VERSION ""

NS_ :

BS_:

BU_: VCM TCM OBDScanT2 ECM

BO_ 531 VCM_HorizonData_C02: 8 VCM
 SG_ HorizonData : 7|64@0+ (1,0) [0|0] ""  TCM

BO_ 1414 VCM_GPSData_C02: 24 VCM
 SG_ GPSData_sg_UB : 163|1@1+ (1,0) [0|1] ""  ECM,TCM
 SG_ GPSData_Altitude : 144|16@1+ (0.125,-2500) [-2500|5691.875] "m"  ECM,TCM
 SG_ GPSData_Time : 64|32@1+ (1,0) [0|4294967295] "s"  TCM,ECM
 SG_ GPSData_AntennaStat : 160|3@1+ (1,0) [0|0] ""  TCM,ECM
 SG_ GPSData_HDOP : 112|16@1+ (0.01,0) [0|655.35] ""  ECM,TCM
 SG_ GPSData_Longitude : 0|32@1+ (1E-007,-210) [-210|219.4967295] "deg"  ECM,TCM
 SG_ GPSData_Latitude : 32|32@1+ (1E-007,-210) [-210|219.4967295] "deg"  ECM,TCM
 SG_ GPSData_Direction : 96|16@1+ (0.0078125,0) [0|511.9921875] "deg"  TCM,ECM
 SG_ GPSData_VehSpeed : 128|16@1+ (0.00390625,0) [0|255.99609375] "Km_per_h"  TCM,ECM

BO_ 940 VCM_EnginestartAuth_C02: 16 VCM
 SG_ EngineStartAuth_stat : 0|128@1+ (1,0) [0|0] ""  ECM

BO_ 935 VCM_EncryptedGBunlock_C02: 16 VCM
 SG_ EncryptedGBUnlockAuth_stat : 0|128@1+ (1,0) [0|0] ""  TCM

BO_ 518 VCM_AdasisMapdata_C02: 8 VCM
 SG_ AdasisMapData : 7|64@0+ (1,0) [0|0] ""  TCM

BO_ 2671902706 TesterFuncDiagMsg_C02: 8 VCM
 SG_ FuncDiagDataTester_ISig_2 : 0|64@1+ (1,0) [0|0] ""  TCM,ECM

BO_ 2671902708 TesterFuncDiagMsgF4_C02: 8 VCM
 SG_ FuncDiagDataIntTesterF4_ISig_2 : 0|64@1+ (1,0) [0|0] ""  ECM,TCM

BO_ 1252 TECU_BB2_11P_FCM: 8 VCM
 SG_ TECU_BB2_11P_FCS : 0|64@1+ (1,0) [0|0] ""  TCM

BO_ 1251 TECU_BB2_11P: 284 TCM
 SG_ HillDataPkgTECU : 0|2272@1+ (1,0) [0|0] ""  VCM

BO_ 1463 TECU_BB2_07P: 8 TCM
 SG_ TECU_Available_Log : 0|8@1+ (1,0) [0|0] ""  VCM

BO_ 1445 TECU_BB2_06S: 12 TCM
 SG_ ECU5VIN_stat : 0|88@1+ (1,0) [0|0] ""  VCM

BO_ 938 TECU_BB2_05S: 16 TCM
 SG_ KeyID_EncryptedGBUnlockAuth : 0|128@1+ (1,0) [0|0] ""  VCM

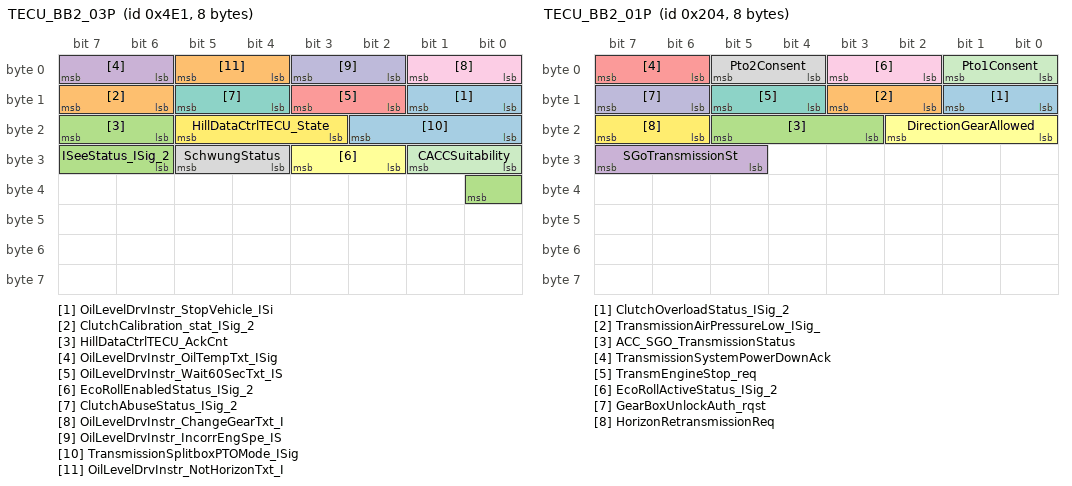
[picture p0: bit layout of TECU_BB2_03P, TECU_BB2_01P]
BO_ 1249 TECU_BB2_03P: 8 TCM
 SG_ OilLevelDrvInstr_StopVehicle_ISi : 8|2@1+ (1,0) [0|0] ""  VCM
 SG_ ClutchCalibration_stat_ISig_2 : 14|2@1+ (1,0) [0|0] ""  VCM
 SG_ HillDataCtrlTECU_AckCnt : 22|2@1+ (1,0) [0|3] ""  VCM
 SG_ OilLevelDrvInstr_OilTempTxt_ISig : 6|2@1+ (1,0) [0|0] ""  VCM
 SG_ OilLevelDrvInstr_Wait60SecTxt_IS : 10|2@1+ (1,0) [0|0] ""  VCM
 SG_ EcoRollEnabledStatus_ISig_2 : 26|2@1+ (1,0) [0|0] ""  VCM
 SG_ ClutchAbuseStatus_ISig_2 : 12|2@1+ (1,0) [0|0] ""  VCM
 SG_ SchwungStatus : 28|2@1+ (1,0) [0|0] ""  VCM
 SG_ OilLevelDrvInstr_ChangeGearTxt_I : 0|2@1+ (1,0) [0|0] ""  VCM
 SG_ OilLevelDrvInstr_IncorrEngSpe_IS : 2|2@1+ (1,0) [0|0] ""  VCM
 SG_ CACCSuitability : 24|2@1+ (1,0) [0|0] ""  VCM
 SG_ HillDataCtrlTECU_State : 19|3@1+ (1,0) [0|0] ""  VCM
 SG_ TransmissionSplitboxPTOMode_ISig : 16|3@1+ (1,0) [0|0] ""  VCM
 SG_ OilLevelDrvInstr_NotHorizonTxt_I : 4|2@1+ (1,0) [0|0] ""  VCM
 SG_ ISeeStatus_ISig_2 : 30|3@1+ (1,0) [0|0] ""  VCM

BO_ 1041 TECU_BB2_02P: 24 TCM
 SG_ BrakeInterlockStatus_ISig_2 : 42|2@1+ (1,0) [0|0] ""  VCM
 SG_ AutGearSplitPosition_ISig_2 : 46|3@1+ (1,0) [0|0] ""  VCM
 SG_ AutoWheelBrakesDownshiftSugges_I : 55|2@1+ (1,0) [0|0] ""  VCM
 SG_ GearShiftingRec_Direction_ISig_2 : 49|3@1+ (1,0) [0|0] ""  VCM
 SG_ DriveModeSwitchUserOverride_ISig : 80|3@1+ (1,0) [0|0] ""  VCM
 SG_ TransmissionBrakeMode_ISig_2 : 60|2@1+ (1,0) [0|0] ""  VCM
 SG_ WheelSpdReverseCapMin : 72|8@1+ (0.1,-25) [-25|0.5] "Km_per_h"  VCM
 SG_ DrivingMode : 0|16@1+ (1,0) [0|0] ""  VCM
 SG_ KickDownModeActive : 44|2@1+ (1,0) [0|0] ""  VCM
 SG_ ClutchWearStatus : 16|8@1+ (0.4,0) [0|102] "Percent"  VCM
 SG_ AutoWheelBrakeInhibited : 38|2@1+ (1,0) [0|0] ""  VCM,ECM
 SG_ TransmissionDrivingMode_ISig_2 : 57|3@1+ (1,0) [0|0] ""  VCM
 SG_ TrafficSitPathExecSta_Distance : 101|14@1+ (1,0) [0|16383] "m"  VCM
 SG_ FuelEcoDrvStatus : 40|2@1+ (1,0) [0|0] ""  VCM
 SG_ TransmissionOilTempHigh_ISig_2 : 35|3@1+ (1,0) [0|0] ""  VCM
 SG_ AvailableGearsWithLowerRatio_ISi : 24|4@1+ (1,0) [0|15] "Count"  VCM
 SG_ TrafficSitPathExecSta_Type : 83|8@1+ (1,0) [0|0] ""  VCM
 SG_ EcoCruiseStatus : 32|3@1+ (1,0) [0|0] ""  ECM,VCM
 SG_ AvailableGearsWithHigherRatio_IS : 28|4@1+ (1,0) [0|15] "Count"  VCM
 SG_ WheelSpdForwardCapMin : 64|8@1+ (0.1,0) [0|25.5] "Km_per_h"  VCM
 SG_ TrafficSitPathExecSta_Speed : 91|10@1+ (0.25,0) [0|255.75] "Km_per_h"  VCM
 SG_ GearShiftingRec_Steps_ISig_2 : 52|3@1+ (1,0) [0|0] ""  VCM

BO_ 516 TECU_BB2_01P: 8 TCM
 SG_ ClutchOverloadStatus_ISig_2 : 8|2@1+ (1,0) [0|0] ""  VCM
 SG_ TransmissionAirPressureLow_ISig_ : 10|2@1+ (1,0) [0|0] ""  VCM
 SG_ ACC_SGO_TransmissionStatus : 19|3@1+ (1,0) [0|0] ""  VCM,ECM
 SG_ SGoTransmissionSt : 29|3@1+ (1,0) [0|0] ""  ECM,VCM
 SG_ TransmissionSystemPowerDownAck : 6|2@1+ (1,0) [0|0] ""  VCM
 SG_ DirectionGearAllowed : 16|3@1+ (1,0) [0|0] ""  VCM
 SG_ TransmEngineStop_req : 12|2@1+ (1,0) [0|0] ""  VCM,ECM
 SG_ Pto2Consent : 4|2@1+ (1,0) [0|0] ""  VCM
 SG_ EcoRollActiveStatus_ISig_2 : 2|2@1+ (1,0) [0|0] ""  VCM
 SG_ GearBoxUnlockAuth_rqst : 14|2@1+ (1,0) [0|0] ""  VCM
 SG_ Pto1Consent : 0|2@1+ (1,0) [0|0] ""  VCM
 SG_ HorizonRetransmissionReq : 22|2@1+ (1,0) [0|0] ""  VCM

BO_ 522 TCM_P02_C02: 8 TCM
 SG_ TransmEstimatedTimeToShift : 0|16@1+ (0.00390625,0) [0|255.99609375] "s"  VCM

BO_ 2671833624 PhysDiagRespMsg_F2_18_C02: 8 TCM
 SG_ PhysDiagRespSig_F2_18_ISig_2 : 0|64@1+ (1,0) [0|0] ""  VCM

BO_ 2671833616 PhysDiagRespMsg_F2_10_C02: 8 ECM
 SG_ PhysDiagRespSig_F2_10_ISig_2 : 0|64@1+ (1,0) [0|0] ""  VCM

BO_ 2564485392 PhysDiagRespMsg_F1_10_extra_C02: 8 ECM
 SG_ PhysDiagRespSig_F1_10_extra : 0|64@1+ (1,0) [0|0] ""  OBDScanT2

BO_ 2671833360 PhysDiagRespMsg_F1_10_C02: 8 ECM
 SG_ PhysDiagRespSig_F1_10_ISig_2 : 0|64@1+ (1,0) [0|0] ""  VCM

BO_ 2671778034 PhysDiagReqMsg_18_F2_C02: 8 VCM
 SG_ PhysDiagReqSig_18_F2_ISig_2 : 0|64@1+ (1,0) [0|0] ""  TCM

BO_ 2671775986 PhysDiagReqMsg_10_F2_C02: 8 VCM
 SG_ PhysDiagReqSig_10_F2_ISig_2 : 0|64@1+ (1,0) [0|0] ""  ECM

BO_ 2564428017 PhysDiagReqMsg_10_F1_extra_C02: 8 OBDScanT2
 SG_ PhysDiagReqSig_10_F1_extra : 0|64@1+ (1,0) [0|0] ""  ECM

BO_ 2671775985 PhysDiagReqMsg_10_F1_C02: 8 VCM
 SG_ PhysDiagReqSig_10_F1_ISig_2 : 0|64@1+ (1,0) [0|0] ""  ECM

BO_ 2564502513 OBDFuncDiagMsg_extra_C02: 8 OBDScanT2
 SG_ FuncDiagDataOBD_extra : 0|64@1+ (1,0) [0|0] ""  ECM

BO_ 2671850481 OBDFuncDiagMsg_C02: 8 VCM
 SG_ FuncDiagDataOBD_ISig_2 : 0|64@1+ (1,0) [0|0] ""  ECM

BO_ 2633990180 NmAsr_VCM_C02: 1 VCM

BO_ 2633990168 NmAsr_TCM_C02: 1 TCM

BO_ 2633990160 NmAsr_ECM_C02: 1 ECM

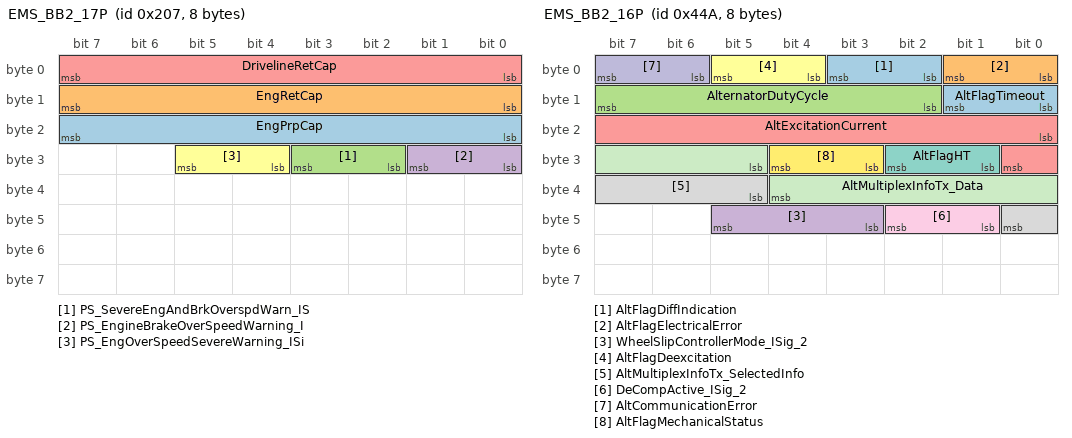
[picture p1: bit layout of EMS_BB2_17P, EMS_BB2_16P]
BO_ 519 EMS_BB2_17P: 8 ECM
 SG_ EngPrpCap : 16|8@1+ (1,-125) [-125|130] "Percent"  VCM
 SG_ EngRetCap : 8|8@1+ (1,-125) [-125|130] "Percent"  VCM
 SG_ PS_SevereEngAndBrkOverspdWarn_IS : 26|2@1+ (1,0) [0|0] ""  VCM
 SG_ PS_EngineBrakeOverSpeedWarning_I : 24|2@1+ (1,0) [0|0] ""  VCM
 SG_ DrivelineRetCap : 0|8@1+ (1,-125) [-125|130] "Percent"  VCM
 SG_ PS_EngOverSpeedSevereWarning_ISi : 28|2@1+ (1,0) [0|0] ""  VCM

BO_ 1098 EMS_BB2_16P: 8 ECM
 SG_ AltFlagDiffIndication : 2|2@1+ (1,0) [0|0] ""  VCM
 SG_ AltFlagElectricalError : 0|2@1+ (1,0) [0|0] ""  VCM
 SG_ AlternatorDutyCycle : 10|6@1+ (3.2258,0) [0|203.2254] "Percent"  VCM
 SG_ WheelSlipControllerMode_ISig_2 : 43|3@1+ (1,0) [0|0] ""  VCM
 SG_ AltExcitationCurrent : 16|9@1+ (0.05,0) [0|25.55] "A"  VCM
 SG_ AltFlagDeexcitation : 4|2@1+ (1,0) [0|0] ""  VCM
 SG_ AltFlagHT : 25|2@1+ (1,0) [0|0] ""  VCM
 SG_ AltMultiplexInfoTx_SelectedInfo : 37|4@1+ (1,0) [0|0] ""  VCM
 SG_ DeCompActive_ISig_2 : 41|2@1+ (1,0) [0|0] ""  VCM
 SG_ AltCommunicationError : 6|2@1+ (1,0) [0|0] ""  VCM
 SG_ AltMultiplexInfoTx_Data : 29|8@1+ (1,0) [0|0] ""  VCM
 SG_ AltFlagMechanicalStatus : 27|2@1+ (1,0) [0|0] ""  VCM
 SG_ AltFlagTimeout : 8|2@1+ (1,0) [0|0] ""  VCM

BO_ 1288 EMS_BB2_15P: 48 ECM
 SG_ EcoCruisePwtMaxOvSpeedLev2_ISig_ : 5|5@1+ (1,0) [0|31] "Km_per_h"  VCM
 SG_ EcoCruisePwtMaxOvSpeedLev0_ISig_ : 0|5@1+ (1,0) [0|31] "Km_per_h"  VCM
 SG_ AdblueTotalConsumed : 232|32@1+ (0.01,0) [0|42949672.95] "l"  VCM
 SG_ TotPTOLNGHighAccuracy : 64|32@1+ (0.01,0) [0|42949672.95] "kg"  VCM
 SG_ EcoCruisePwtMaxUnSpeedLev2_ISig_ : 43|5@1+ (1,0) [0|31] "Km_per_h"  VCM
 SG_ TimeLeftToVehSpdReductionFuel_IS : 137|9@1+ (15,0) [0|7665] "min"  VCM
 SG_ MIDistinctWarningExtEMS_ISig_2 : 169|4@1+ (1,0) [0|0] ""  VCM
 SG_ EcoCruisePwtMaxOvSpeedLev1_ISig_ : 11|5@1+ (1,0) [0|31] "Km_per_h"  VCM
 SG_ EcoCruisePwtMaxUnSpeedLev0_ISig_ : 32|5@1+ (1,0) [0|31] "Km_per_h"  VCM
 SG_ TopGearUseDistance_ISig_2 : 200|32@1+ (0.01,0) [0|42949672.95] "km"  VCM
 SG_ TorqueReductionStatus_OBD_ISig_2 : 164|3@1+ (1,0) [0|0] ""  VCM
 SG_ TimeLeftToTorqueReductionFuel_IS : 128|9@1+ (12,0) [0|6132] "min"  VCM
 SG_ OBDDrivingCycle : 48|16@1+ (1,0) [0|0] ""  VCM
 SG_ TimetoCompleteParkRegen_ISig_2 : 146|9@1+ (15,0) [0|7665] "min"  VCM
 SG_ MIStatus : 173|2@1+ (1,0) [0|0] ""  VCM
 SG_ SCROperatorInducementSeverity_IS : 180|3@1+ (1,0) [0|0] ""  VCM
 SG_ TimeLeftToTorqueReduction_OBD_IS : 155|9@1+ (12,0) [0|6132] "min"  VCM
 SG_ EMS_Available_Log : 192|8@1+ (1,0) [0|0] ""  VCM
 SG_ FuelOperatorDeratingSeverity_ISi : 40|3@1+ (1,0) [0|0] ""  VCM
 SG_ MIDistinctWarning_ISig_2 : 167|2@1+ (1,0) [0|0] ""  VCM
 SG_ SCROperatorInducementReason_ISig : 177|3@1+ (1,0) [0|0] ""  VCM
 SG_ StarterMotorActivations : 96|32@1+ (1,0) [0|4294967295] "Count"  VCM
 SG_ EcoCruisePwtMaxUnSpeedLev1_ISig_ : 21|5@1+ (1,0) [0|31] "Km_per_h"  VCM
 SG_ MIStatusExtEMS_ISig_2 : 175|2@1+ (1,0) [0|0] ""  VCM
 SG_ EcoCruisePwtMaxUnSpeedLev3_ISig_ : 27|5@1+ (1,0) [0|31] "Km_per_h"  VCM
 SG_ EcoCruisePwtMaxOvSpeedLev3_ISig_ : 16|5@1+ (1,0) [0|31] "Km_per_h"  VCM
 SG_ DistLeftToSevereInducement_OBD_I : 184|8@1+ (5,0) [0|1275] "km"  VCM
 SG_ FuelOperatorDeratingReason_ISig_ : 38|2@1+ (1,0) [0|0] ""  VCM

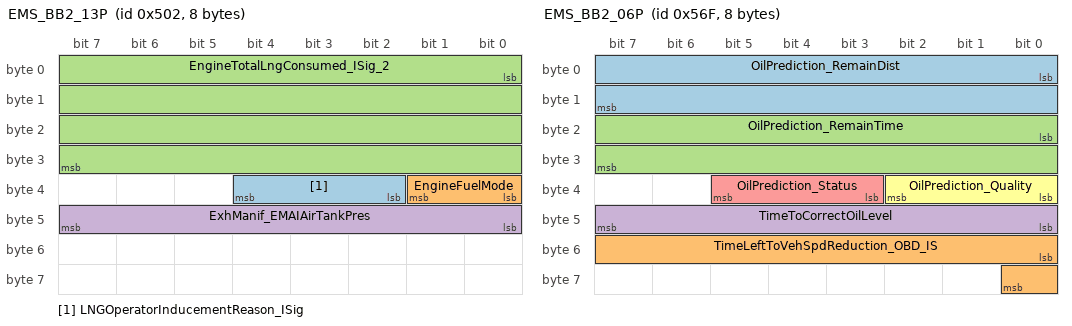
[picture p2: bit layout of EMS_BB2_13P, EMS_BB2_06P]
BO_ 1282 EMS_BB2_13P: 8 ECM
 SG_ LNGOperatorInducementReason_ISig : 34|3@1+ (1,0) [0|0] ""  VCM
 SG_ EngineFuelMode : 32|2@1+ (1,0) [0|0] ""  VCM
 SG_ EngineTotalLngConsumed_ISig_2 : 0|32@1+ (0.01,0) [0|42949672.95] "kg"  VCM
 SG_ ExhManif_EMAIAirTankPres : 40|8@1+ (8,0) [0|2040] "kPa"  VCM

BO_ 958 EMS_BB2_11S: 16 ECM
 SG_ KeyID_EngineStartAuth : 0|128@1+ (1,0) [0|0] ""  VCM

BO_ 1341 EMS_BB2_09S: 12 ECM
 SG_ ECU4VIN_stat : 0|88@1+ (1,0) [0|0] ""  VCM

BO_ 1392 EMS_BB2_08P: 8 ECM
 SG_ EngineRunningTime_ISig_2 : 0|32@1+ (1,0) [0|4294967295] "s"  VCM
 SG_ TotPTOFuelHighAccuracy : 32|32@1+ (0.01,0) [0|42949672.95] "l"  VCM

BO_ 1391 EMS_BB2_06P: 8 ECM
 SG_ OilPrediction_RemainDist : 0|16@1+ (10,0) [0|655350] "km"  VCM
 SG_ TimeLeftToVehSpdReduction_OBD_IS : 48|9@1+ (15,0) [0|7665] "min"  VCM
 SG_ OilPrediction_RemainTime : 16|16@1+ (1,0) [0|65535] "h"  VCM
 SG_ TimeToCorrectOilLevel : 40|8@1+ (1,0) [0|255] "min"  VCM
 SG_ OilPrediction_Status : 35|3@1+ (1,0) [0|0] ""  VCM
 SG_ OilPrediction_Quality : 32|3@1+ (1,0) [0|0] ""  VCM

BO_ 1279 EMS_BB2_03P: 24 ECM
 SG_ AirFilterPressureDrop : 3|3@1+ (1,0) [0|0] ""  VCM
 SG_ EngineTotalFuelConsumed_ISig_2 : 96|32@1+ (0.01,0) [0|42949672.95] "l"  VCM,TCM
 SG_ FuelFilterClogged_ISig_2 : 0|3@1+ (1,0) [0|0] ""  VCM
 SG_ CoolantPumpEngagementStatus_ISig : 184|8@1+ (0.4,0) [0|102] "Percent"  VCM
 SG_ BarometricPressure_ISig_2 : 80|8@1+ (0.5,0) [0|127.5] "kPa"  TCM,VCM
 SG_ StarterMotorRecoveryTime_ISig_2 : 16|16@1+ (1,0) [0|65535] "s"  VCM
 SG_ CoolantTempGaugeAdjustment_ISig_ : 56|8@1+ (0.4,0) [0|102] "Percent"  VCM
 SG_ DrainPrimingStatus_ISig_2 : 72|3@1+ (1,0) [0|0] ""  VCM
 SG_ CoolantLevelLow : 64|3@1+ (1,0) [0|0] ""  VCM
 SG_ AverageFuelEconomy_ISig_2 : 128|16@1+ (0.00390625,0) [0|255.99609375] "miles_per_gallon"  VCM
 SG_ EngineProtDerateStat : 6|2@1+ (1,0) [0|0] ""  VCM
 SG_ EngineAirInletTemperature : 8|8@1+ (1,-40) [-40|215] "DegreeC"  VCM
 SG_ FuelEcoEngStatus : 176|2@1+ (1,0) [0|0] ""  VCM
 SG_ OilLevelLow_ISig_2 : 88|3@1+ (1,0) [0|0] ""  VCM
 SG_ AutoWheelBrakesStatus_ISig_2 : 91|3@1+ (1,0) [0|0] ""  VCM,TCM
 SG_ EngineFanOverspeed_ISig_2 : 48|2@1+ (1,0) [0|0] ""  VCM
 SG_ InletAirHeaterStatus1_ISig_2 : 70|2@1+ (1,0) [0|0] ""  VCM
 SG_ TopGearMode : 78|2@1+ (1,0) [0|0] ""  VCM
 SG_ CoolantTempHigh_ISig_2 : 67|3@1+ (1,0) [0|0] ""  VCM
 SG_ AppliedVehicleSpeedLimit : 32|16@1+ (0.00390625,0) [0|255.99609375] "Km_per_h"  TCM,VCM
 SG_ EnergyForNextCrank_ISig_2 : 52|4@1+ (1,0) [0|15] "Wh"  VCM
 SG_ OilPressureLow_ISig_2 : 75|3@1+ (1,0) [0|0] ""  VCM
 SG_ DPF_ParkedRegenStatus_ISig_2 : 178|3@1+ (1,0) [0|0] ""  VCM
 SG_ StarterMotorReset_ack : 50|2@1+ (1,0) [0|0] ""  VCM
 SG_ EngineCoolingFanSpeed_ISig_2 : 144|16@1+ (1,0) [0|65535] "rpm"  VCM
 SG_ EngineGasRate : 160|16@1+ (0.05,0) [0|3276.75] "Kg_per_h"  VCM
 SG_ DMSDriverFollow : 182|2@1+ (1,0) [0|0] ""  VCM

BO_ 719 EMS_BB2_01P: 16 ECM
 SG_ XARActiveControlMode : 58|3@1+ (1,0) [0|0] ""  VCM
 SG_ WarmUpCycle : 21|2@1+ (1,0) [0|0] ""  VCM
 SG_ DeterminedGear : 48|8@1+ (1,-125) [-125|130] "GearValue"  VCM
 SG_ DPF_LimitedSpeedDuetoInhibit_ISi : 77|3@1+ (1,0) [0|0] ""  VCM
 SG_ AirFilter_Pressure : 80|11@1+ (0.01,-10) [-10|10.47] "kPa"  VCM
 SG_ CCControllerMode : 0|3@1+ (1,0) [0|0] ""  VCM
 SG_ ExhManif_AirInjActive : 56|2@1+ (1,0) [0|0] ""  VCM
 SG_ AirFilter_AirMassFlowValidated : 91|8@1+ (0.01,0) [0|2.55] "Kg_Per_s"  VCM
 SG_ CCBControllerMode : 11|3@1+ (1,0) [0|0] ""  VCM
 SG_ CCSetSpeedApplied : 40|8@1+ (1,0) [0|255] "Km_per_h"  VCM
 SG_ EngineSystemPowerDownAck : 28|2@1+ (1,0) [0|0] ""  VCM
 SG_ RegenInhibDueHeight_ISig_2 : 62|2@1+ (1,0) [0|0] ""  VCM
 SG_ XARSystemState : 23|2@1+ (1,0) [0|0] ""  VCM
 SG_ EngineStartAuth_rqst : 3|3@1+ (1,0) [0|0] ""  VCM
 SG_ EngCompartmentStopSwitchStat : 6|2@1+ (1,0) [0|0] ""  VCM
 SG_ PwtEngineTmpryStopAllowed : 25|2@1+ (1,0) [0|0] ""  VCM
 SG_ IntakeAirTemperatureAlert : 14|2@1+ (1,0) [0|0] ""  VCM
 SG_ EngineOilTempHigh_ISig_2 : 16|3@1+ (1,0) [0|0] ""  VCM
 SG_ XRSLControllerMode_ISig_2 : 19|2@1+ (1,0) [0|0] ""  VCM
 SG_ InhibitIdleShutdownStatus : 8|3@1+ (1,0) [0|0] ""  VCM
 SG_ CrankcasePressureHigh : 30|2@1+ (1,0) [0|0] ""  VCM
 SG_ CCBSetSpeedApplied : 64|8@1+ (1,0) [0|255] "Km_per_h"  VCM
 SG_ EngineAirInletPressure : 32|8@1+ (2,0) [0|510] "kPa"  VCM

BO_ 2671964696 DiagUUDTRespMsg1_F2_18_C02: 8 TCM
 SG_ DiagUUDTRespSig_F2_18_ISig_2 : 0|64@1+ (1,0) [0|0] ""  VCM

BO_ 2671964688 DiagUUDTRespMsg1_F2_10_C02: 8 ECM
 SG_ DiagUUDTRespSig_F2_10_ISig_2 : 0|64@1+ (1,0) [0|0] ""  VCM

BO_ 2671834136 DiagRespMsgForIntTest_F4_18_C02: 8 TCM
 SG_ InternalTesterDiagSig_F4_18 : 0|64@1+ (1,0) [0|0] ""  VCM

BO_ 2671834128 DiagRespMsgForIntTest_F4_10_C02: 8 ECM
 SG_ InternalTesterDiagSig_F4_10 : 0|64@1+ (1,0) [0|0] ""  VCM

BO_ 2671778036 DiagReqMsgOfIntTest_18_F4_C02: 8 VCM
 SG_ InternalTesterDiagSig_18_F4 : 0|64@1+ (1,0) [0|0] ""  TCM

BO_ 2671775988 DiagReqMsgOfIntTest_10_F4_C02: 8 VCM
 SG_ InternalTesterDiagSig_10_F4 : 0|64@1+ (1,0) [0|0] ""  ECM

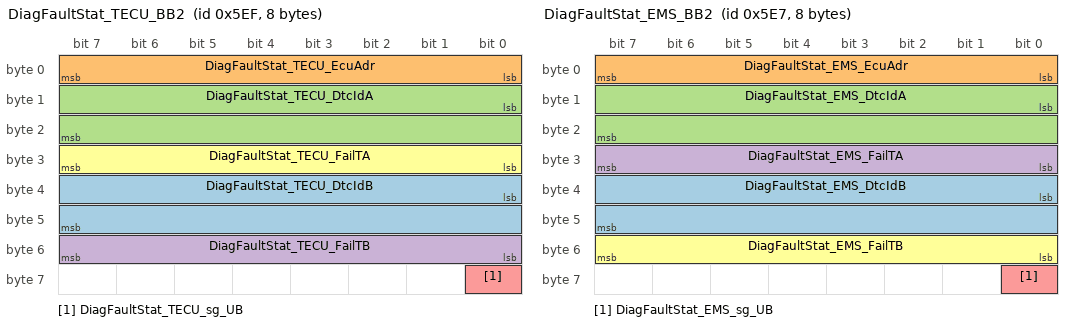
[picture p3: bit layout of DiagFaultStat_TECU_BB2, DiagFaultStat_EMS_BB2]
BO_ 1519 DiagFaultStat_TECU_BB2: 8 TCM
 SG_ DiagFaultStat_TECU_DtcIdB : 32|16@1+ (1,0) [0|65535] ""  VCM
 SG_ DiagFaultStat_TECU_EcuAdr : 0|8@1+ (1,0) [0|255] ""  VCM
 SG_ DiagFaultStat_TECU_DtcIdA : 8|16@1+ (1,0) [0|65535] ""  VCM
 SG_ DiagFaultStat_TECU_FailTB : 48|8@1+ (1,0) [0|255] ""  VCM
 SG_ DiagFaultStat_TECU_sg_UB : 56|1@1+ (1,0) [0|0] ""  VCM
 SG_ DiagFaultStat_TECU_FailTA : 24|8@1+ (1,0) [0|255] ""  VCM

BO_ 1511 DiagFaultStat_EMS_BB2: 8 ECM
 SG_ DiagFaultStat_EMS_DtcIdB : 32|16@1+ (1,0) [0|65535] ""  VCM
 SG_ DiagFaultStat_EMS_EcuAdr : 0|8@1+ (1,0) [0|255] ""  VCM
 SG_ DiagFaultStat_EMS_DtcIdA : 8|16@1+ (1,0) [0|65535] ""  VCM
 SG_ DiagFaultStat_EMS_FailTA : 24|8@1+ (1,0) [0|255] ""  VCM
 SG_ DiagFaultStat_EMS_sg_UB : 56|1@1+ (1,0) [0|0] ""  VCM
 SG_ DiagFaultStat_EMS_FailTB : 48|8@1+ (1,0) [0|255] ""  VCM

BO_ 1698 AnmMsg_VCM_C02: 8 VCM
 SG_ AnmSig_VCM_CAN02 : 0|32@1+ (1,0) [0|0] ""  TCM,ECM

BO_ 1696 AnmMsg_TCM_C02: 8 TCM
 SG_ AnmSig_TCM_CAN02 : 0|32@1+ (1,0) [0|0] ""  ECM,VCM

BO_ 1697 AnmMsg_ECM_C02: 8 ECM
 SG_ AnmSig_ECM_CAN02 : 0|32@1+ (1,0) [0|0] ""  VCM,TCM

CM_ SG_ 1414 GPSData_Time "4261412864 - 4278190079 Error ; 4278190080 - 4294967295 Not available";
CM_ SG_ 1414 GPSData_Longitude "4261412864-4278190079 Error ; 4278190080-4294967295 Not available";
CM_ SG_ 1414 GPSData_Latitude "4261412864-4278190079 Error ; 4278190080-4294967295 Not available";
CM_ SG_ 1414 GPSData_VehSpeed "65024 - 65279 Error ; 65280 - 65535 Not available";
CM_ SG_ 1391 OilPrediction_RemainDist "65024 - 65279 Error ; 65280 - 65535 Not available";
CM_ SG_ 1391 OilPrediction_RemainTime "65024 - 65279 Error ; 65280 - 65535 Not available";
BA_DEF_ BO_  "GenMsgStartDelayTime" INT 0 0;
BA_DEF_ BO_  "GenMsgDelayTime" INT 0 0;
BA_DEF_ BO_  "GenMsgCycleTime" INT 0 0;
BA_DEF_ BO_  "GenMsgSendType" ENUM  "Cyclic","NotUsed","NotUsed","NotUsed","NotUsed","NotUsed","NotUsed","IfActive","NoMsgSendType","NotUsed";
BA_DEF_ SG_  "GenSigStartValue" INT 0 0;
BA_DEF_ SG_  "GenSigCycleTimeActive" INT 0 0;
BA_DEF_ SG_  "GenSigCycleTime" INT 0 0;
BA_DEF_ SG_  "GenSigSendType" ENUM  "Cyclic","OnWrite","OnWriteWithRepetition","OnChange","OnChangeWithRepetition","IfActive","IfActiveWithRepetition","NoSigSendType","NotUsed","NotUsed","NotUsed","NotUsed","NotUsed";
BA_DEF_ BO_  "VFrameFormat" ENUM  "StandardCAN","ExtendedCAN","reserved","J1939PG","reserved","reserved","reserved","reserved","reserved","reserved","reserved","reserved","reserved","reserved","StandardCAN_FD","ExtendedCAN_FD";
BA_DEF_ SG_  "SigType" ENUM  "Default","Range","RangeSigned","ASCII","Discrete","Control","ReferencePGN","DTC","StringDelimiter","StringLength","StringLengthControl";
BA_DEF_ SG_  "SeToolVersion_SIGNAL" STRING ;
BA_DEF_ SG_  "SeToolUniqueID_SIGNAL" STRING ;
BA_DEF_ SG_  "SeToolOwnerSigGroup_SIGNAL" STRING ;
BA_DEF_ SG_  "SeToolOwnerSigGroupID_SIGNAL" STRING ;
BA_DEF_ SG_  "SeToolName_SIGNAL" STRING ;
BA_DEF_ SG_  "SeToolItemID_SIGNAL" STRING ;
BA_DEF_ SG_  "SeToolAncestorID_SIGNAL" STRING ;
BA_DEF_ SG_  "Platform_VMCU1_Sig" ENUM  "No","Yes";
BA_DEF_ BO_  "NmAsrMessage" ENUM  "No","Yes";
BA_DEF_ SG_  "MmAnSignal" ENUM  "No","Yes";
BA_DEF_ SG_  "GenSigMaxLatency" INT 0 65535;
BA_DEF_ SG_  "GenSigILSupport" ENUM  "Yes","No";
BA_DEF_ BO_  "GenMsgILSupport" ENUM  "No","Yes";
BA_DEF_ SG_  "E2EProfile" STRING ;
BA_DEF_ SG_  "E2EDataLength" INT 0 65535;
BA_DEF_ SG_  "E2EDataId" INT 0 65535;
BA_DEF_ BO_  "DiagUUDTResponse" ENUM  "No","Yes";
BA_DEF_ BO_  "DiagState" ENUM  "No","Yes";
BA_DEF_ BO_  "DiagResponse" ENUM  "No","Yes";
BA_DEF_ BO_  "DiagRequest" ENUM  "No","Yes";
BA_DEF_ BO_  "DiagConnection" HEX 0 65535;
BA_DEF_ BO_  "CanTpFcFrameId" HEX 0 2147483647;
BA_DEF_ BO_  "CanTpBs" INT 0 255;
BA_DEF_ BO_  "CANFD_BRS" ENUM  "0","1";
BA_DEF_ SG_  "SystemSignalLongSymbol" STRING ;
BA_DEF_REL_ BU_SG_REL_  "GenSigTimeoutTime" INT 0 65535;
BA_DEF_REL_ BU_SG_REL_  "GenSigFirstTimeoutTime" INT 0 65535;
BA_DEF_DEF_  "GenMsgStartDelayTime" 0;
BA_DEF_DEF_  "GenMsgDelayTime" 0;
BA_DEF_DEF_  "GenMsgCycleTime" 0;
BA_DEF_DEF_  "GenMsgSendType" "Cyclic";
BA_DEF_DEF_  "GenSigStartValue" 0;
BA_DEF_DEF_  "GenSigCycleTimeActive" 0;
BA_DEF_DEF_  "GenSigCycleTime" 0;
BA_DEF_DEF_  "GenSigSendType" "Cyclic";
BA_DEF_DEF_  "VFrameFormat" "ExtendedCAN";
BA_DEF_DEF_  "SigType" "Default";
BA_DEF_DEF_  "SeToolVersion_SIGNAL" "";
BA_DEF_DEF_  "SeToolUniqueID_SIGNAL" "";
BA_DEF_DEF_  "SeToolOwnerSigGroup_SIGNAL" "";
BA_DEF_DEF_  "SeToolOwnerSigGroupID_SIGNAL" "";
BA_DEF_DEF_  "SeToolName_SIGNAL" "";
BA_DEF_DEF_  "SeToolItemID_SIGNAL" "";
BA_DEF_DEF_  "SeToolAncestorID_SIGNAL" "";
BA_DEF_DEF_  "Platform_VMCU1_Sig" "No";
BA_DEF_DEF_  "NmAsrMessage" "No";
BA_DEF_DEF_  "MmAnSignal" "No";
BA_DEF_DEF_  "GenSigMaxLatency" 0;
BA_DEF_DEF_  "GenSigILSupport" "Yes";
BA_DEF_DEF_  "GenMsgILSupport" "Yes";
BA_DEF_DEF_  "E2EProfile" "none";
BA_DEF_DEF_  "E2EDataLength" 0;
BA_DEF_DEF_  "E2EDataId" 0;
BA_DEF_DEF_  "DiagUUDTResponse" "No";
BA_DEF_DEF_  "DiagState" "No";
BA_DEF_DEF_  "DiagResponse" "No";
BA_DEF_DEF_  "DiagRequest" "No";
BA_DEF_DEF_  "DiagConnection" 0;
BA_DEF_DEF_  "CanTpFcFrameId" 2147483647;
BA_DEF_DEF_  "CanTpBs" 255;
BA_DEF_DEF_  "CANFD_BRS" "0";
BA_DEF_DEF_REL_ "GenSigTimeoutTime" 0;
BA_DEF_DEF_REL_ "GenSigFirstTimeoutTime" 0;
BA_DEF_DEF_  "SystemSignalLongSymbol" "";
BA_ "CANFD_BRS" BO_ 531 1;
BA_ "GenMsgSendType" BO_ 531 8;
BA_ "GenMsgDelayTime" BO_ 531 10;
BA_ "VFrameFormat" BO_ 531 14;
BA_ "CANFD_BRS" BO_ 1414 1;
BA_ "GenMsgCycleTime" BO_ 1414 500;
BA_ "GenMsgStartDelayTime" BO_ 1414 80;
BA_ "VFrameFormat" BO_ 1414 14;
BA_ "CANFD_BRS" BO_ 940 1;
BA_ "GenMsgSendType" BO_ 940 8;
BA_ "GenMsgDelayTime" BO_ 940 20;
BA_ "VFrameFormat" BO_ 940 14;
BA_ "CANFD_BRS" BO_ 935 1;
BA_ "GenMsgSendType" BO_ 935 8;
BA_ "GenMsgDelayTime" BO_ 935 20;
BA_ "VFrameFormat" BO_ 935 14;
BA_ "CANFD_BRS" BO_ 518 1;
BA_ "GenMsgSendType" BO_ 518 8;
BA_ "GenMsgDelayTime" BO_ 518 20;
BA_ "VFrameFormat" BO_ 518 14;
BA_ "DiagConnection" BO_ 2671902706 61976;
BA_ "DiagState" BO_ 2671902706 1;
BA_ "GenMsgILSupport" BO_ 2671902706 0;
BA_ "GenMsgSendType" BO_ 2671902706 8;
BA_ "DiagConnection" BO_ 2671902708 62719;
BA_ "DiagState" BO_ 2671902708 1;
BA_ "GenMsgILSupport" BO_ 2671902708 0;
BA_ "GenMsgSendType" BO_ 2671902708 8;
BA_ "CANFD_BRS" BO_ 1252 1;
BA_ "GenMsgILSupport" BO_ 1252 0;
BA_ "GenMsgSendType" BO_ 1252 8;
BA_ "VFrameFormat" BO_ 1252 14;
BA_ "CANFD_BRS" BO_ 1251 1;
BA_ "CanTpFcFrameId" BO_ 1251 1252;
BA_ "GenMsgSendType" BO_ 1251 8;
BA_ "GenMsgDelayTime" BO_ 1251 500;
BA_ "GenMsgStartDelayTime" BO_ 1251 50;
BA_ "VFrameFormat" BO_ 1251 14;
BA_ "CANFD_BRS" BO_ 1463 1;
BA_ "GenMsgCycleTime" BO_ 1463 5000;
BA_ "GenMsgStartDelayTime" BO_ 1463 235;
BA_ "VFrameFormat" BO_ 1463 14;
BA_ "CANFD_BRS" BO_ 1445 1;
BA_ "GenMsgSendType" BO_ 1445 8;
BA_ "GenMsgDelayTime" BO_ 1445 110;
BA_ "VFrameFormat" BO_ 1445 14;
BA_ "CANFD_BRS" BO_ 938 1;
BA_ "GenMsgSendType" BO_ 938 8;
BA_ "GenMsgDelayTime" BO_ 938 20;
BA_ "VFrameFormat" BO_ 938 14;
BA_ "CANFD_BRS" BO_ 1249 1;
BA_ "GenMsgCycleTime" BO_ 1249 500;
BA_ "GenMsgStartDelayTime" BO_ 1249 120;
BA_ "VFrameFormat" BO_ 1249 14;
BA_ "CANFD_BRS" BO_ 1041 1;
BA_ "GenMsgCycleTime" BO_ 1041 100;
BA_ "GenMsgStartDelayTime" BO_ 1041 10;
BA_ "VFrameFormat" BO_ 1041 14;
BA_ "CANFD_BRS" BO_ 516 1;
BA_ "GenMsgCycleTime" BO_ 516 25;
BA_ "GenMsgStartDelayTime" BO_ 516 5;
BA_ "VFrameFormat" BO_ 516 14;
BA_ "CANFD_BRS" BO_ 522 1;
BA_ "GenMsgCycleTime" BO_ 522 20;
BA_ "VFrameFormat" BO_ 522 14;
BA_ "DiagConnection" BO_ 2671833624 61976;
BA_ "DiagResponse" BO_ 2671833624 1;
BA_ "GenMsgILSupport" BO_ 2671833624 0;
BA_ "GenMsgSendType" BO_ 2671833624 8;
BA_ "DiagConnection" BO_ 2671833616 61968;
BA_ "DiagResponse" BO_ 2671833616 1;
BA_ "GenMsgILSupport" BO_ 2671833616 0;
BA_ "GenMsgSendType" BO_ 2671833616 8;
BA_ "DiagConnection" BO_ 2564485392 63504;
BA_ "DiagResponse" BO_ 2564485392 1;
BA_ "GenMsgILSupport" BO_ 2564485392 0;
BA_ "GenMsgSendType" BO_ 2564485392 8;
BA_ "DiagConnection" BO_ 2671833360 61712;
BA_ "DiagResponse" BO_ 2671833360 1;
BA_ "GenMsgILSupport" BO_ 2671833360 0;
BA_ "GenMsgSendType" BO_ 2671833360 8;
BA_ "DiagConnection" BO_ 2671778034 61976;
BA_ "DiagRequest" BO_ 2671778034 1;
BA_ "GenMsgILSupport" BO_ 2671778034 0;
BA_ "GenMsgSendType" BO_ 2671778034 8;
BA_ "DiagConnection" BO_ 2671775986 61968;
BA_ "DiagRequest" BO_ 2671775986 1;
BA_ "GenMsgILSupport" BO_ 2671775986 0;
BA_ "GenMsgSendType" BO_ 2671775986 8;
BA_ "DiagConnection" BO_ 2564428017 63504;
BA_ "DiagRequest" BO_ 2564428017 1;
BA_ "GenMsgILSupport" BO_ 2564428017 0;
BA_ "GenMsgSendType" BO_ 2564428017 8;
BA_ "DiagConnection" BO_ 2671775985 61712;
BA_ "DiagRequest" BO_ 2671775985 1;
BA_ "GenMsgILSupport" BO_ 2671775985 0;
BA_ "GenMsgSendType" BO_ 2671775985 8;
BA_ "DiagConnection" BO_ 2564502513 63504;
BA_ "DiagState" BO_ 2564502513 1;
BA_ "GenMsgILSupport" BO_ 2564502513 0;
BA_ "GenMsgSendType" BO_ 2564502513 8;
BA_ "DiagConnection" BO_ 2671850481 61712;
BA_ "DiagState" BO_ 2671850481 1;
BA_ "GenMsgILSupport" BO_ 2671850481 0;
BA_ "GenMsgSendType" BO_ 2671850481 8;
BA_ "CANFD_BRS" BO_ 2633990180 1;
BA_ "GenMsgILSupport" BO_ 2633990180 0;
BA_ "NmAsrMessage" BO_ 2633990180 1;
BA_ "GenMsgSendType" BO_ 2633990180 8;
BA_ "VFrameFormat" BO_ 2633990180 15;
BA_ "CANFD_BRS" BO_ 2633990168 1;
BA_ "GenMsgILSupport" BO_ 2633990168 0;
BA_ "NmAsrMessage" BO_ 2633990168 1;
BA_ "GenMsgSendType" BO_ 2633990168 8;
BA_ "VFrameFormat" BO_ 2633990168 15;
BA_ "CANFD_BRS" BO_ 2633990160 1;
BA_ "GenMsgILSupport" BO_ 2633990160 0;
BA_ "NmAsrMessage" BO_ 2633990160 1;
BA_ "GenMsgSendType" BO_ 2633990160 8;
BA_ "VFrameFormat" BO_ 2633990160 15;
BA_ "CANFD_BRS" BO_ 519 1;
BA_ "GenMsgCycleTime" BO_ 519 20;
BA_ "GenMsgStartDelayTime" BO_ 519 5;
BA_ "VFrameFormat" BO_ 519 14;
BA_ "CANFD_BRS" BO_ 1098 1;
BA_ "GenMsgCycleTime" BO_ 1098 100;
BA_ "GenMsgStartDelayTime" BO_ 1098 10;
BA_ "VFrameFormat" BO_ 1098 14;
BA_ "CANFD_BRS" BO_ 1288 1;
BA_ "GenMsgCycleTime" BO_ 1288 1000;
BA_ "GenMsgStartDelayTime" BO_ 1288 150;
BA_ "VFrameFormat" BO_ 1288 14;
BA_ "CANFD_BRS" BO_ 1282 1;
BA_ "GenMsgCycleTime" BO_ 1282 500;
BA_ "GenMsgStartDelayTime" BO_ 1282 100;
BA_ "VFrameFormat" BO_ 1282 14;
BA_ "CANFD_BRS" BO_ 958 1;
BA_ "GenMsgSendType" BO_ 958 8;
BA_ "GenMsgDelayTime" BO_ 958 85;
BA_ "VFrameFormat" BO_ 958 14;
BA_ "CANFD_BRS" BO_ 1341 1;
BA_ "GenMsgSendType" BO_ 1341 8;
BA_ "GenMsgDelayTime" BO_ 1341 110;
BA_ "VFrameFormat" BO_ 1341 14;
BA_ "CANFD_BRS" BO_ 1392 1;
BA_ "GenMsgCycleTime" BO_ 1392 1000;
BA_ "GenMsgStartDelayTime" BO_ 1392 60;
BA_ "VFrameFormat" BO_ 1392 14;
BA_ "CANFD_BRS" BO_ 1391 1;
BA_ "GenMsgCycleTime" BO_ 1391 1500;
BA_ "GenMsgStartDelayTime" BO_ 1391 250;
BA_ "VFrameFormat" BO_ 1391 14;
BA_ "CANFD_BRS" BO_ 1279 1;
BA_ "GenMsgCycleTime" BO_ 1279 250;
BA_ "GenMsgStartDelayTime" BO_ 1279 5;
BA_ "VFrameFormat" BO_ 1279 14;
BA_ "CANFD_BRS" BO_ 719 1;
BA_ "GenMsgCycleTime" BO_ 719 50;
BA_ "GenMsgStartDelayTime" BO_ 719 20;
BA_ "VFrameFormat" BO_ 719 14;
BA_ "DiagConnection" BO_ 2671964696 61976;
BA_ "DiagUUDTResponse" BO_ 2671964696 1;
BA_ "GenMsgILSupport" BO_ 2671964696 0;
BA_ "GenMsgSendType" BO_ 2671964696 8;
BA_ "DiagConnection" BO_ 2671964688 61968;
BA_ "DiagUUDTResponse" BO_ 2671964688 1;
BA_ "GenMsgILSupport" BO_ 2671964688 0;
BA_ "GenMsgSendType" BO_ 2671964688 8;
BA_ "DiagConnection" BO_ 2671834136 62488;
BA_ "DiagResponse" BO_ 2671834136 1;
BA_ "GenMsgILSupport" BO_ 2671834136 0;
BA_ "GenMsgSendType" BO_ 2671834136 8;
BA_ "DiagConnection" BO_ 2671834128 62480;
BA_ "DiagResponse" BO_ 2671834128 1;
BA_ "GenMsgILSupport" BO_ 2671834128 0;
BA_ "GenMsgSendType" BO_ 2671834128 8;
BA_ "DiagConnection" BO_ 2671778036 62488;
BA_ "DiagRequest" BO_ 2671778036 1;
BA_ "GenMsgILSupport" BO_ 2671778036 0;
BA_ "GenMsgSendType" BO_ 2671778036 8;
BA_ "DiagConnection" BO_ 2671775988 62480;
BA_ "DiagRequest" BO_ 2671775988 1;
BA_ "GenMsgILSupport" BO_ 2671775988 0;
BA_ "GenMsgSendType" BO_ 2671775988 8;
BA_ "CANFD_BRS" BO_ 1519 1;
BA_ "GenMsgCycleTime" BO_ 1519 1000;
BA_ "GenMsgDelayTime" BO_ 1519 85;
BA_ "GenMsgStartDelayTime" BO_ 1519 25;
BA_ "VFrameFormat" BO_ 1519 14;
BA_ "CANFD_BRS" BO_ 1511 1;
BA_ "GenMsgCycleTime" BO_ 1511 1000;
BA_ "GenMsgDelayTime" BO_ 1511 85;
BA_ "GenMsgStartDelayTime" BO_ 1511 25;
BA_ "VFrameFormat" BO_ 1511 14;
BA_ "CANFD_BRS" BO_ 1698 1;
BA_ "GenMsgCycleTime" BO_ 1698 100;
BA_ "VFrameFormat" BO_ 1698 14;
BA_ "CANFD_BRS" BO_ 1696 1;
BA_ "GenMsgCycleTime" BO_ 1696 100;
BA_ "VFrameFormat" BO_ 1696 14;
BA_ "CANFD_BRS" BO_ 1697 1;
BA_ "GenMsgCycleTime" BO_ 1697 100;
BA_ "VFrameFormat" BO_ 1697 14;
BA_ "GenSigSendType" SG_ 531 HorizonData 1;
BA_ "GenSigCycleTime" SG_ 531 HorizonData 100;
BA_ "GenSigCycleTimeActive" SG_ 531 HorizonData 100;
BA_ "GenSigSendType" SG_ 1414 GPSData_sg_UB 7;
BA_ "Platform_VMCU1_Sig" SG_ 1414 GPSData_sg_UB 1;
BA_ "GenSigCycleTime" SG_ 1414 GPSData_Altitude 100;
BA_ "GenSigCycleTimeActive" SG_ 1414 GPSData_Altitude 100;
BA_ "GenSigStartValue" SG_ 1414 GPSData_Altitude 65535;
BA_ "GenSigCycleTime" SG_ 1414 GPSData_Time 100;
BA_ "GenSigCycleTimeActive" SG_ 1414 GPSData_Time 100;
BA_ "GenSigStartValue" SG_ 1414 GPSData_Time 4294967295;
BA_ "GenSigCycleTime" SG_ 1414 GPSData_AntennaStat 100;
BA_ "GenSigCycleTimeActive" SG_ 1414 GPSData_AntennaStat 100;
BA_ "GenSigStartValue" SG_ 1414 GPSData_AntennaStat 7;
BA_ "GenSigCycleTime" SG_ 1414 GPSData_HDOP 100;
BA_ "GenSigCycleTimeActive" SG_ 1414 GPSData_HDOP 100;
BA_ "GenSigCycleTime" SG_ 1414 GPSData_Longitude 100;
BA_ "GenSigCycleTimeActive" SG_ 1414 GPSData_Longitude 100;
BA_ "GenSigStartValue" SG_ 1414 GPSData_Longitude 4294967295;
BA_ "GenSigCycleTime" SG_ 1414 GPSData_Latitude 100;
BA_ "GenSigCycleTimeActive" SG_ 1414 GPSData_Latitude 100;
BA_ "GenSigStartValue" SG_ 1414 GPSData_Latitude 4294967295;
BA_ "GenSigCycleTime" SG_ 1414 GPSData_Direction 100;
BA_ "GenSigCycleTimeActive" SG_ 1414 GPSData_Direction 100;
BA_ "GenSigCycleTime" SG_ 1414 GPSData_VehSpeed 100;
BA_ "GenSigCycleTimeActive" SG_ 1414 GPSData_VehSpeed 100;
BA_ "GenSigStartValue" SG_ 1414 GPSData_VehSpeed 65535;
BA_ "GenSigSendType" SG_ 940 EngineStartAuth_stat 1;
BA_ "GenSigCycleTime" SG_ 940 EngineStartAuth_stat 100;
BA_ "GenSigCycleTimeActive" SG_ 940 EngineStartAuth_stat 100;
BA_ "GenSigSendType" SG_ 935 EncryptedGBUnlockAuth_stat 1;
BA_ "GenSigCycleTime" SG_ 935 EncryptedGBUnlockAuth_stat 100;
BA_ "GenSigCycleTimeActive" SG_ 935 EncryptedGBUnlockAuth_stat 100;
BA_ "GenSigSendType" SG_ 518 AdasisMapData 1;
BA_ "GenSigCycleTime" SG_ 518 AdasisMapData 100;
BA_ "GenSigCycleTimeActive" SG_ 518 AdasisMapData 100;
BA_ "GenSigSendType" SG_ 2671902706 FuncDiagDataTester_ISig_2 7;
BA_ "GenSigSendType" SG_ 2671902708 FuncDiagDataIntTesterF4_ISig_2 7;
BA_ "GenSigSendType" SG_ 1252 TECU_BB2_11P_FCS 7;
BA_ "GenSigSendType" SG_ 1251 HillDataPkgTECU 1;
BA_ "GenSigMaxLatency" SG_ 1251 HillDataPkgTECU 500;
BA_ "GenSigCycleTime" SG_ 1463 TECU_Available_Log 100;
BA_ "GenSigCycleTimeActive" SG_ 1463 TECU_Available_Log 100;
BA_ "GenSigStartValue" SG_ 1463 TECU_Available_Log 255;
BA_ "GenSigSendType" SG_ 1445 ECU5VIN_stat 1;
BA_ "GenSigCycleTime" SG_ 1445 ECU5VIN_stat 100;
BA_ "GenSigCycleTimeActive" SG_ 1445 ECU5VIN_stat 100;
BA_ "GenSigSendType" SG_ 938 KeyID_EncryptedGBUnlockAuth 1;
BA_ "GenSigCycleTime" SG_ 938 KeyID_EncryptedGBUnlockAuth 100;
BA_ "GenSigCycleTimeActive" SG_ 938 KeyID_EncryptedGBUnlockAuth 100;
BA_ "GenSigCycleTime" SG_ 1249 OilLevelDrvInstr_StopVehicle_ISi 100;
BA_ "GenSigCycleTimeActive" SG_ 1249 OilLevelDrvInstr_StopVehicle_ISi 100;
BA_ "GenSigStartValue" SG_ 1249 OilLevelDrvInstr_StopVehicle_ISi 3;
BA_ "SystemSignalLongSymbol" SG_ 1249 OilLevelDrvInstr_StopVehicle_ISi "OilLevelDrvInstr_StopVehicle_ISig_2";
BA_ "GenSigCycleTime" SG_ 1249 ClutchCalibration_stat_ISig_2 100;
BA_ "GenSigCycleTimeActive" SG_ 1249 ClutchCalibration_stat_ISig_2 100;
BA_ "GenSigStartValue" SG_ 1249 ClutchCalibration_stat_ISig_2 3;
BA_ "GenSigCycleTime" SG_ 1249 HillDataCtrlTECU_AckCnt 100;
BA_ "GenSigCycleTimeActive" SG_ 1249 HillDataCtrlTECU_AckCnt 100;
BA_ "GenSigStartValue" SG_ 1249 HillDataCtrlTECU_AckCnt 3;
BA_ "GenSigMaxLatency" SG_ 1249 HillDataCtrlTECU_AckCnt 500;
BA_ "GenSigCycleTime" SG_ 1249 OilLevelDrvInstr_OilTempTxt_ISig 100;
BA_ "GenSigCycleTimeActive" SG_ 1249 OilLevelDrvInstr_OilTempTxt_ISig 100;
BA_ "GenSigStartValue" SG_ 1249 OilLevelDrvInstr_OilTempTxt_ISig 3;
BA_ "SystemSignalLongSymbol" SG_ 1249 OilLevelDrvInstr_OilTempTxt_ISig "OilLevelDrvInstr_OilTempTxt_ISig_2";
BA_ "GenSigCycleTime" SG_ 1249 OilLevelDrvInstr_Wait60SecTxt_IS 100;
BA_ "GenSigCycleTimeActive" SG_ 1249 OilLevelDrvInstr_Wait60SecTxt_IS 100;
BA_ "GenSigStartValue" SG_ 1249 OilLevelDrvInstr_Wait60SecTxt_IS 3;
BA_ "SystemSignalLongSymbol" SG_ 1249 OilLevelDrvInstr_Wait60SecTxt_IS "OilLevelDrvInstr_Wait60SecTxt_ISig_2";
BA_ "GenSigCycleTime" SG_ 1249 EcoRollEnabledStatus_ISig_2 100;
BA_ "GenSigCycleTimeActive" SG_ 1249 EcoRollEnabledStatus_ISig_2 100;
BA_ "GenSigStartValue" SG_ 1249 EcoRollEnabledStatus_ISig_2 3;
BA_ "GenSigCycleTime" SG_ 1249 ClutchAbuseStatus_ISig_2 100;
BA_ "GenSigCycleTimeActive" SG_ 1249 ClutchAbuseStatus_ISig_2 100;
BA_ "GenSigStartValue" SG_ 1249 ClutchAbuseStatus_ISig_2 3;
BA_ "GenSigCycleTime" SG_ 1249 SchwungStatus 100;
BA_ "GenSigCycleTimeActive" SG_ 1249 SchwungStatus 100;
BA_ "GenSigStartValue" SG_ 1249 SchwungStatus 3;
BA_ "GenSigCycleTime" SG_ 1249 OilLevelDrvInstr_ChangeGearTxt_I 100;
BA_ "GenSigCycleTimeActive" SG_ 1249 OilLevelDrvInstr_ChangeGearTxt_I 100;
BA_ "GenSigStartValue" SG_ 1249 OilLevelDrvInstr_ChangeGearTxt_I 3;
BA_ "SystemSignalLongSymbol" SG_ 1249 OilLevelDrvInstr_ChangeGearTxt_I "OilLevelDrvInstr_ChangeGearTxt_ISig_2";
BA_ "GenSigCycleTime" SG_ 1249 OilLevelDrvInstr_IncorrEngSpe_IS 100;
BA_ "GenSigCycleTimeActive" SG_ 1249 OilLevelDrvInstr_IncorrEngSpe_IS 100;
BA_ "GenSigStartValue" SG_ 1249 OilLevelDrvInstr_IncorrEngSpe_IS 3;
BA_ "SystemSignalLongSymbol" SG_ 1249 OilLevelDrvInstr_IncorrEngSpe_IS "OilLevelDrvInstr_IncorrEngSpe_ISig_2";
BA_ "GenSigCycleTime" SG_ 1249 CACCSuitability 100;
BA_ "GenSigCycleTimeActive" SG_ 1249 CACCSuitability 100;
BA_ "GenSigStartValue" SG_ 1249 CACCSuitability 3;
BA_ "GenSigCycleTime" SG_ 1249 HillDataCtrlTECU_State 100;
BA_ "GenSigCycleTimeActive" SG_ 1249 HillDataCtrlTECU_State 100;
BA_ "GenSigStartValue" SG_ 1249 HillDataCtrlTECU_State 7;
BA_ "GenSigMaxLatency" SG_ 1249 HillDataCtrlTECU_State 500;
BA_ "GenSigCycleTime" SG_ 1249 TransmissionSplitboxPTOMode_ISig 100;
BA_ "GenSigCycleTimeActive" SG_ 1249 TransmissionSplitboxPTOMode_ISig 100;
BA_ "GenSigStartValue" SG_ 1249 TransmissionSplitboxPTOMode_ISig 7;
BA_ "SystemSignalLongSymbol" SG_ 1249 TransmissionSplitboxPTOMode_ISig "TransmissionSplitboxPTOMode_ISig_2";
BA_ "GenSigCycleTime" SG_ 1249 OilLevelDrvInstr_NotHorizonTxt_I 100;
BA_ "GenSigCycleTimeActive" SG_ 1249 OilLevelDrvInstr_NotHorizonTxt_I 100;
BA_ "GenSigStartValue" SG_ 1249 OilLevelDrvInstr_NotHorizonTxt_I 3;
BA_ "SystemSignalLongSymbol" SG_ 1249 OilLevelDrvInstr_NotHorizonTxt_I "OilLevelDrvInstr_NotHorizonTxt_ISig_2";
BA_ "GenSigCycleTime" SG_ 1249 ISeeStatus_ISig_2 100;
BA_ "GenSigCycleTimeActive" SG_ 1249 ISeeStatus_ISig_2 100;
BA_ "GenSigStartValue" SG_ 1249 ISeeStatus_ISig_2 7;
BA_ "GenSigCycleTime" SG_ 1041 BrakeInterlockStatus_ISig_2 100;
BA_ "GenSigCycleTimeActive" SG_ 1041 BrakeInterlockStatus_ISig_2 100;
BA_ "GenSigStartValue" SG_ 1041 BrakeInterlockStatus_ISig_2 3;
BA_ "GenSigCycleTime" SG_ 1041 AutGearSplitPosition_ISig_2 100;
BA_ "GenSigCycleTimeActive" SG_ 1041 AutGearSplitPosition_ISig_2 100;
BA_ "GenSigStartValue" SG_ 1041 AutGearSplitPosition_ISig_2 7;
BA_ "GenSigCycleTime" SG_ 1041 AutoWheelBrakesDownshiftSugges_I 100;
BA_ "GenSigCycleTimeActive" SG_ 1041 AutoWheelBrakesDownshiftSugges_I 100;
BA_ "GenSigStartValue" SG_ 1041 AutoWheelBrakesDownshiftSugges_I 3;
BA_ "SystemSignalLongSymbol" SG_ 1041 AutoWheelBrakesDownshiftSugges_I "AutoWheelBrakesDownshiftSugges_ISig_2";
BA_ "GenSigCycleTime" SG_ 1041 GearShiftingRec_Direction_ISig_2 100;
BA_ "GenSigCycleTimeActive" SG_ 1041 GearShiftingRec_Direction_ISig_2 100;
BA_ "GenSigStartValue" SG_ 1041 GearShiftingRec_Direction_ISig_2 7;
BA_ "GenSigCycleTime" SG_ 1041 DriveModeSwitchUserOverride_ISig 100;
BA_ "GenSigCycleTimeActive" SG_ 1041 DriveModeSwitchUserOverride_ISig 100;
BA_ "GenSigStartValue" SG_ 1041 DriveModeSwitchUserOverride_ISig 7;
BA_ "GenSigMaxLatency" SG_ 1041 DriveModeSwitchUserOverride_ISig 101;
BA_ "SystemSignalLongSymbol" SG_ 1041 DriveModeSwitchUserOverride_ISig "DriveModeSwitchUserOverride_ISig_2";
BA_ "GenSigCycleTime" SG_ 1041 TransmissionBrakeMode_ISig_2 100;
BA_ "GenSigCycleTimeActive" SG_ 1041 TransmissionBrakeMode_ISig_2 100;
BA_ "GenSigStartValue" SG_ 1041 TransmissionBrakeMode_ISig_2 3;
BA_ "GenSigCycleTime" SG_ 1041 WheelSpdReverseCapMin 100;
BA_ "GenSigCycleTimeActive" SG_ 1041 WheelSpdReverseCapMin 100;
BA_ "GenSigStartValue" SG_ 1041 WheelSpdReverseCapMin 255;
BA_ "GenSigCycleTime" SG_ 1041 DrivingMode 100;
BA_ "GenSigCycleTimeActive" SG_ 1041 DrivingMode 100;
BA_ "GenSigCycleTime" SG_ 1041 KickDownModeActive 100;
BA_ "GenSigCycleTimeActive" SG_ 1041 KickDownModeActive 100;
BA_ "GenSigStartValue" SG_ 1041 KickDownModeActive 3;
BA_ "GenSigCycleTime" SG_ 1041 ClutchWearStatus 100;
BA_ "GenSigCycleTimeActive" SG_ 1041 ClutchWearStatus 100;
BA_ "GenSigStartValue" SG_ 1041 ClutchWearStatus 255;
BA_ "GenSigCycleTime" SG_ 1041 AutoWheelBrakeInhibited 100;
BA_ "GenSigCycleTimeActive" SG_ 1041 AutoWheelBrakeInhibited 100;
BA_ "GenSigStartValue" SG_ 1041 AutoWheelBrakeInhibited 3;
BA_ "GenSigCycleTime" SG_ 1041 TransmissionDrivingMode_ISig_2 100;
BA_ "GenSigCycleTimeActive" SG_ 1041 TransmissionDrivingMode_ISig_2 100;
BA_ "GenSigStartValue" SG_ 1041 TransmissionDrivingMode_ISig_2 7;
BA_ "GenSigCycleTime" SG_ 1041 TrafficSitPathExecSta_Distance 100;
BA_ "GenSigCycleTimeActive" SG_ 1041 TrafficSitPathExecSta_Distance 100;
BA_ "GenSigStartValue" SG_ 1041 TrafficSitPathExecSta_Distance 16383;
BA_ "GenSigCycleTime" SG_ 1041 FuelEcoDrvStatus 100;
BA_ "GenSigCycleTimeActive" SG_ 1041 FuelEcoDrvStatus 100;
BA_ "GenSigStartValue" SG_ 1041 FuelEcoDrvStatus 3;
BA_ "GenSigCycleTime" SG_ 1041 TransmissionOilTempHigh_ISig_2 100;
BA_ "GenSigCycleTimeActive" SG_ 1041 TransmissionOilTempHigh_ISig_2 100;
BA_ "GenSigStartValue" SG_ 1041 TransmissionOilTempHigh_ISig_2 7;
BA_ "GenSigCycleTime" SG_ 1041 AvailableGearsWithLowerRatio_ISi 100;
BA_ "GenSigCycleTimeActive" SG_ 1041 AvailableGearsWithLowerRatio_ISi 100;
BA_ "GenSigStartValue" SG_ 1041 AvailableGearsWithLowerRatio_ISi 15;
BA_ "SystemSignalLongSymbol" SG_ 1041 AvailableGearsWithLowerRatio_ISi "AvailableGearsWithLowerRatio_ISig_2";
BA_ "GenSigCycleTime" SG_ 1041 TrafficSitPathExecSta_Type 100;
BA_ "GenSigCycleTimeActive" SG_ 1041 TrafficSitPathExecSta_Type 100;
BA_ "GenSigStartValue" SG_ 1041 TrafficSitPathExecSta_Type 255;
BA_ "GenSigCycleTime" SG_ 1041 EcoCruiseStatus 100;
BA_ "GenSigCycleTimeActive" SG_ 1041 EcoCruiseStatus 100;
BA_ "GenSigStartValue" SG_ 1041 EcoCruiseStatus 7;
BA_ "GenSigCycleTime" SG_ 1041 AvailableGearsWithHigherRatio_IS 100;
BA_ "GenSigCycleTimeActive" SG_ 1041 AvailableGearsWithHigherRatio_IS 100;
BA_ "GenSigStartValue" SG_ 1041 AvailableGearsWithHigherRatio_IS 15;
BA_ "SystemSignalLongSymbol" SG_ 1041 AvailableGearsWithHigherRatio_IS "AvailableGearsWithHigherRatio_ISig_2";
BA_ "GenSigCycleTime" SG_ 1041 WheelSpdForwardCapMin 100;
BA_ "GenSigCycleTimeActive" SG_ 1041 WheelSpdForwardCapMin 100;
BA_ "GenSigStartValue" SG_ 1041 WheelSpdForwardCapMin 255;
BA_ "GenSigCycleTime" SG_ 1041 TrafficSitPathExecSta_Speed 100;
BA_ "GenSigCycleTimeActive" SG_ 1041 TrafficSitPathExecSta_Speed 100;
BA_ "GenSigStartValue" SG_ 1041 TrafficSitPathExecSta_Speed 1023;
BA_ "GenSigCycleTime" SG_ 1041 GearShiftingRec_Steps_ISig_2 100;
BA_ "GenSigCycleTimeActive" SG_ 1041 GearShiftingRec_Steps_ISig_2 100;
BA_ "GenSigStartValue" SG_ 1041 GearShiftingRec_Steps_ISig_2 7;
BA_ "GenSigCycleTime" SG_ 516 ClutchOverloadStatus_ISig_2 100;
BA_ "GenSigCycleTimeActive" SG_ 516 ClutchOverloadStatus_ISig_2 100;
BA_ "GenSigStartValue" SG_ 516 ClutchOverloadStatus_ISig_2 3;
BA_ "GenSigCycleTime" SG_ 516 TransmissionAirPressureLow_ISig_ 100;
BA_ "GenSigCycleTimeActive" SG_ 516 TransmissionAirPressureLow_ISig_ 100;
BA_ "GenSigStartValue" SG_ 516 TransmissionAirPressureLow_ISig_ 3;
BA_ "SystemSignalLongSymbol" SG_ 516 TransmissionAirPressureLow_ISig_ "TransmissionAirPressureLow_ISig_2";
BA_ "GenSigCycleTime" SG_ 516 ACC_SGO_TransmissionStatus 100;
BA_ "GenSigCycleTimeActive" SG_ 516 ACC_SGO_TransmissionStatus 100;
BA_ "GenSigStartValue" SG_ 516 ACC_SGO_TransmissionStatus 7;
BA_ "GenSigCycleTime" SG_ 516 SGoTransmissionSt 100;
BA_ "GenSigCycleTimeActive" SG_ 516 SGoTransmissionSt 100;
BA_ "GenSigStartValue" SG_ 516 SGoTransmissionSt 7;
BA_ "GenSigCycleTime" SG_ 516 TransmissionSystemPowerDownAck 100;
BA_ "GenSigCycleTimeActive" SG_ 516 TransmissionSystemPowerDownAck 100;
BA_ "GenSigStartValue" SG_ 516 TransmissionSystemPowerDownAck 3;
BA_ "GenSigMaxLatency" SG_ 516 TransmissionSystemPowerDownAck 100;
BA_ "GenSigCycleTime" SG_ 516 DirectionGearAllowed 100;
BA_ "GenSigCycleTimeActive" SG_ 516 DirectionGearAllowed 100;
BA_ "GenSigStartValue" SG_ 516 DirectionGearAllowed 7;
BA_ "GenSigCycleTime" SG_ 516 TransmEngineStop_req 100;
BA_ "GenSigCycleTimeActive" SG_ 516 TransmEngineStop_req 100;
BA_ "GenSigStartValue" SG_ 516 TransmEngineStop_req 3;
BA_ "GenSigCycleTime" SG_ 516 Pto2Consent 100;
BA_ "GenSigCycleTimeActive" SG_ 516 Pto2Consent 100;
BA_ "GenSigStartValue" SG_ 516 Pto2Consent 3;
BA_ "GenSigCycleTime" SG_ 516 EcoRollActiveStatus_ISig_2 100;
BA_ "GenSigCycleTimeActive" SG_ 516 EcoRollActiveStatus_ISig_2 100;
BA_ "GenSigStartValue" SG_ 516 EcoRollActiveStatus_ISig_2 3;
BA_ "GenSigCycleTime" SG_ 516 GearBoxUnlockAuth_rqst 100;
BA_ "GenSigCycleTimeActive" SG_ 516 GearBoxUnlockAuth_rqst 100;
BA_ "GenSigStartValue" SG_ 516 GearBoxUnlockAuth_rqst 3;
BA_ "GenSigCycleTime" SG_ 516 Pto1Consent 100;
BA_ "GenSigCycleTimeActive" SG_ 516 Pto1Consent 100;
BA_ "GenSigStartValue" SG_ 516 Pto1Consent 3;
BA_ "GenSigCycleTime" SG_ 516 HorizonRetransmissionReq 100;
BA_ "GenSigCycleTimeActive" SG_ 516 HorizonRetransmissionReq 100;
BA_ "GenSigStartValue" SG_ 516 HorizonRetransmissionReq 3;
BA_ "GenSigCycleTime" SG_ 522 TransmEstimatedTimeToShift 100;
BA_ "GenSigCycleTimeActive" SG_ 522 TransmEstimatedTimeToShift 100;
BA_ "GenSigStartValue" SG_ 522 TransmEstimatedTimeToShift 65535;
BA_ "GenSigMaxLatency" SG_ 522 TransmEstimatedTimeToShift 20;
BA_ "GenSigSendType" SG_ 2671833624 PhysDiagRespSig_F2_18_ISig_2 7;
BA_ "GenSigSendType" SG_ 2671833616 PhysDiagRespSig_F2_10_ISig_2 7;
BA_ "GenSigSendType" SG_ 2564485392 PhysDiagRespSig_F1_10_extra 7;
BA_ "GenSigSendType" SG_ 2671833360 PhysDiagRespSig_F1_10_ISig_2 7;
BA_ "GenSigSendType" SG_ 2671778034 PhysDiagReqSig_18_F2_ISig_2 7;
BA_ "GenSigSendType" SG_ 2671775986 PhysDiagReqSig_10_F2_ISig_2 7;
BA_ "GenSigSendType" SG_ 2564428017 PhysDiagReqSig_10_F1_extra 7;
BA_ "GenSigSendType" SG_ 2671775985 PhysDiagReqSig_10_F1_ISig_2 7;
BA_ "GenSigSendType" SG_ 2564502513 FuncDiagDataOBD_extra 7;
BA_ "GenSigSendType" SG_ 2671850481 FuncDiagDataOBD_ISig_2 7;
BA_ "GenSigCycleTime" SG_ 519 EngPrpCap 100;
BA_ "GenSigCycleTimeActive" SG_ 519 EngPrpCap 100;
BA_ "GenSigStartValue" SG_ 519 EngPrpCap 255;
BA_ "GenSigCycleTime" SG_ 519 EngRetCap 100;
BA_ "GenSigCycleTimeActive" SG_ 519 EngRetCap 100;
BA_ "GenSigStartValue" SG_ 519 EngRetCap 255;
BA_ "GenSigCycleTime" SG_ 519 PS_SevereEngAndBrkOverspdWarn_IS 100;
BA_ "GenSigCycleTimeActive" SG_ 519 PS_SevereEngAndBrkOverspdWarn_IS 100;
BA_ "GenSigStartValue" SG_ 519 PS_SevereEngAndBrkOverspdWarn_IS 3;
BA_ "GenSigMaxLatency" SG_ 519 PS_SevereEngAndBrkOverspdWarn_IS 45;
BA_ "SystemSignalLongSymbol" SG_ 519 PS_SevereEngAndBrkOverspdWarn_IS "PS_SevereEngAndBrkOverspdWarn_ISig_2";
BA_ "GenSigCycleTime" SG_ 519 PS_EngineBrakeOverSpeedWarning_I 100;
BA_ "GenSigCycleTimeActive" SG_ 519 PS_EngineBrakeOverSpeedWarning_I 100;
BA_ "GenSigStartValue" SG_ 519 PS_EngineBrakeOverSpeedWarning_I 3;
BA_ "GenSigMaxLatency" SG_ 519 PS_EngineBrakeOverSpeedWarning_I 45;
BA_ "SystemSignalLongSymbol" SG_ 519 PS_EngineBrakeOverSpeedWarning_I "PS_EngineBrakeOverSpeedWarning_ISig_2";
BA_ "GenSigCycleTime" SG_ 519 DrivelineRetCap 100;
BA_ "GenSigCycleTimeActive" SG_ 519 DrivelineRetCap 100;
BA_ "GenSigStartValue" SG_ 519 DrivelineRetCap 255;
BA_ "GenSigCycleTime" SG_ 519 PS_EngOverSpeedSevereWarning_ISi 100;
BA_ "GenSigCycleTimeActive" SG_ 519 PS_EngOverSpeedSevereWarning_ISi 100;
BA_ "GenSigStartValue" SG_ 519 PS_EngOverSpeedSevereWarning_ISi 3;
BA_ "GenSigMaxLatency" SG_ 519 PS_EngOverSpeedSevereWarning_ISi 45;
BA_ "SystemSignalLongSymbol" SG_ 519 PS_EngOverSpeedSevereWarning_ISi "PS_EngOverSpeedSevereWarning_ISig_2";
BA_ "GenSigCycleTime" SG_ 1098 AltFlagDiffIndication 100;
BA_ "GenSigCycleTimeActive" SG_ 1098 AltFlagDiffIndication 100;
BA_ "GenSigStartValue" SG_ 1098 AltFlagDiffIndication 3;
BA_ "GenSigCycleTime" SG_ 1098 AltFlagElectricalError 100;
BA_ "GenSigCycleTimeActive" SG_ 1098 AltFlagElectricalError 100;
BA_ "GenSigStartValue" SG_ 1098 AltFlagElectricalError 3;
BA_ "GenSigCycleTime" SG_ 1098 AlternatorDutyCycle 100;
BA_ "GenSigCycleTimeActive" SG_ 1098 AlternatorDutyCycle 100;
BA_ "GenSigStartValue" SG_ 1098 AlternatorDutyCycle 63;
BA_ "GenSigCycleTime" SG_ 1098 WheelSlipControllerMode_ISig_2 100;
BA_ "GenSigCycleTimeActive" SG_ 1098 WheelSlipControllerMode_ISig_2 100;
BA_ "GenSigStartValue" SG_ 1098 WheelSlipControllerMode_ISig_2 7;
BA_ "GenSigMaxLatency" SG_ 1098 WheelSlipControllerMode_ISig_2 100;
BA_ "GenSigCycleTime" SG_ 1098 AltExcitationCurrent 100;
BA_ "GenSigCycleTimeActive" SG_ 1098 AltExcitationCurrent 100;
BA_ "GenSigStartValue" SG_ 1098 AltExcitationCurrent 511;
BA_ "GenSigCycleTime" SG_ 1098 AltFlagDeexcitation 100;
BA_ "GenSigCycleTimeActive" SG_ 1098 AltFlagDeexcitation 100;
BA_ "GenSigStartValue" SG_ 1098 AltFlagDeexcitation 3;
BA_ "GenSigCycleTime" SG_ 1098 AltFlagHT 100;
BA_ "GenSigCycleTimeActive" SG_ 1098 AltFlagHT 100;
BA_ "GenSigStartValue" SG_ 1098 AltFlagHT 3;
BA_ "GenSigCycleTime" SG_ 1098 AltMultiplexInfoTx_SelectedInfo 100;
BA_ "GenSigCycleTimeActive" SG_ 1098 AltMultiplexInfoTx_SelectedInfo 100;
BA_ "GenSigStartValue" SG_ 1098 AltMultiplexInfoTx_SelectedInfo 15;
BA_ "GenSigCycleTime" SG_ 1098 DeCompActive_ISig_2 100;
BA_ "GenSigCycleTimeActive" SG_ 1098 DeCompActive_ISig_2 100;
BA_ "GenSigStartValue" SG_ 1098 DeCompActive_ISig_2 3;
BA_ "GenSigMaxLatency" SG_ 1098 DeCompActive_ISig_2 100;
BA_ "GenSigCycleTime" SG_ 1098 AltCommunicationError 100;
BA_ "GenSigCycleTimeActive" SG_ 1098 AltCommunicationError 100;
BA_ "GenSigStartValue" SG_ 1098 AltCommunicationError 3;
BA_ "GenSigCycleTime" SG_ 1098 AltMultiplexInfoTx_Data 100;
BA_ "GenSigCycleTimeActive" SG_ 1098 AltMultiplexInfoTx_Data 100;
BA_ "GenSigStartValue" SG_ 1098 AltMultiplexInfoTx_Data 255;
BA_ "GenSigCycleTime" SG_ 1098 AltFlagMechanicalStatus 100;
BA_ "GenSigCycleTimeActive" SG_ 1098 AltFlagMechanicalStatus 100;
BA_ "GenSigStartValue" SG_ 1098 AltFlagMechanicalStatus 3;
BA_ "GenSigCycleTime" SG_ 1098 AltFlagTimeout 100;
BA_ "GenSigCycleTimeActive" SG_ 1098 AltFlagTimeout 100;
BA_ "GenSigStartValue" SG_ 1098 AltFlagTimeout 3;
BA_ "GenSigCycleTime" SG_ 1288 EcoCruisePwtMaxOvSpeedLev2_ISig_ 100;
BA_ "GenSigCycleTimeActive" SG_ 1288 EcoCruisePwtMaxOvSpeedLev2_ISig_ 100;
BA_ "GenSigStartValue" SG_ 1288 EcoCruisePwtMaxOvSpeedLev2_ISig_ 31;
BA_ "SystemSignalLongSymbol" SG_ 1288 EcoCruisePwtMaxOvSpeedLev2_ISig_ "EcoCruisePwtMaxOvSpeedLev2_ISig_2";
BA_ "GenSigCycleTime" SG_ 1288 EcoCruisePwtMaxOvSpeedLev0_ISig_ 100;
BA_ "GenSigCycleTimeActive" SG_ 1288 EcoCruisePwtMaxOvSpeedLev0_ISig_ 100;
BA_ "GenSigStartValue" SG_ 1288 EcoCruisePwtMaxOvSpeedLev0_ISig_ 31;
BA_ "SystemSignalLongSymbol" SG_ 1288 EcoCruisePwtMaxOvSpeedLev0_ISig_ "EcoCruisePwtMaxOvSpeedLev0_ISig_2";
BA_ "GenSigCycleTime" SG_ 1288 AdblueTotalConsumed 100;
BA_ "GenSigCycleTimeActive" SG_ 1288 AdblueTotalConsumed 100;
BA_ "GenSigStartValue" SG_ 1288 AdblueTotalConsumed 4294967295;
BA_ "GenSigCycleTime" SG_ 1288 TotPTOLNGHighAccuracy 100;
BA_ "GenSigCycleTimeActive" SG_ 1288 TotPTOLNGHighAccuracy 100;
BA_ "GenSigStartValue" SG_ 1288 TotPTOLNGHighAccuracy 4294967295;
BA_ "GenSigCycleTime" SG_ 1288 EcoCruisePwtMaxUnSpeedLev2_ISig_ 100;
BA_ "GenSigCycleTimeActive" SG_ 1288 EcoCruisePwtMaxUnSpeedLev2_ISig_ 100;
BA_ "GenSigStartValue" SG_ 1288 EcoCruisePwtMaxUnSpeedLev2_ISig_ 31;
BA_ "SystemSignalLongSymbol" SG_ 1288 EcoCruisePwtMaxUnSpeedLev2_ISig_ "EcoCruisePwtMaxUnSpeedLev2_ISig_2";
BA_ "GenSigCycleTime" SG_ 1288 TimeLeftToVehSpdReductionFuel_IS 100;
BA_ "GenSigCycleTimeActive" SG_ 1288 TimeLeftToVehSpdReductionFuel_IS 100;
BA_ "GenSigStartValue" SG_ 1288 TimeLeftToVehSpdReductionFuel_IS 511;
BA_ "GenSigMaxLatency" SG_ 1288 TimeLeftToVehSpdReductionFuel_IS 1000;
BA_ "SystemSignalLongSymbol" SG_ 1288 TimeLeftToVehSpdReductionFuel_IS "TimeLeftToVehSpdReductionFuel_ISig_2";
BA_ "GenSigCycleTime" SG_ 1288 MIDistinctWarningExtEMS_ISig_2 100;
BA_ "GenSigCycleTimeActive" SG_ 1288 MIDistinctWarningExtEMS_ISig_2 100;
BA_ "GenSigStartValue" SG_ 1288 MIDistinctWarningExtEMS_ISig_2 15;
BA_ "GenSigCycleTime" SG_ 1288 EcoCruisePwtMaxOvSpeedLev1_ISig_ 100;
BA_ "GenSigCycleTimeActive" SG_ 1288 EcoCruisePwtMaxOvSpeedLev1_ISig_ 100;
BA_ "GenSigStartValue" SG_ 1288 EcoCruisePwtMaxOvSpeedLev1_ISig_ 31;
BA_ "SystemSignalLongSymbol" SG_ 1288 EcoCruisePwtMaxOvSpeedLev1_ISig_ "EcoCruisePwtMaxOvSpeedLev1_ISig_2";
BA_ "GenSigCycleTime" SG_ 1288 EcoCruisePwtMaxUnSpeedLev0_ISig_ 100;
BA_ "GenSigCycleTimeActive" SG_ 1288 EcoCruisePwtMaxUnSpeedLev0_ISig_ 100;
BA_ "GenSigStartValue" SG_ 1288 EcoCruisePwtMaxUnSpeedLev0_ISig_ 31;
BA_ "SystemSignalLongSymbol" SG_ 1288 EcoCruisePwtMaxUnSpeedLev0_ISig_ "EcoCruisePwtMaxUnSpeedLev0_ISig_2";
BA_ "GenSigCycleTime" SG_ 1288 TopGearUseDistance_ISig_2 100;
BA_ "GenSigCycleTimeActive" SG_ 1288 TopGearUseDistance_ISig_2 100;
BA_ "GenSigStartValue" SG_ 1288 TopGearUseDistance_ISig_2 4294967295;
BA_ "GenSigCycleTime" SG_ 1288 TorqueReductionStatus_OBD_ISig_2 100;
BA_ "GenSigCycleTimeActive" SG_ 1288 TorqueReductionStatus_OBD_ISig_2 100;
BA_ "GenSigStartValue" SG_ 1288 TorqueReductionStatus_OBD_ISig_2 7;
BA_ "GenSigCycleTime" SG_ 1288 TimeLeftToTorqueReductionFuel_IS 100;
BA_ "GenSigCycleTimeActive" SG_ 1288 TimeLeftToTorqueReductionFuel_IS 100;
BA_ "GenSigStartValue" SG_ 1288 TimeLeftToTorqueReductionFuel_IS 511;
BA_ "GenSigMaxLatency" SG_ 1288 TimeLeftToTorqueReductionFuel_IS 1000;
BA_ "SystemSignalLongSymbol" SG_ 1288 TimeLeftToTorqueReductionFuel_IS "TimeLeftToTorqueReductionFuel_ISig_2";
BA_ "GenSigCycleTime" SG_ 1288 OBDDrivingCycle 100;
BA_ "GenSigCycleTimeActive" SG_ 1288 OBDDrivingCycle 100;
BA_ "GenSigStartValue" SG_ 1288 OBDDrivingCycle 65535;
BA_ "GenSigCycleTime" SG_ 1288 TimetoCompleteParkRegen_ISig_2 100;
BA_ "GenSigCycleTimeActive" SG_ 1288 TimetoCompleteParkRegen_ISig_2 100;
BA_ "GenSigStartValue" SG_ 1288 TimetoCompleteParkRegen_ISig_2 511;
BA_ "GenSigMaxLatency" SG_ 1288 TimetoCompleteParkRegen_ISig_2 1000;
BA_ "GenSigCycleTime" SG_ 1288 MIStatus 100;
BA_ "GenSigCycleTimeActive" SG_ 1288 MIStatus 100;
BA_ "GenSigStartValue" SG_ 1288 MIStatus 3;
BA_ "GenSigCycleTime" SG_ 1288 SCROperatorInducementSeverity_IS 100;
BA_ "GenSigCycleTimeActive" SG_ 1288 SCROperatorInducementSeverity_IS 100;
BA_ "GenSigStartValue" SG_ 1288 SCROperatorInducementSeverity_IS 7;
BA_ "SystemSignalLongSymbol" SG_ 1288 SCROperatorInducementSeverity_IS "SCROperatorInducementSeverity_ISig_2";
BA_ "GenSigCycleTime" SG_ 1288 TimeLeftToTorqueReduction_OBD_IS 100;
BA_ "GenSigCycleTimeActive" SG_ 1288 TimeLeftToTorqueReduction_OBD_IS 100;
BA_ "GenSigStartValue" SG_ 1288 TimeLeftToTorqueReduction_OBD_IS 511;
BA_ "SystemSignalLongSymbol" SG_ 1288 TimeLeftToTorqueReduction_OBD_IS "TimeLeftToTorqueReduction_OBD_ISig_2";
BA_ "GenSigCycleTime" SG_ 1288 EMS_Available_Log 100;
BA_ "GenSigCycleTimeActive" SG_ 1288 EMS_Available_Log 100;
BA_ "GenSigStartValue" SG_ 1288 EMS_Available_Log 255;
BA_ "GenSigCycleTime" SG_ 1288 FuelOperatorDeratingSeverity_ISi 100;
BA_ "GenSigCycleTimeActive" SG_ 1288 FuelOperatorDeratingSeverity_ISi 100;
BA_ "GenSigStartValue" SG_ 1288 FuelOperatorDeratingSeverity_ISi 7;
BA_ "GenSigMaxLatency" SG_ 1288 FuelOperatorDeratingSeverity_ISi 1000;
BA_ "SystemSignalLongSymbol" SG_ 1288 FuelOperatorDeratingSeverity_ISi "FuelOperatorDeratingSeverity_ISig_2";
BA_ "GenSigCycleTime" SG_ 1288 MIDistinctWarning_ISig_2 100;
BA_ "GenSigCycleTimeActive" SG_ 1288 MIDistinctWarning_ISig_2 100;
BA_ "GenSigStartValue" SG_ 1288 MIDistinctWarning_ISig_2 3;
BA_ "GenSigCycleTime" SG_ 1288 SCROperatorInducementReason_ISig 100;
BA_ "GenSigCycleTimeActive" SG_ 1288 SCROperatorInducementReason_ISig 100;
BA_ "GenSigStartValue" SG_ 1288 SCROperatorInducementReason_ISig 7;
BA_ "SystemSignalLongSymbol" SG_ 1288 SCROperatorInducementReason_ISig "SCROperatorInducementReason_ISig_2";
BA_ "GenSigCycleTime" SG_ 1288 StarterMotorActivations 100;
BA_ "GenSigCycleTimeActive" SG_ 1288 StarterMotorActivations 100;
BA_ "GenSigStartValue" SG_ 1288 StarterMotorActivations 4294967295;
BA_ "GenSigCycleTime" SG_ 1288 EcoCruisePwtMaxUnSpeedLev1_ISig_ 100;
BA_ "GenSigCycleTimeActive" SG_ 1288 EcoCruisePwtMaxUnSpeedLev1_ISig_ 100;
BA_ "GenSigStartValue" SG_ 1288 EcoCruisePwtMaxUnSpeedLev1_ISig_ 31;
BA_ "SystemSignalLongSymbol" SG_ 1288 EcoCruisePwtMaxUnSpeedLev1_ISig_ "EcoCruisePwtMaxUnSpeedLev1_ISig_2";
BA_ "GenSigCycleTime" SG_ 1288 MIStatusExtEMS_ISig_2 100;
BA_ "GenSigCycleTimeActive" SG_ 1288 MIStatusExtEMS_ISig_2 100;
BA_ "GenSigStartValue" SG_ 1288 MIStatusExtEMS_ISig_2 3;
BA_ "GenSigCycleTime" SG_ 1288 EcoCruisePwtMaxUnSpeedLev3_ISig_ 100;
BA_ "GenSigCycleTimeActive" SG_ 1288 EcoCruisePwtMaxUnSpeedLev3_ISig_ 100;
BA_ "GenSigStartValue" SG_ 1288 EcoCruisePwtMaxUnSpeedLev3_ISig_ 31;
BA_ "SystemSignalLongSymbol" SG_ 1288 EcoCruisePwtMaxUnSpeedLev3_ISig_ "EcoCruisePwtMaxUnSpeedLev3_ISig_2";
BA_ "GenSigCycleTime" SG_ 1288 EcoCruisePwtMaxOvSpeedLev3_ISig_ 100;
BA_ "GenSigCycleTimeActive" SG_ 1288 EcoCruisePwtMaxOvSpeedLev3_ISig_ 100;
BA_ "GenSigStartValue" SG_ 1288 EcoCruisePwtMaxOvSpeedLev3_ISig_ 31;
BA_ "SystemSignalLongSymbol" SG_ 1288 EcoCruisePwtMaxOvSpeedLev3_ISig_ "EcoCruisePwtMaxOvSpeedLev3_ISig_2";
BA_ "GenSigCycleTime" SG_ 1288 DistLeftToSevereInducement_OBD_I 100;
BA_ "GenSigCycleTimeActive" SG_ 1288 DistLeftToSevereInducement_OBD_I 100;
BA_ "GenSigStartValue" SG_ 1288 DistLeftToSevereInducement_OBD_I 255;
BA_ "SystemSignalLongSymbol" SG_ 1288 DistLeftToSevereInducement_OBD_I "DistLeftToSevereInducement_OBD_ISig_2";
BA_ "GenSigCycleTime" SG_ 1288 FuelOperatorDeratingReason_ISig_ 100;
BA_ "GenSigCycleTimeActive" SG_ 1288 FuelOperatorDeratingReason_ISig_ 100;
BA_ "GenSigStartValue" SG_ 1288 FuelOperatorDeratingReason_ISig_ 3;
BA_ "GenSigMaxLatency" SG_ 1288 FuelOperatorDeratingReason_ISig_ 1000;
BA_ "SystemSignalLongSymbol" SG_ 1288 FuelOperatorDeratingReason_ISig_ "FuelOperatorDeratingReason_ISig_2";
BA_ "GenSigCycleTime" SG_ 1282 LNGOperatorInducementReason_ISig 100;
BA_ "GenSigCycleTimeActive" SG_ 1282 LNGOperatorInducementReason_ISig 100;
BA_ "GenSigStartValue" SG_ 1282 LNGOperatorInducementReason_ISig 7;
BA_ "SystemSignalLongSymbol" SG_ 1282 LNGOperatorInducementReason_ISig "LNGOperatorInducementReason_ISig_2";
BA_ "GenSigCycleTime" SG_ 1282 EngineFuelMode 100;
BA_ "GenSigCycleTimeActive" SG_ 1282 EngineFuelMode 100;
BA_ "GenSigStartValue" SG_ 1282 EngineFuelMode 3;
BA_ "GenSigCycleTime" SG_ 1282 EngineTotalLngConsumed_ISig_2 100;
BA_ "GenSigCycleTimeActive" SG_ 1282 EngineTotalLngConsumed_ISig_2 100;
BA_ "GenSigStartValue" SG_ 1282 EngineTotalLngConsumed_ISig_2 4294967295;
BA_ "GenSigCycleTime" SG_ 1282 ExhManif_EMAIAirTankPres 100;
BA_ "GenSigCycleTimeActive" SG_ 1282 ExhManif_EMAIAirTankPres 100;
BA_ "GenSigStartValue" SG_ 1282 ExhManif_EMAIAirTankPres 255;
BA_ "GenSigSendType" SG_ 958 KeyID_EngineStartAuth 1;
BA_ "GenSigCycleTime" SG_ 958 KeyID_EngineStartAuth 100;
BA_ "GenSigCycleTimeActive" SG_ 958 KeyID_EngineStartAuth 100;
BA_ "GenSigSendType" SG_ 1341 ECU4VIN_stat 1;
BA_ "GenSigCycleTime" SG_ 1341 ECU4VIN_stat 100;
BA_ "GenSigCycleTimeActive" SG_ 1341 ECU4VIN_stat 100;
BA_ "GenSigCycleTime" SG_ 1392 EngineRunningTime_ISig_2 100;
BA_ "GenSigCycleTimeActive" SG_ 1392 EngineRunningTime_ISig_2 100;
BA_ "GenSigStartValue" SG_ 1392 EngineRunningTime_ISig_2 4294967295;
BA_ "GenSigCycleTime" SG_ 1392 TotPTOFuelHighAccuracy 100;
BA_ "GenSigCycleTimeActive" SG_ 1392 TotPTOFuelHighAccuracy 100;
BA_ "GenSigStartValue" SG_ 1392 TotPTOFuelHighAccuracy 4294967295;
BA_ "GenSigCycleTime" SG_ 1391 OilPrediction_RemainDist 100;
BA_ "GenSigCycleTimeActive" SG_ 1391 OilPrediction_RemainDist 100;
BA_ "GenSigStartValue" SG_ 1391 OilPrediction_RemainDist 65535;
BA_ "GenSigCycleTime" SG_ 1391 TimeLeftToVehSpdReduction_OBD_IS 100;
BA_ "GenSigCycleTimeActive" SG_ 1391 TimeLeftToVehSpdReduction_OBD_IS 100;
BA_ "GenSigStartValue" SG_ 1391 TimeLeftToVehSpdReduction_OBD_IS 511;
BA_ "SystemSignalLongSymbol" SG_ 1391 TimeLeftToVehSpdReduction_OBD_IS "TimeLeftToVehSpdReduction_OBD_ISig_2";
BA_ "GenSigCycleTime" SG_ 1391 OilPrediction_RemainTime 100;
BA_ "GenSigCycleTimeActive" SG_ 1391 OilPrediction_RemainTime 100;
BA_ "GenSigStartValue" SG_ 1391 OilPrediction_RemainTime 65535;
BA_ "GenSigCycleTime" SG_ 1391 TimeToCorrectOilLevel 100;
BA_ "GenSigCycleTimeActive" SG_ 1391 TimeToCorrectOilLevel 100;
BA_ "GenSigStartValue" SG_ 1391 TimeToCorrectOilLevel 255;
BA_ "GenSigCycleTime" SG_ 1391 OilPrediction_Status 100;
BA_ "GenSigCycleTimeActive" SG_ 1391 OilPrediction_Status 100;
BA_ "GenSigStartValue" SG_ 1391 OilPrediction_Status 7;
BA_ "GenSigCycleTime" SG_ 1391 OilPrediction_Quality 100;
BA_ "GenSigCycleTimeActive" SG_ 1391 OilPrediction_Quality 100;
BA_ "GenSigStartValue" SG_ 1391 OilPrediction_Quality 7;
BA_ "GenSigCycleTime" SG_ 1279 AirFilterPressureDrop 100;
BA_ "GenSigCycleTimeActive" SG_ 1279 AirFilterPressureDrop 100;
BA_ "GenSigStartValue" SG_ 1279 AirFilterPressureDrop 7;
BA_ "GenSigCycleTime" SG_ 1279 EngineTotalFuelConsumed_ISig_2 100;
BA_ "GenSigCycleTimeActive" SG_ 1279 EngineTotalFuelConsumed_ISig_2 100;
BA_ "GenSigStartValue" SG_ 1279 EngineTotalFuelConsumed_ISig_2 4294967295;
BA_ "GenSigCycleTime" SG_ 1279 FuelFilterClogged_ISig_2 100;
BA_ "GenSigCycleTimeActive" SG_ 1279 FuelFilterClogged_ISig_2 100;
BA_ "GenSigStartValue" SG_ 1279 FuelFilterClogged_ISig_2 7;
BA_ "GenSigCycleTime" SG_ 1279 CoolantPumpEngagementStatus_ISig 100;
BA_ "GenSigCycleTimeActive" SG_ 1279 CoolantPumpEngagementStatus_ISig 100;
BA_ "GenSigStartValue" SG_ 1279 CoolantPumpEngagementStatus_ISig 255;
BA_ "SystemSignalLongSymbol" SG_ 1279 CoolantPumpEngagementStatus_ISig "CoolantPumpEngagementStatus_ISig_2";
BA_ "GenSigCycleTime" SG_ 1279 BarometricPressure_ISig_2 100;
BA_ "GenSigCycleTimeActive" SG_ 1279 BarometricPressure_ISig_2 100;
BA_ "GenSigStartValue" SG_ 1279 BarometricPressure_ISig_2 255;
BA_ "GenSigCycleTime" SG_ 1279 StarterMotorRecoveryTime_ISig_2 100;
BA_ "GenSigCycleTimeActive" SG_ 1279 StarterMotorRecoveryTime_ISig_2 100;
BA_ "GenSigStartValue" SG_ 1279 StarterMotorRecoveryTime_ISig_2 65535;
BA_ "GenSigCycleTime" SG_ 1279 CoolantTempGaugeAdjustment_ISig_ 100;
BA_ "GenSigCycleTimeActive" SG_ 1279 CoolantTempGaugeAdjustment_ISig_ 100;
BA_ "GenSigStartValue" SG_ 1279 CoolantTempGaugeAdjustment_ISig_ 255;
BA_ "SystemSignalLongSymbol" SG_ 1279 CoolantTempGaugeAdjustment_ISig_ "CoolantTempGaugeAdjustment_ISig_2";
BA_ "GenSigCycleTime" SG_ 1279 DrainPrimingStatus_ISig_2 100;
BA_ "GenSigCycleTimeActive" SG_ 1279 DrainPrimingStatus_ISig_2 100;
BA_ "GenSigStartValue" SG_ 1279 DrainPrimingStatus_ISig_2 7;
BA_ "GenSigCycleTime" SG_ 1279 CoolantLevelLow 100;
BA_ "GenSigCycleTimeActive" SG_ 1279 CoolantLevelLow 100;
BA_ "GenSigStartValue" SG_ 1279 CoolantLevelLow 7;
BA_ "GenSigCycleTime" SG_ 1279 AverageFuelEconomy_ISig_2 100;
BA_ "GenSigCycleTimeActive" SG_ 1279 AverageFuelEconomy_ISig_2 100;
BA_ "GenSigStartValue" SG_ 1279 AverageFuelEconomy_ISig_2 65535;
BA_ "GenSigCycleTime" SG_ 1279 EngineProtDerateStat 100;
BA_ "GenSigCycleTimeActive" SG_ 1279 EngineProtDerateStat 100;
BA_ "GenSigStartValue" SG_ 1279 EngineProtDerateStat 3;
BA_ "GenSigCycleTime" SG_ 1279 EngineAirInletTemperature 100;
BA_ "GenSigCycleTimeActive" SG_ 1279 EngineAirInletTemperature 100;
BA_ "GenSigStartValue" SG_ 1279 EngineAirInletTemperature 255;
BA_ "GenSigCycleTime" SG_ 1279 FuelEcoEngStatus 100;
BA_ "GenSigCycleTimeActive" SG_ 1279 FuelEcoEngStatus 100;
BA_ "GenSigStartValue" SG_ 1279 FuelEcoEngStatus 3;
BA_ "GenSigCycleTime" SG_ 1279 OilLevelLow_ISig_2 100;
BA_ "GenSigCycleTimeActive" SG_ 1279 OilLevelLow_ISig_2 100;
BA_ "GenSigStartValue" SG_ 1279 OilLevelLow_ISig_2 7;
BA_ "GenSigCycleTime" SG_ 1279 AutoWheelBrakesStatus_ISig_2 100;
BA_ "GenSigCycleTimeActive" SG_ 1279 AutoWheelBrakesStatus_ISig_2 100;
BA_ "GenSigStartValue" SG_ 1279 AutoWheelBrakesStatus_ISig_2 7;
BA_ "GenSigCycleTime" SG_ 1279 EngineFanOverspeed_ISig_2 100;
BA_ "GenSigCycleTimeActive" SG_ 1279 EngineFanOverspeed_ISig_2 100;
BA_ "GenSigStartValue" SG_ 1279 EngineFanOverspeed_ISig_2 3;
BA_ "GenSigCycleTime" SG_ 1279 InletAirHeaterStatus1_ISig_2 100;
BA_ "GenSigCycleTimeActive" SG_ 1279 InletAirHeaterStatus1_ISig_2 100;
BA_ "GenSigStartValue" SG_ 1279 InletAirHeaterStatus1_ISig_2 3;
BA_ "GenSigCycleTime" SG_ 1279 TopGearMode 100;
BA_ "GenSigCycleTimeActive" SG_ 1279 TopGearMode 100;
BA_ "GenSigStartValue" SG_ 1279 TopGearMode 3;
BA_ "GenSigCycleTime" SG_ 1279 CoolantTempHigh_ISig_2 100;
BA_ "GenSigCycleTimeActive" SG_ 1279 CoolantTempHigh_ISig_2 100;
BA_ "GenSigStartValue" SG_ 1279 CoolantTempHigh_ISig_2 7;
BA_ "GenSigCycleTime" SG_ 1279 AppliedVehicleSpeedLimit 100;
BA_ "GenSigCycleTimeActive" SG_ 1279 AppliedVehicleSpeedLimit 100;
BA_ "GenSigStartValue" SG_ 1279 AppliedVehicleSpeedLimit 65535;
BA_ "GenSigCycleTime" SG_ 1279 EnergyForNextCrank_ISig_2 100;
BA_ "GenSigCycleTimeActive" SG_ 1279 EnergyForNextCrank_ISig_2 100;
BA_ "GenSigStartValue" SG_ 1279 EnergyForNextCrank_ISig_2 15;
BA_ "GenSigMaxLatency" SG_ 1279 EnergyForNextCrank_ISig_2 250;
BA_ "GenSigCycleTime" SG_ 1279 OilPressureLow_ISig_2 100;
BA_ "GenSigCycleTimeActive" SG_ 1279 OilPressureLow_ISig_2 100;
BA_ "GenSigStartValue" SG_ 1279 OilPressureLow_ISig_2 7;
BA_ "GenSigCycleTime" SG_ 1279 DPF_ParkedRegenStatus_ISig_2 100;
BA_ "GenSigCycleTimeActive" SG_ 1279 DPF_ParkedRegenStatus_ISig_2 100;
BA_ "GenSigStartValue" SG_ 1279 DPF_ParkedRegenStatus_ISig_2 7;
BA_ "GenSigCycleTime" SG_ 1279 StarterMotorReset_ack 100;
BA_ "GenSigCycleTimeActive" SG_ 1279 StarterMotorReset_ack 100;
BA_ "GenSigStartValue" SG_ 1279 StarterMotorReset_ack 3;
BA_ "GenSigCycleTime" SG_ 1279 EngineCoolingFanSpeed_ISig_2 100;
BA_ "GenSigCycleTimeActive" SG_ 1279 EngineCoolingFanSpeed_ISig_2 100;
BA_ "GenSigStartValue" SG_ 1279 EngineCoolingFanSpeed_ISig_2 65535;
BA_ "GenSigCycleTime" SG_ 1279 EngineGasRate 100;
BA_ "GenSigCycleTimeActive" SG_ 1279 EngineGasRate 100;
BA_ "GenSigStartValue" SG_ 1279 EngineGasRate 65535;
BA_ "GenSigCycleTime" SG_ 1279 DMSDriverFollow 100;
BA_ "GenSigCycleTimeActive" SG_ 1279 DMSDriverFollow 100;
BA_ "GenSigStartValue" SG_ 1279 DMSDriverFollow 3;
BA_ "GenSigCycleTime" SG_ 719 XARActiveControlMode 100;
BA_ "GenSigCycleTimeActive" SG_ 719 XARActiveControlMode 100;
BA_ "GenSigStartValue" SG_ 719 XARActiveControlMode 7;
BA_ "GenSigCycleTime" SG_ 719 WarmUpCycle 100;
BA_ "GenSigCycleTimeActive" SG_ 719 WarmUpCycle 100;
BA_ "GenSigStartValue" SG_ 719 WarmUpCycle 3;
BA_ "GenSigCycleTime" SG_ 719 DeterminedGear 100;
BA_ "GenSigCycleTimeActive" SG_ 719 DeterminedGear 100;
BA_ "GenSigStartValue" SG_ 719 DeterminedGear 255;
BA_ "GenSigCycleTime" SG_ 719 DPF_LimitedSpeedDuetoInhibit_ISi 100;
BA_ "GenSigCycleTimeActive" SG_ 719 DPF_LimitedSpeedDuetoInhibit_ISi 100;
BA_ "GenSigStartValue" SG_ 719 DPF_LimitedSpeedDuetoInhibit_ISi 7;
BA_ "SystemSignalLongSymbol" SG_ 719 DPF_LimitedSpeedDuetoInhibit_ISi "DPF_LimitedSpeedDuetoInhibit_ISig_2";
BA_ "GenSigCycleTime" SG_ 719 AirFilter_Pressure 100;
BA_ "GenSigCycleTimeActive" SG_ 719 AirFilter_Pressure 100;
BA_ "GenSigStartValue" SG_ 719 AirFilter_Pressure 2047;
BA_ "GenSigCycleTime" SG_ 719 CCControllerMode 100;
BA_ "GenSigCycleTimeActive" SG_ 719 CCControllerMode 100;
BA_ "GenSigStartValue" SG_ 719 CCControllerMode 7;
BA_ "GenSigCycleTime" SG_ 719 ExhManif_AirInjActive 100;
BA_ "GenSigCycleTimeActive" SG_ 719 ExhManif_AirInjActive 100;
BA_ "GenSigStartValue" SG_ 719 ExhManif_AirInjActive 3;
BA_ "GenSigCycleTime" SG_ 719 AirFilter_AirMassFlowValidated 100;
BA_ "GenSigCycleTimeActive" SG_ 719 AirFilter_AirMassFlowValidated 100;
BA_ "GenSigStartValue" SG_ 719 AirFilter_AirMassFlowValidated 255;
BA_ "GenSigCycleTime" SG_ 719 CCBControllerMode 100;
BA_ "GenSigCycleTimeActive" SG_ 719 CCBControllerMode 100;
BA_ "GenSigStartValue" SG_ 719 CCBControllerMode 7;
BA_ "GenSigCycleTime" SG_ 719 CCSetSpeedApplied 100;
BA_ "GenSigCycleTimeActive" SG_ 719 CCSetSpeedApplied 100;
BA_ "GenSigStartValue" SG_ 719 CCSetSpeedApplied 255;
BA_ "GenSigCycleTime" SG_ 719 EngineSystemPowerDownAck 100;
BA_ "GenSigCycleTimeActive" SG_ 719 EngineSystemPowerDownAck 100;
BA_ "GenSigStartValue" SG_ 719 EngineSystemPowerDownAck 3;
BA_ "GenSigCycleTime" SG_ 719 RegenInhibDueHeight_ISig_2 100;
BA_ "GenSigCycleTimeActive" SG_ 719 RegenInhibDueHeight_ISig_2 100;
BA_ "GenSigStartValue" SG_ 719 RegenInhibDueHeight_ISig_2 3;
BA_ "GenSigCycleTime" SG_ 719 XARSystemState 100;
BA_ "GenSigCycleTimeActive" SG_ 719 XARSystemState 100;
BA_ "GenSigStartValue" SG_ 719 XARSystemState 3;
BA_ "GenSigCycleTime" SG_ 719 EngineStartAuth_rqst 100;
BA_ "GenSigCycleTimeActive" SG_ 719 EngineStartAuth_rqst 100;
BA_ "GenSigStartValue" SG_ 719 EngineStartAuth_rqst 7;
BA_ "GenSigCycleTime" SG_ 719 EngCompartmentStopSwitchStat 100;
BA_ "GenSigCycleTimeActive" SG_ 719 EngCompartmentStopSwitchStat 100;
BA_ "GenSigStartValue" SG_ 719 EngCompartmentStopSwitchStat 3;
BA_ "GenSigCycleTime" SG_ 719 PwtEngineTmpryStopAllowed 100;
BA_ "GenSigCycleTimeActive" SG_ 719 PwtEngineTmpryStopAllowed 100;
BA_ "GenSigStartValue" SG_ 719 PwtEngineTmpryStopAllowed 3;
BA_ "GenSigCycleTime" SG_ 719 IntakeAirTemperatureAlert 100;
BA_ "GenSigCycleTimeActive" SG_ 719 IntakeAirTemperatureAlert 100;
BA_ "GenSigStartValue" SG_ 719 IntakeAirTemperatureAlert 3;
BA_ "GenSigCycleTime" SG_ 719 EngineOilTempHigh_ISig_2 100;
BA_ "GenSigCycleTimeActive" SG_ 719 EngineOilTempHigh_ISig_2 100;
BA_ "GenSigStartValue" SG_ 719 EngineOilTempHigh_ISig_2 7;
BA_ "GenSigCycleTime" SG_ 719 XRSLControllerMode_ISig_2 100;
BA_ "GenSigCycleTimeActive" SG_ 719 XRSLControllerMode_ISig_2 100;
BA_ "GenSigStartValue" SG_ 719 XRSLControllerMode_ISig_2 3;
BA_ "GenSigCycleTime" SG_ 719 InhibitIdleShutdownStatus 100;
BA_ "GenSigCycleTimeActive" SG_ 719 InhibitIdleShutdownStatus 100;
BA_ "GenSigStartValue" SG_ 719 InhibitIdleShutdownStatus 7;
BA_ "GenSigCycleTime" SG_ 719 CrankcasePressureHigh 100;
BA_ "GenSigCycleTimeActive" SG_ 719 CrankcasePressureHigh 100;
BA_ "GenSigStartValue" SG_ 719 CrankcasePressureHigh 3;
BA_ "GenSigCycleTime" SG_ 719 CCBSetSpeedApplied 100;
BA_ "GenSigCycleTimeActive" SG_ 719 CCBSetSpeedApplied 100;
BA_ "GenSigStartValue" SG_ 719 CCBSetSpeedApplied 255;
BA_ "GenSigCycleTime" SG_ 719 EngineAirInletPressure 100;
BA_ "GenSigCycleTimeActive" SG_ 719 EngineAirInletPressure 100;
BA_ "GenSigStartValue" SG_ 719 EngineAirInletPressure 255;
BA_ "GenSigSendType" SG_ 2671964696 DiagUUDTRespSig_F2_18_ISig_2 7;
BA_ "GenSigSendType" SG_ 2671964688 DiagUUDTRespSig_F2_10_ISig_2 7;
BA_ "GenSigSendType" SG_ 2671834136 InternalTesterDiagSig_F4_18 7;
BA_ "GenSigSendType" SG_ 2671834128 InternalTesterDiagSig_F4_10 7;
BA_ "GenSigSendType" SG_ 2671778036 InternalTesterDiagSig_18_F4 7;
BA_ "GenSigSendType" SG_ 2671775988 InternalTesterDiagSig_10_F4 7;
BA_ "GenSigSendType" SG_ 1519 DiagFaultStat_TECU_DtcIdB 3;
BA_ "GenSigSendType" SG_ 1519 DiagFaultStat_TECU_EcuAdr 3;
BA_ "GenSigStartValue" SG_ 1519 DiagFaultStat_TECU_EcuAdr 255;
BA_ "GenSigSendType" SG_ 1519 DiagFaultStat_TECU_DtcIdA 3;
BA_ "GenSigSendType" SG_ 1519 DiagFaultStat_TECU_FailTB 3;
BA_ "GenSigSendType" SG_ 1519 DiagFaultStat_TECU_sg_UB 7;
BA_ "Platform_VMCU1_Sig" SG_ 1519 DiagFaultStat_TECU_sg_UB 1;
BA_ "GenSigSendType" SG_ 1519 DiagFaultStat_TECU_FailTA 3;
BA_ "GenSigSendType" SG_ 1511 DiagFaultStat_EMS_DtcIdB 3;
BA_ "GenSigSendType" SG_ 1511 DiagFaultStat_EMS_EcuAdr 3;
BA_ "GenSigStartValue" SG_ 1511 DiagFaultStat_EMS_EcuAdr 255;
BA_ "GenSigSendType" SG_ 1511 DiagFaultStat_EMS_DtcIdA 3;
BA_ "GenSigSendType" SG_ 1511 DiagFaultStat_EMS_FailTA 3;
BA_ "GenSigSendType" SG_ 1511 DiagFaultStat_EMS_sg_UB 7;
BA_ "Platform_VMCU1_Sig" SG_ 1511 DiagFaultStat_EMS_sg_UB 1;
BA_ "GenSigSendType" SG_ 1511 DiagFaultStat_EMS_FailTB 3;
BA_ "GenSigSendType" SG_ 1698 AnmSig_VCM_CAN02 1;
BA_ "GenSigCycleTime" SG_ 1698 AnmSig_VCM_CAN02 100;
BA_ "GenSigCycleTimeActive" SG_ 1698 AnmSig_VCM_CAN02 100;
BA_ "MmAnSignal" SG_ 1698 AnmSig_VCM_CAN02 1;
BA_ "GenSigSendType" SG_ 1696 AnmSig_TCM_CAN02 1;
BA_ "GenSigCycleTime" SG_ 1696 AnmSig_TCM_CAN02 100;
BA_ "GenSigCycleTimeActive" SG_ 1696 AnmSig_TCM_CAN02 100;
BA_ "MmAnSignal" SG_ 1696 AnmSig_TCM_CAN02 1;
BA_ "GenSigSendType" SG_ 1697 AnmSig_ECM_CAN02 1;
BA_ "GenSigCycleTime" SG_ 1697 AnmSig_ECM_CAN02 100;
BA_ "GenSigCycleTimeActive" SG_ 1697 AnmSig_ECM_CAN02 100;
BA_ "MmAnSignal" SG_ 1697 AnmSig_ECM_CAN02 1;
BA_REL_ "GenSigFirstTimeoutTime" BU_SG_REL_ ECM SG_ 1414 GPSData_sg_UB 24000;
BA_REL_ "GenSigTimeoutTime" BU_SG_REL_ ECM SG_ 1414 GPSData_sg_UB 6000;
BA_REL_ "GenSigFirstTimeoutTime" BU_SG_REL_ TCM SG_ 1414 GPSData_sg_UB 12000;
BA_REL_ "GenSigTimeoutTime" BU_SG_REL_ TCM SG_ 1414 GPSData_sg_UB 3000;
BA_REL_ "GenSigFirstTimeoutTime" BU_SG_REL_ ECM SG_ 1414 GPSData_Altitude 24000;
BA_REL_ "GenSigTimeoutTime" BU_SG_REL_ ECM SG_ 1414 GPSData_Altitude 6000;
BA_REL_ "GenSigFirstTimeoutTime" BU_SG_REL_ TCM SG_ 1414 GPSData_Altitude 12000;
BA_REL_ "GenSigTimeoutTime" BU_SG_REL_ TCM SG_ 1414 GPSData_Altitude 3000;
BA_REL_ "GenSigFirstTimeoutTime" BU_SG_REL_ TCM SG_ 1414 GPSData_Time 12000;
BA_REL_ "GenSigTimeoutTime" BU_SG_REL_ TCM SG_ 1414 GPSData_Time 3000;
BA_REL_ "GenSigFirstTimeoutTime" BU_SG_REL_ ECM SG_ 1414 GPSData_Time 24000;
BA_REL_ "GenSigTimeoutTime" BU_SG_REL_ ECM SG_ 1414 GPSData_Time 6000;
BA_REL_ "GenSigFirstTimeoutTime" BU_SG_REL_ TCM SG_ 1414 GPSData_AntennaStat 12000;
BA_REL_ "GenSigTimeoutTime" BU_SG_REL_ TCM SG_ 1414 GPSData_AntennaStat 3000;
BA_REL_ "GenSigFirstTimeoutTime" BU_SG_REL_ ECM SG_ 1414 GPSData_AntennaStat 24000;
BA_REL_ "GenSigTimeoutTime" BU_SG_REL_ ECM SG_ 1414 GPSData_AntennaStat 6000;
BA_REL_ "GenSigFirstTimeoutTime" BU_SG_REL_ ECM SG_ 1414 GPSData_HDOP 24000;
BA_REL_ "GenSigTimeoutTime" BU_SG_REL_ ECM SG_ 1414 GPSData_HDOP 6000;
BA_REL_ "GenSigFirstTimeoutTime" BU_SG_REL_ TCM SG_ 1414 GPSData_HDOP 12000;
BA_REL_ "GenSigTimeoutTime" BU_SG_REL_ TCM SG_ 1414 GPSData_HDOP 3000;
BA_REL_ "GenSigFirstTimeoutTime" BU_SG_REL_ ECM SG_ 1414 GPSData_Longitude 24000;
BA_REL_ "GenSigTimeoutTime" BU_SG_REL_ ECM SG_ 1414 GPSData_Longitude 6000;
BA_REL_ "GenSigFirstTimeoutTime" BU_SG_REL_ TCM SG_ 1414 GPSData_Longitude 12000;
BA_REL_ "GenSigTimeoutTime" BU_SG_REL_ TCM SG_ 1414 GPSData_Longitude 3000;
BA_REL_ "GenSigFirstTimeoutTime" BU_SG_REL_ ECM SG_ 1414 GPSData_Latitude 24000;
BA_REL_ "GenSigTimeoutTime" BU_SG_REL_ ECM SG_ 1414 GPSData_Latitude 6000;
BA_REL_ "GenSigFirstTimeoutTime" BU_SG_REL_ TCM SG_ 1414 GPSData_Latitude 12000;
BA_REL_ "GenSigTimeoutTime" BU_SG_REL_ TCM SG_ 1414 GPSData_Latitude 3000;
BA_REL_ "GenSigFirstTimeoutTime" BU_SG_REL_ TCM SG_ 1414 GPSData_Direction 12000;
BA_REL_ "GenSigTimeoutTime" BU_SG_REL_ TCM SG_ 1414 GPSData_Direction 3000;
BA_REL_ "GenSigFirstTimeoutTime" BU_SG_REL_ ECM SG_ 1414 GPSData_Direction 24000;
BA_REL_ "GenSigTimeoutTime" BU_SG_REL_ ECM SG_ 1414 GPSData_Direction 6000;
BA_REL_ "GenSigFirstTimeoutTime" BU_SG_REL_ TCM SG_ 1414 GPSData_VehSpeed 12000;
BA_REL_ "GenSigTimeoutTime" BU_SG_REL_ TCM SG_ 1414 GPSData_VehSpeed 3000;
BA_REL_ "GenSigFirstTimeoutTime" BU_SG_REL_ ECM SG_ 1414 GPSData_VehSpeed 24000;
BA_REL_ "GenSigTimeoutTime" BU_SG_REL_ ECM SG_ 1414 GPSData_VehSpeed 6000;
BA_REL_ "GenSigFirstTimeoutTime" BU_SG_REL_ VCM SG_ 1251 HillDataPkgTECU 12000;
BA_REL_ "GenSigTimeoutTime" BU_SG_REL_ VCM SG_ 1251 HillDataPkgTECU 3000;
BA_REL_ "GenSigFirstTimeoutTime" BU_SG_REL_ VCM SG_ 1463 TECU_Available_Log 65000;
BA_REL_ "GenSigTimeoutTime" BU_SG_REL_ VCM SG_ 1463 TECU_Available_Log 30000;
BA_REL_ "GenSigFirstTimeoutTime" BU_SG_REL_ VCM SG_ 1249 OilLevelDrvInstr_StopVehicle_ISi 12000;
BA_REL_ "GenSigTimeoutTime" BU_SG_REL_ VCM SG_ 1249 OilLevelDrvInstr_StopVehicle_ISi 3000;
BA_REL_ "GenSigFirstTimeoutTime" BU_SG_REL_ VCM SG_ 1249 ClutchCalibration_stat_ISig_2 12000;
BA_REL_ "GenSigTimeoutTime" BU_SG_REL_ VCM SG_ 1249 ClutchCalibration_stat_ISig_2 3000;
BA_REL_ "GenSigFirstTimeoutTime" BU_SG_REL_ VCM SG_ 1249 HillDataCtrlTECU_AckCnt 12000;
BA_REL_ "GenSigTimeoutTime" BU_SG_REL_ VCM SG_ 1249 HillDataCtrlTECU_AckCnt 3000;
BA_REL_ "GenSigFirstTimeoutTime" BU_SG_REL_ VCM SG_ 1249 OilLevelDrvInstr_OilTempTxt_ISig 12000;
BA_REL_ "GenSigTimeoutTime" BU_SG_REL_ VCM SG_ 1249 OilLevelDrvInstr_OilTempTxt_ISig 3000;
BA_REL_ "GenSigFirstTimeoutTime" BU_SG_REL_ VCM SG_ 1249 OilLevelDrvInstr_Wait60SecTxt_IS 12000;
BA_REL_ "GenSigTimeoutTime" BU_SG_REL_ VCM SG_ 1249 OilLevelDrvInstr_Wait60SecTxt_IS 3000;
BA_REL_ "GenSigFirstTimeoutTime" BU_SG_REL_ VCM SG_ 1249 EcoRollEnabledStatus_ISig_2 12000;
BA_REL_ "GenSigTimeoutTime" BU_SG_REL_ VCM SG_ 1249 EcoRollEnabledStatus_ISig_2 3000;
BA_REL_ "GenSigFirstTimeoutTime" BU_SG_REL_ VCM SG_ 1249 ClutchAbuseStatus_ISig_2 12000;
BA_REL_ "GenSigTimeoutTime" BU_SG_REL_ VCM SG_ 1249 ClutchAbuseStatus_ISig_2 3000;
BA_REL_ "GenSigFirstTimeoutTime" BU_SG_REL_ VCM SG_ 1249 SchwungStatus 12000;
BA_REL_ "GenSigTimeoutTime" BU_SG_REL_ VCM SG_ 1249 SchwungStatus 3000;
BA_REL_ "GenSigFirstTimeoutTime" BU_SG_REL_ VCM SG_ 1249 OilLevelDrvInstr_ChangeGearTxt_I 12000;
BA_REL_ "GenSigTimeoutTime" BU_SG_REL_ VCM SG_ 1249 OilLevelDrvInstr_ChangeGearTxt_I 3000;
BA_REL_ "GenSigFirstTimeoutTime" BU_SG_REL_ VCM SG_ 1249 OilLevelDrvInstr_IncorrEngSpe_IS 12000;
BA_REL_ "GenSigTimeoutTime" BU_SG_REL_ VCM SG_ 1249 OilLevelDrvInstr_IncorrEngSpe_IS 3000;
BA_REL_ "GenSigFirstTimeoutTime" BU_SG_REL_ VCM SG_ 1249 CACCSuitability 12000;
BA_REL_ "GenSigTimeoutTime" BU_SG_REL_ VCM SG_ 1249 CACCSuitability 3000;
BA_REL_ "GenSigFirstTimeoutTime" BU_SG_REL_ VCM SG_ 1249 HillDataCtrlTECU_State 12000;
BA_REL_ "GenSigTimeoutTime" BU_SG_REL_ VCM SG_ 1249 HillDataCtrlTECU_State 3000;
BA_REL_ "GenSigFirstTimeoutTime" BU_SG_REL_ VCM SG_ 1249 TransmissionSplitboxPTOMode_ISig 12000;
BA_REL_ "GenSigTimeoutTime" BU_SG_REL_ VCM SG_ 1249 TransmissionSplitboxPTOMode_ISig 3000;
BA_REL_ "GenSigFirstTimeoutTime" BU_SG_REL_ VCM SG_ 1249 OilLevelDrvInstr_NotHorizonTxt_I 12000;
BA_REL_ "GenSigTimeoutTime" BU_SG_REL_ VCM SG_ 1249 OilLevelDrvInstr_NotHorizonTxt_I 3000;
BA_REL_ "GenSigFirstTimeoutTime" BU_SG_REL_ VCM SG_ 1249 ISeeStatus_ISig_2 12000;
BA_REL_ "GenSigTimeoutTime" BU_SG_REL_ VCM SG_ 1249 ISeeStatus_ISig_2 3000;
BA_REL_ "GenSigFirstTimeoutTime" BU_SG_REL_ VCM SG_ 1041 BrakeInterlockStatus_ISig_2 3000;
BA_REL_ "GenSigTimeoutTime" BU_SG_REL_ VCM SG_ 1041 BrakeInterlockStatus_ISig_2 600;
BA_REL_ "GenSigFirstTimeoutTime" BU_SG_REL_ VCM SG_ 1041 AutGearSplitPosition_ISig_2 3000;
BA_REL_ "GenSigTimeoutTime" BU_SG_REL_ VCM SG_ 1041 AutGearSplitPosition_ISig_2 600;
BA_REL_ "GenSigFirstTimeoutTime" BU_SG_REL_ VCM SG_ 1041 AutoWheelBrakesDownshiftSugges_I 3000;
BA_REL_ "GenSigTimeoutTime" BU_SG_REL_ VCM SG_ 1041 AutoWheelBrakesDownshiftSugges_I 600;
BA_REL_ "GenSigFirstTimeoutTime" BU_SG_REL_ VCM SG_ 1041 GearShiftingRec_Direction_ISig_2 3000;
BA_REL_ "GenSigTimeoutTime" BU_SG_REL_ VCM SG_ 1041 GearShiftingRec_Direction_ISig_2 600;
BA_REL_ "GenSigFirstTimeoutTime" BU_SG_REL_ VCM SG_ 1041 DriveModeSwitchUserOverride_ISig 3000;
BA_REL_ "GenSigTimeoutTime" BU_SG_REL_ VCM SG_ 1041 DriveModeSwitchUserOverride_ISig 600;
BA_REL_ "GenSigFirstTimeoutTime" BU_SG_REL_ VCM SG_ 1041 TransmissionBrakeMode_ISig_2 3000;
BA_REL_ "GenSigTimeoutTime" BU_SG_REL_ VCM SG_ 1041 TransmissionBrakeMode_ISig_2 600;
BA_REL_ "GenSigFirstTimeoutTime" BU_SG_REL_ VCM SG_ 1041 WheelSpdReverseCapMin 3000;
BA_REL_ "GenSigTimeoutTime" BU_SG_REL_ VCM SG_ 1041 WheelSpdReverseCapMin 600;
BA_REL_ "GenSigFirstTimeoutTime" BU_SG_REL_ VCM SG_ 1041 DrivingMode 3000;
BA_REL_ "GenSigTimeoutTime" BU_SG_REL_ VCM SG_ 1041 DrivingMode 600;
BA_REL_ "GenSigFirstTimeoutTime" BU_SG_REL_ VCM SG_ 1041 KickDownModeActive 3000;
BA_REL_ "GenSigTimeoutTime" BU_SG_REL_ VCM SG_ 1041 KickDownModeActive 600;
BA_REL_ "GenSigFirstTimeoutTime" BU_SG_REL_ VCM SG_ 1041 ClutchWearStatus 3000;
BA_REL_ "GenSigTimeoutTime" BU_SG_REL_ VCM SG_ 1041 ClutchWearStatus 600;
BA_REL_ "GenSigFirstTimeoutTime" BU_SG_REL_ VCM SG_ 1041 AutoWheelBrakeInhibited 3000;
BA_REL_ "GenSigTimeoutTime" BU_SG_REL_ VCM SG_ 1041 AutoWheelBrakeInhibited 600;
BA_REL_ "GenSigFirstTimeoutTime" BU_SG_REL_ ECM SG_ 1041 AutoWheelBrakeInhibited 3000;
BA_REL_ "GenSigTimeoutTime" BU_SG_REL_ ECM SG_ 1041 AutoWheelBrakeInhibited 600;
BA_REL_ "GenSigFirstTimeoutTime" BU_SG_REL_ VCM SG_ 1041 TransmissionDrivingMode_ISig_2 3000;
BA_REL_ "GenSigTimeoutTime" BU_SG_REL_ VCM SG_ 1041 TransmissionDrivingMode_ISig_2 600;
BA_REL_ "GenSigFirstTimeoutTime" BU_SG_REL_ VCM SG_ 1041 TrafficSitPathExecSta_Distance 3000;
BA_REL_ "GenSigTimeoutTime" BU_SG_REL_ VCM SG_ 1041 TrafficSitPathExecSta_Distance 600;
BA_REL_ "GenSigFirstTimeoutTime" BU_SG_REL_ VCM SG_ 1041 FuelEcoDrvStatus 3000;
BA_REL_ "GenSigTimeoutTime" BU_SG_REL_ VCM SG_ 1041 FuelEcoDrvStatus 600;
BA_REL_ "GenSigFirstTimeoutTime" BU_SG_REL_ VCM SG_ 1041 TransmissionOilTempHigh_ISig_2 3000;
BA_REL_ "GenSigTimeoutTime" BU_SG_REL_ VCM SG_ 1041 TransmissionOilTempHigh_ISig_2 600;
BA_REL_ "GenSigFirstTimeoutTime" BU_SG_REL_ VCM SG_ 1041 AvailableGearsWithLowerRatio_ISi 3000;
BA_REL_ "GenSigTimeoutTime" BU_SG_REL_ VCM SG_ 1041 AvailableGearsWithLowerRatio_ISi 600;
BA_REL_ "GenSigFirstTimeoutTime" BU_SG_REL_ VCM SG_ 1041 TrafficSitPathExecSta_Type 3000;
BA_REL_ "GenSigTimeoutTime" BU_SG_REL_ VCM SG_ 1041 TrafficSitPathExecSta_Type 600;
BA_REL_ "GenSigFirstTimeoutTime" BU_SG_REL_ ECM SG_ 1041 EcoCruiseStatus 3000;
BA_REL_ "GenSigTimeoutTime" BU_SG_REL_ ECM SG_ 1041 EcoCruiseStatus 600;
BA_REL_ "GenSigFirstTimeoutTime" BU_SG_REL_ VCM SG_ 1041 EcoCruiseStatus 3000;
BA_REL_ "GenSigTimeoutTime" BU_SG_REL_ VCM SG_ 1041 EcoCruiseStatus 600;
BA_REL_ "GenSigFirstTimeoutTime" BU_SG_REL_ VCM SG_ 1041 AvailableGearsWithHigherRatio_IS 3000;
BA_REL_ "GenSigTimeoutTime" BU_SG_REL_ VCM SG_ 1041 AvailableGearsWithHigherRatio_IS 600;
BA_REL_ "GenSigFirstTimeoutTime" BU_SG_REL_ VCM SG_ 1041 WheelSpdForwardCapMin 3000;
BA_REL_ "GenSigTimeoutTime" BU_SG_REL_ VCM SG_ 1041 WheelSpdForwardCapMin 600;
BA_REL_ "GenSigFirstTimeoutTime" BU_SG_REL_ VCM SG_ 1041 TrafficSitPathExecSta_Speed 3000;
BA_REL_ "GenSigTimeoutTime" BU_SG_REL_ VCM SG_ 1041 TrafficSitPathExecSta_Speed 600;
BA_REL_ "GenSigFirstTimeoutTime" BU_SG_REL_ VCM SG_ 1041 GearShiftingRec_Steps_ISig_2 3000;
BA_REL_ "GenSigTimeoutTime" BU_SG_REL_ VCM SG_ 1041 GearShiftingRec_Steps_ISig_2 600;
BA_REL_ "GenSigFirstTimeoutTime" BU_SG_REL_ VCM SG_ 516 ClutchOverloadStatus_ISig_2 3000;
BA_REL_ "GenSigTimeoutTime" BU_SG_REL_ VCM SG_ 516 ClutchOverloadStatus_ISig_2 150;
BA_REL_ "GenSigFirstTimeoutTime" BU_SG_REL_ VCM SG_ 516 TransmissionAirPressureLow_ISig_ 3000;
BA_REL_ "GenSigTimeoutTime" BU_SG_REL_ VCM SG_ 516 TransmissionAirPressureLow_ISig_ 150;
BA_REL_ "GenSigFirstTimeoutTime" BU_SG_REL_ VCM SG_ 516 ACC_SGO_TransmissionStatus 3000;
BA_REL_ "GenSigTimeoutTime" BU_SG_REL_ VCM SG_ 516 ACC_SGO_TransmissionStatus 150;
BA_REL_ "GenSigFirstTimeoutTime" BU_SG_REL_ ECM SG_ 516 ACC_SGO_TransmissionStatus 3000;
BA_REL_ "GenSigTimeoutTime" BU_SG_REL_ ECM SG_ 516 ACC_SGO_TransmissionStatus 150;
BA_REL_ "GenSigFirstTimeoutTime" BU_SG_REL_ ECM SG_ 516 SGoTransmissionSt 3000;
BA_REL_ "GenSigTimeoutTime" BU_SG_REL_ ECM SG_ 516 SGoTransmissionSt 150;
BA_REL_ "GenSigFirstTimeoutTime" BU_SG_REL_ VCM SG_ 516 SGoTransmissionSt 3000;
BA_REL_ "GenSigTimeoutTime" BU_SG_REL_ VCM SG_ 516 SGoTransmissionSt 150;
BA_REL_ "GenSigFirstTimeoutTime" BU_SG_REL_ VCM SG_ 516 TransmissionSystemPowerDownAck 3000;
BA_REL_ "GenSigTimeoutTime" BU_SG_REL_ VCM SG_ 516 TransmissionSystemPowerDownAck 150;
BA_REL_ "GenSigFirstTimeoutTime" BU_SG_REL_ VCM SG_ 516 DirectionGearAllowed 3000;
BA_REL_ "GenSigTimeoutTime" BU_SG_REL_ VCM SG_ 516 DirectionGearAllowed 150;
BA_REL_ "GenSigFirstTimeoutTime" BU_SG_REL_ VCM SG_ 516 TransmEngineStop_req 3000;
BA_REL_ "GenSigTimeoutTime" BU_SG_REL_ VCM SG_ 516 TransmEngineStop_req 150;
BA_REL_ "GenSigFirstTimeoutTime" BU_SG_REL_ ECM SG_ 516 TransmEngineStop_req 3000;
BA_REL_ "GenSigTimeoutTime" BU_SG_REL_ ECM SG_ 516 TransmEngineStop_req 150;
BA_REL_ "GenSigFirstTimeoutTime" BU_SG_REL_ VCM SG_ 516 Pto2Consent 3000;
BA_REL_ "GenSigTimeoutTime" BU_SG_REL_ VCM SG_ 516 Pto2Consent 150;
BA_REL_ "GenSigFirstTimeoutTime" BU_SG_REL_ VCM SG_ 516 EcoRollActiveStatus_ISig_2 3000;
BA_REL_ "GenSigTimeoutTime" BU_SG_REL_ VCM SG_ 516 EcoRollActiveStatus_ISig_2 150;
BA_REL_ "GenSigFirstTimeoutTime" BU_SG_REL_ VCM SG_ 516 GearBoxUnlockAuth_rqst 3000;
BA_REL_ "GenSigTimeoutTime" BU_SG_REL_ VCM SG_ 516 GearBoxUnlockAuth_rqst 150;
BA_REL_ "GenSigFirstTimeoutTime" BU_SG_REL_ VCM SG_ 516 Pto1Consent 3000;
BA_REL_ "GenSigTimeoutTime" BU_SG_REL_ VCM SG_ 516 Pto1Consent 150;
BA_REL_ "GenSigFirstTimeoutTime" BU_SG_REL_ VCM SG_ 516 HorizonRetransmissionReq 3000;
BA_REL_ "GenSigTimeoutTime" BU_SG_REL_ VCM SG_ 516 HorizonRetransmissionReq 150;
BA_REL_ "GenSigFirstTimeoutTime" BU_SG_REL_ VCM SG_ 522 TransmEstimatedTimeToShift 3000;
BA_REL_ "GenSigTimeoutTime" BU_SG_REL_ VCM SG_ 522 TransmEstimatedTimeToShift 120;
BA_REL_ "GenSigFirstTimeoutTime" BU_SG_REL_ VCM SG_ 519 EngPrpCap 3000;
BA_REL_ "GenSigTimeoutTime" BU_SG_REL_ VCM SG_ 519 EngPrpCap 120;
BA_REL_ "GenSigFirstTimeoutTime" BU_SG_REL_ VCM SG_ 519 EngRetCap 3000;
BA_REL_ "GenSigTimeoutTime" BU_SG_REL_ VCM SG_ 519 EngRetCap 120;
BA_REL_ "GenSigFirstTimeoutTime" BU_SG_REL_ VCM SG_ 519 PS_SevereEngAndBrkOverspdWarn_IS 3000;
BA_REL_ "GenSigTimeoutTime" BU_SG_REL_ VCM SG_ 519 PS_SevereEngAndBrkOverspdWarn_IS 120;
BA_REL_ "GenSigFirstTimeoutTime" BU_SG_REL_ VCM SG_ 519 PS_EngineBrakeOverSpeedWarning_I 3000;
BA_REL_ "GenSigTimeoutTime" BU_SG_REL_ VCM SG_ 519 PS_EngineBrakeOverSpeedWarning_I 120;
BA_REL_ "GenSigFirstTimeoutTime" BU_SG_REL_ VCM SG_ 519 DrivelineRetCap 3000;
BA_REL_ "GenSigTimeoutTime" BU_SG_REL_ VCM SG_ 519 DrivelineRetCap 120;
BA_REL_ "GenSigFirstTimeoutTime" BU_SG_REL_ VCM SG_ 519 PS_EngOverSpeedSevereWarning_ISi 3000;
BA_REL_ "GenSigTimeoutTime" BU_SG_REL_ VCM SG_ 519 PS_EngOverSpeedSevereWarning_ISi 120;
BA_REL_ "GenSigFirstTimeoutTime" BU_SG_REL_ VCM SG_ 1098 AltFlagDiffIndication 3000;
BA_REL_ "GenSigTimeoutTime" BU_SG_REL_ VCM SG_ 1098 AltFlagDiffIndication 600;
BA_REL_ "GenSigFirstTimeoutTime" BU_SG_REL_ VCM SG_ 1098 AltFlagElectricalError 3000;
BA_REL_ "GenSigTimeoutTime" BU_SG_REL_ VCM SG_ 1098 AltFlagElectricalError 600;
BA_REL_ "GenSigFirstTimeoutTime" BU_SG_REL_ VCM SG_ 1098 AlternatorDutyCycle 3000;
BA_REL_ "GenSigTimeoutTime" BU_SG_REL_ VCM SG_ 1098 AlternatorDutyCycle 600;
BA_REL_ "GenSigFirstTimeoutTime" BU_SG_REL_ VCM SG_ 1098 WheelSlipControllerMode_ISig_2 3000;
BA_REL_ "GenSigTimeoutTime" BU_SG_REL_ VCM SG_ 1098 WheelSlipControllerMode_ISig_2 600;
BA_REL_ "GenSigFirstTimeoutTime" BU_SG_REL_ VCM SG_ 1098 AltExcitationCurrent 3000;
BA_REL_ "GenSigTimeoutTime" BU_SG_REL_ VCM SG_ 1098 AltExcitationCurrent 600;
BA_REL_ "GenSigFirstTimeoutTime" BU_SG_REL_ VCM SG_ 1098 AltFlagDeexcitation 3000;
BA_REL_ "GenSigTimeoutTime" BU_SG_REL_ VCM SG_ 1098 AltFlagDeexcitation 600;
BA_REL_ "GenSigFirstTimeoutTime" BU_SG_REL_ VCM SG_ 1098 AltFlagHT 3000;
BA_REL_ "GenSigTimeoutTime" BU_SG_REL_ VCM SG_ 1098 AltFlagHT 600;
BA_REL_ "GenSigFirstTimeoutTime" BU_SG_REL_ VCM SG_ 1098 AltMultiplexInfoTx_SelectedInfo 3000;
BA_REL_ "GenSigTimeoutTime" BU_SG_REL_ VCM SG_ 1098 AltMultiplexInfoTx_SelectedInfo 600;
BA_REL_ "GenSigFirstTimeoutTime" BU_SG_REL_ VCM SG_ 1098 DeCompActive_ISig_2 3000;
BA_REL_ "GenSigTimeoutTime" BU_SG_REL_ VCM SG_ 1098 DeCompActive_ISig_2 600;
BA_REL_ "GenSigFirstTimeoutTime" BU_SG_REL_ VCM SG_ 1098 AltCommunicationError 3000;
BA_REL_ "GenSigTimeoutTime" BU_SG_REL_ VCM SG_ 1098 AltCommunicationError 600;
BA_REL_ "GenSigFirstTimeoutTime" BU_SG_REL_ VCM SG_ 1098 AltMultiplexInfoTx_Data 3000;
BA_REL_ "GenSigTimeoutTime" BU_SG_REL_ VCM SG_ 1098 AltMultiplexInfoTx_Data 600;
BA_REL_ "GenSigFirstTimeoutTime" BU_SG_REL_ VCM SG_ 1098 AltFlagMechanicalStatus 3000;
BA_REL_ "GenSigTimeoutTime" BU_SG_REL_ VCM SG_ 1098 AltFlagMechanicalStatus 600;
BA_REL_ "GenSigFirstTimeoutTime" BU_SG_REL_ VCM SG_ 1098 AltFlagTimeout 3000;
BA_REL_ "GenSigTimeoutTime" BU_SG_REL_ VCM SG_ 1098 AltFlagTimeout 600;
BA_REL_ "GenSigFirstTimeoutTime" BU_SG_REL_ VCM SG_ 1288 EcoCruisePwtMaxOvSpeedLev2_ISig_ 24000;
BA_REL_ "GenSigTimeoutTime" BU_SG_REL_ VCM SG_ 1288 EcoCruisePwtMaxOvSpeedLev2_ISig_ 6000;
BA_REL_ "GenSigFirstTimeoutTime" BU_SG_REL_ VCM SG_ 1288 EcoCruisePwtMaxOvSpeedLev0_ISig_ 24000;
BA_REL_ "GenSigTimeoutTime" BU_SG_REL_ VCM SG_ 1288 EcoCruisePwtMaxOvSpeedLev0_ISig_ 6000;
BA_REL_ "GenSigFirstTimeoutTime" BU_SG_REL_ VCM SG_ 1288 AdblueTotalConsumed 24000;
BA_REL_ "GenSigTimeoutTime" BU_SG_REL_ VCM SG_ 1288 AdblueTotalConsumed 6000;
BA_REL_ "GenSigFirstTimeoutTime" BU_SG_REL_ VCM SG_ 1288 TotPTOLNGHighAccuracy 24000;
BA_REL_ "GenSigTimeoutTime" BU_SG_REL_ VCM SG_ 1288 TotPTOLNGHighAccuracy 6000;
BA_REL_ "GenSigFirstTimeoutTime" BU_SG_REL_ VCM SG_ 1288 EcoCruisePwtMaxUnSpeedLev2_ISig_ 24000;
BA_REL_ "GenSigTimeoutTime" BU_SG_REL_ VCM SG_ 1288 EcoCruisePwtMaxUnSpeedLev2_ISig_ 6000;
BA_REL_ "GenSigFirstTimeoutTime" BU_SG_REL_ VCM SG_ 1288 TimeLeftToVehSpdReductionFuel_IS 24000;
BA_REL_ "GenSigTimeoutTime" BU_SG_REL_ VCM SG_ 1288 TimeLeftToVehSpdReductionFuel_IS 6000;
BA_REL_ "GenSigFirstTimeoutTime" BU_SG_REL_ VCM SG_ 1288 MIDistinctWarningExtEMS_ISig_2 24000;
BA_REL_ "GenSigTimeoutTime" BU_SG_REL_ VCM SG_ 1288 MIDistinctWarningExtEMS_ISig_2 6000;
BA_REL_ "GenSigFirstTimeoutTime" BU_SG_REL_ VCM SG_ 1288 EcoCruisePwtMaxOvSpeedLev1_ISig_ 24000;
BA_REL_ "GenSigTimeoutTime" BU_SG_REL_ VCM SG_ 1288 EcoCruisePwtMaxOvSpeedLev1_ISig_ 6000;
BA_REL_ "GenSigFirstTimeoutTime" BU_SG_REL_ VCM SG_ 1288 EcoCruisePwtMaxUnSpeedLev0_ISig_ 24000;
BA_REL_ "GenSigTimeoutTime" BU_SG_REL_ VCM SG_ 1288 EcoCruisePwtMaxUnSpeedLev0_ISig_ 6000;
BA_REL_ "GenSigFirstTimeoutTime" BU_SG_REL_ VCM SG_ 1288 TopGearUseDistance_ISig_2 24000;
BA_REL_ "GenSigTimeoutTime" BU_SG_REL_ VCM SG_ 1288 TopGearUseDistance_ISig_2 6000;
BA_REL_ "GenSigFirstTimeoutTime" BU_SG_REL_ VCM SG_ 1288 TorqueReductionStatus_OBD_ISig_2 24000;
BA_REL_ "GenSigTimeoutTime" BU_SG_REL_ VCM SG_ 1288 TorqueReductionStatus_OBD_ISig_2 6000;
BA_REL_ "GenSigFirstTimeoutTime" BU_SG_REL_ VCM SG_ 1288 TimeLeftToTorqueReductionFuel_IS 24000;
BA_REL_ "GenSigTimeoutTime" BU_SG_REL_ VCM SG_ 1288 TimeLeftToTorqueReductionFuel_IS 6000;
BA_REL_ "GenSigFirstTimeoutTime" BU_SG_REL_ VCM SG_ 1288 OBDDrivingCycle 24000;
BA_REL_ "GenSigTimeoutTime" BU_SG_REL_ VCM SG_ 1288 OBDDrivingCycle 6000;
BA_REL_ "GenSigFirstTimeoutTime" BU_SG_REL_ VCM SG_ 1288 TimetoCompleteParkRegen_ISig_2 24000;
BA_REL_ "GenSigTimeoutTime" BU_SG_REL_ VCM SG_ 1288 TimetoCompleteParkRegen_ISig_2 6000;
BA_REL_ "GenSigFirstTimeoutTime" BU_SG_REL_ VCM SG_ 1288 MIStatus 24000;
BA_REL_ "GenSigTimeoutTime" BU_SG_REL_ VCM SG_ 1288 MIStatus 6000;
BA_REL_ "GenSigFirstTimeoutTime" BU_SG_REL_ VCM SG_ 1288 SCROperatorInducementSeverity_IS 24000;
BA_REL_ "GenSigTimeoutTime" BU_SG_REL_ VCM SG_ 1288 SCROperatorInducementSeverity_IS 6000;
BA_REL_ "GenSigFirstTimeoutTime" BU_SG_REL_ VCM SG_ 1288 TimeLeftToTorqueReduction_OBD_IS 24000;
BA_REL_ "GenSigTimeoutTime" BU_SG_REL_ VCM SG_ 1288 TimeLeftToTorqueReduction_OBD_IS 6000;
BA_REL_ "GenSigFirstTimeoutTime" BU_SG_REL_ VCM SG_ 1288 EMS_Available_Log 24000;
BA_REL_ "GenSigTimeoutTime" BU_SG_REL_ VCM SG_ 1288 EMS_Available_Log 6000;
BA_REL_ "GenSigFirstTimeoutTime" BU_SG_REL_ VCM SG_ 1288 FuelOperatorDeratingSeverity_ISi 24000;
BA_REL_ "GenSigTimeoutTime" BU_SG_REL_ VCM SG_ 1288 FuelOperatorDeratingSeverity_ISi 6000;
BA_REL_ "GenSigFirstTimeoutTime" BU_SG_REL_ VCM SG_ 1288 MIDistinctWarning_ISig_2 24000;
BA_REL_ "GenSigTimeoutTime" BU_SG_REL_ VCM SG_ 1288 MIDistinctWarning_ISig_2 6000;
BA_REL_ "GenSigFirstTimeoutTime" BU_SG_REL_ VCM SG_ 1288 SCROperatorInducementReason_ISig 24000;
BA_REL_ "GenSigTimeoutTime" BU_SG_REL_ VCM SG_ 1288 SCROperatorInducementReason_ISig 6000;
BA_REL_ "GenSigFirstTimeoutTime" BU_SG_REL_ VCM SG_ 1288 StarterMotorActivations 24000;
BA_REL_ "GenSigTimeoutTime" BU_SG_REL_ VCM SG_ 1288 StarterMotorActivations 6000;
BA_REL_ "GenSigFirstTimeoutTime" BU_SG_REL_ VCM SG_ 1288 EcoCruisePwtMaxUnSpeedLev1_ISig_ 24000;
BA_REL_ "GenSigTimeoutTime" BU_SG_REL_ VCM SG_ 1288 EcoCruisePwtMaxUnSpeedLev1_ISig_ 6000;
BA_REL_ "GenSigFirstTimeoutTime" BU_SG_REL_ VCM SG_ 1288 MIStatusExtEMS_ISig_2 24000;
BA_REL_ "GenSigTimeoutTime" BU_SG_REL_ VCM SG_ 1288 MIStatusExtEMS_ISig_2 6000;
BA_REL_ "GenSigFirstTimeoutTime" BU_SG_REL_ VCM SG_ 1288 EcoCruisePwtMaxUnSpeedLev3_ISig_ 24000;
BA_REL_ "GenSigTimeoutTime" BU_SG_REL_ VCM SG_ 1288 EcoCruisePwtMaxUnSpeedLev3_ISig_ 6000;
BA_REL_ "GenSigFirstTimeoutTime" BU_SG_REL_ VCM SG_ 1288 EcoCruisePwtMaxOvSpeedLev3_ISig_ 24000;
BA_REL_ "GenSigTimeoutTime" BU_SG_REL_ VCM SG_ 1288 EcoCruisePwtMaxOvSpeedLev3_ISig_ 6000;
BA_REL_ "GenSigFirstTimeoutTime" BU_SG_REL_ VCM SG_ 1288 DistLeftToSevereInducement_OBD_I 24000;
BA_REL_ "GenSigTimeoutTime" BU_SG_REL_ VCM SG_ 1288 DistLeftToSevereInducement_OBD_I 6000;
BA_REL_ "GenSigFirstTimeoutTime" BU_SG_REL_ VCM SG_ 1288 FuelOperatorDeratingReason_ISig_ 24000;
BA_REL_ "GenSigTimeoutTime" BU_SG_REL_ VCM SG_ 1288 FuelOperatorDeratingReason_ISig_ 6000;
BA_REL_ "GenSigFirstTimeoutTime" BU_SG_REL_ VCM SG_ 1282 LNGOperatorInducementReason_ISig 12000;
BA_REL_ "GenSigTimeoutTime" BU_SG_REL_ VCM SG_ 1282 LNGOperatorInducementReason_ISig 3000;
BA_REL_ "GenSigFirstTimeoutTime" BU_SG_REL_ VCM SG_ 1282 EngineFuelMode 12000;
BA_REL_ "GenSigTimeoutTime" BU_SG_REL_ VCM SG_ 1282 EngineFuelMode 3000;
BA_REL_ "GenSigFirstTimeoutTime" BU_SG_REL_ VCM SG_ 1282 EngineTotalLngConsumed_ISig_2 12000;
BA_REL_ "GenSigTimeoutTime" BU_SG_REL_ VCM SG_ 1282 EngineTotalLngConsumed_ISig_2 3000;
BA_REL_ "GenSigFirstTimeoutTime" BU_SG_REL_ VCM SG_ 1282 ExhManif_EMAIAirTankPres 12000;
BA_REL_ "GenSigTimeoutTime" BU_SG_REL_ VCM SG_ 1282 ExhManif_EMAIAirTankPres 3000;
BA_REL_ "GenSigFirstTimeoutTime" BU_SG_REL_ VCM SG_ 1392 EngineRunningTime_ISig_2 28800;
BA_REL_ "GenSigTimeoutTime" BU_SG_REL_ VCM SG_ 1392 EngineRunningTime_ISig_2 7200;
BA_REL_ "GenSigFirstTimeoutTime" BU_SG_REL_ VCM SG_ 1392 TotPTOFuelHighAccuracy 28800;
BA_REL_ "GenSigTimeoutTime" BU_SG_REL_ VCM SG_ 1392 TotPTOFuelHighAccuracy 7200;
BA_REL_ "GenSigFirstTimeoutTime" BU_SG_REL_ VCM SG_ 1391 OilPrediction_RemainDist 36000;
BA_REL_ "GenSigTimeoutTime" BU_SG_REL_ VCM SG_ 1391 OilPrediction_RemainDist 9000;
BA_REL_ "GenSigFirstTimeoutTime" BU_SG_REL_ VCM SG_ 1391 TimeLeftToVehSpdReduction_OBD_IS 36000;
BA_REL_ "GenSigTimeoutTime" BU_SG_REL_ VCM SG_ 1391 TimeLeftToVehSpdReduction_OBD_IS 9000;
BA_REL_ "GenSigFirstTimeoutTime" BU_SG_REL_ VCM SG_ 1391 OilPrediction_RemainTime 36000;
BA_REL_ "GenSigTimeoutTime" BU_SG_REL_ VCM SG_ 1391 OilPrediction_RemainTime 9000;
BA_REL_ "GenSigFirstTimeoutTime" BU_SG_REL_ VCM SG_ 1391 TimeToCorrectOilLevel 36000;
BA_REL_ "GenSigTimeoutTime" BU_SG_REL_ VCM SG_ 1391 TimeToCorrectOilLevel 9000;
BA_REL_ "GenSigFirstTimeoutTime" BU_SG_REL_ VCM SG_ 1391 OilPrediction_Status 36000;
BA_REL_ "GenSigTimeoutTime" BU_SG_REL_ VCM SG_ 1391 OilPrediction_Status 9000;
BA_REL_ "GenSigFirstTimeoutTime" BU_SG_REL_ VCM SG_ 1391 OilPrediction_Quality 36000;
BA_REL_ "GenSigTimeoutTime" BU_SG_REL_ VCM SG_ 1391 OilPrediction_Quality 9000;
BA_REL_ "GenSigFirstTimeoutTime" BU_SG_REL_ VCM SG_ 1279 AirFilterPressureDrop 6000;
BA_REL_ "GenSigTimeoutTime" BU_SG_REL_ VCM SG_ 1279 AirFilterPressureDrop 1500;
BA_REL_ "GenSigFirstTimeoutTime" BU_SG_REL_ VCM SG_ 1279 EngineTotalFuelConsumed_ISig_2 6000;
BA_REL_ "GenSigTimeoutTime" BU_SG_REL_ VCM SG_ 1279 EngineTotalFuelConsumed_ISig_2 1500;
BA_REL_ "GenSigFirstTimeoutTime" BU_SG_REL_ TCM SG_ 1279 EngineTotalFuelConsumed_ISig_2 6000;
BA_REL_ "GenSigTimeoutTime" BU_SG_REL_ TCM SG_ 1279 EngineTotalFuelConsumed_ISig_2 1500;
BA_REL_ "GenSigFirstTimeoutTime" BU_SG_REL_ VCM SG_ 1279 FuelFilterClogged_ISig_2 6000;
BA_REL_ "GenSigTimeoutTime" BU_SG_REL_ VCM SG_ 1279 FuelFilterClogged_ISig_2 1500;
BA_REL_ "GenSigFirstTimeoutTime" BU_SG_REL_ VCM SG_ 1279 CoolantPumpEngagementStatus_ISig 6000;
BA_REL_ "GenSigTimeoutTime" BU_SG_REL_ VCM SG_ 1279 CoolantPumpEngagementStatus_ISig 1500;
BA_REL_ "GenSigFirstTimeoutTime" BU_SG_REL_ TCM SG_ 1279 BarometricPressure_ISig_2 6000;
BA_REL_ "GenSigTimeoutTime" BU_SG_REL_ TCM SG_ 1279 BarometricPressure_ISig_2 1500;
BA_REL_ "GenSigFirstTimeoutTime" BU_SG_REL_ VCM SG_ 1279 BarometricPressure_ISig_2 6000;
BA_REL_ "GenSigTimeoutTime" BU_SG_REL_ VCM SG_ 1279 BarometricPressure_ISig_2 1500;
BA_REL_ "GenSigFirstTimeoutTime" BU_SG_REL_ VCM SG_ 1279 StarterMotorRecoveryTime_ISig_2 6000;
BA_REL_ "GenSigTimeoutTime" BU_SG_REL_ VCM SG_ 1279 StarterMotorRecoveryTime_ISig_2 1500;
BA_REL_ "GenSigFirstTimeoutTime" BU_SG_REL_ VCM SG_ 1279 CoolantTempGaugeAdjustment_ISig_ 6000;
BA_REL_ "GenSigTimeoutTime" BU_SG_REL_ VCM SG_ 1279 CoolantTempGaugeAdjustment_ISig_ 1500;
BA_REL_ "GenSigFirstTimeoutTime" BU_SG_REL_ VCM SG_ 1279 DrainPrimingStatus_ISig_2 6000;
BA_REL_ "GenSigTimeoutTime" BU_SG_REL_ VCM SG_ 1279 DrainPrimingStatus_ISig_2 1500;
BA_REL_ "GenSigFirstTimeoutTime" BU_SG_REL_ VCM SG_ 1279 CoolantLevelLow 6000;
BA_REL_ "GenSigTimeoutTime" BU_SG_REL_ VCM SG_ 1279 CoolantLevelLow 1500;
BA_REL_ "GenSigFirstTimeoutTime" BU_SG_REL_ VCM SG_ 1279 AverageFuelEconomy_ISig_2 6000;
BA_REL_ "GenSigTimeoutTime" BU_SG_REL_ VCM SG_ 1279 AverageFuelEconomy_ISig_2 1500;
BA_REL_ "GenSigFirstTimeoutTime" BU_SG_REL_ VCM SG_ 1279 EngineProtDerateStat 6000;
BA_REL_ "GenSigTimeoutTime" BU_SG_REL_ VCM SG_ 1279 EngineProtDerateStat 1500;
BA_REL_ "GenSigFirstTimeoutTime" BU_SG_REL_ VCM SG_ 1279 EngineAirInletTemperature 6000;
BA_REL_ "GenSigTimeoutTime" BU_SG_REL_ VCM SG_ 1279 EngineAirInletTemperature 1500;
BA_REL_ "GenSigFirstTimeoutTime" BU_SG_REL_ VCM SG_ 1279 FuelEcoEngStatus 6000;
BA_REL_ "GenSigTimeoutTime" BU_SG_REL_ VCM SG_ 1279 FuelEcoEngStatus 1500;
BA_REL_ "GenSigFirstTimeoutTime" BU_SG_REL_ VCM SG_ 1279 OilLevelLow_ISig_2 6000;
BA_REL_ "GenSigTimeoutTime" BU_SG_REL_ VCM SG_ 1279 OilLevelLow_ISig_2 1500;
BA_REL_ "GenSigFirstTimeoutTime" BU_SG_REL_ VCM SG_ 1279 AutoWheelBrakesStatus_ISig_2 6000;
BA_REL_ "GenSigTimeoutTime" BU_SG_REL_ VCM SG_ 1279 AutoWheelBrakesStatus_ISig_2 1500;
BA_REL_ "GenSigFirstTimeoutTime" BU_SG_REL_ TCM SG_ 1279 AutoWheelBrakesStatus_ISig_2 6000;
BA_REL_ "GenSigTimeoutTime" BU_SG_REL_ TCM SG_ 1279 AutoWheelBrakesStatus_ISig_2 1500;
BA_REL_ "GenSigFirstTimeoutTime" BU_SG_REL_ VCM SG_ 1279 EngineFanOverspeed_ISig_2 6000;
BA_REL_ "GenSigTimeoutTime" BU_SG_REL_ VCM SG_ 1279 EngineFanOverspeed_ISig_2 1500;
BA_REL_ "GenSigFirstTimeoutTime" BU_SG_REL_ VCM SG_ 1279 InletAirHeaterStatus1_ISig_2 6000;
BA_REL_ "GenSigTimeoutTime" BU_SG_REL_ VCM SG_ 1279 InletAirHeaterStatus1_ISig_2 1500;
BA_REL_ "GenSigFirstTimeoutTime" BU_SG_REL_ VCM SG_ 1279 TopGearMode 6000;
BA_REL_ "GenSigTimeoutTime" BU_SG_REL_ VCM SG_ 1279 TopGearMode 1500;
BA_REL_ "GenSigFirstTimeoutTime" BU_SG_REL_ VCM SG_ 1279 CoolantTempHigh_ISig_2 6000;
BA_REL_ "GenSigTimeoutTime" BU_SG_REL_ VCM SG_ 1279 CoolantTempHigh_ISig_2 1500;
BA_REL_ "GenSigFirstTimeoutTime" BU_SG_REL_ TCM SG_ 1279 AppliedVehicleSpeedLimit 6000;
BA_REL_ "GenSigTimeoutTime" BU_SG_REL_ TCM SG_ 1279 AppliedVehicleSpeedLimit 1500;
BA_REL_ "GenSigFirstTimeoutTime" BU_SG_REL_ VCM SG_ 1279 AppliedVehicleSpeedLimit 6000;
BA_REL_ "GenSigTimeoutTime" BU_SG_REL_ VCM SG_ 1279 AppliedVehicleSpeedLimit 1500;
BA_REL_ "GenSigFirstTimeoutTime" BU_SG_REL_ VCM SG_ 1279 EnergyForNextCrank_ISig_2 6000;
BA_REL_ "GenSigTimeoutTime" BU_SG_REL_ VCM SG_ 1279 EnergyForNextCrank_ISig_2 1500;
BA_REL_ "GenSigFirstTimeoutTime" BU_SG_REL_ VCM SG_ 1279 OilPressureLow_ISig_2 6000;
BA_REL_ "GenSigTimeoutTime" BU_SG_REL_ VCM SG_ 1279 OilPressureLow_ISig_2 1500;
BA_REL_ "GenSigFirstTimeoutTime" BU_SG_REL_ VCM SG_ 1279 DPF_ParkedRegenStatus_ISig_2 6000;
BA_REL_ "GenSigTimeoutTime" BU_SG_REL_ VCM SG_ 1279 DPF_ParkedRegenStatus_ISig_2 1500;
BA_REL_ "GenSigFirstTimeoutTime" BU_SG_REL_ VCM SG_ 1279 StarterMotorReset_ack 6000;
BA_REL_ "GenSigTimeoutTime" BU_SG_REL_ VCM SG_ 1279 StarterMotorReset_ack 1500;
BA_REL_ "GenSigFirstTimeoutTime" BU_SG_REL_ VCM SG_ 1279 EngineCoolingFanSpeed_ISig_2 6000;
BA_REL_ "GenSigTimeoutTime" BU_SG_REL_ VCM SG_ 1279 EngineCoolingFanSpeed_ISig_2 1500;
BA_REL_ "GenSigFirstTimeoutTime" BU_SG_REL_ VCM SG_ 1279 EngineGasRate 6000;
BA_REL_ "GenSigTimeoutTime" BU_SG_REL_ VCM SG_ 1279 EngineGasRate 1500;
BA_REL_ "GenSigFirstTimeoutTime" BU_SG_REL_ VCM SG_ 1279 DMSDriverFollow 6000;
BA_REL_ "GenSigTimeoutTime" BU_SG_REL_ VCM SG_ 1279 DMSDriverFollow 1500;
BA_REL_ "GenSigFirstTimeoutTime" BU_SG_REL_ VCM SG_ 719 XARActiveControlMode 3000;
BA_REL_ "GenSigTimeoutTime" BU_SG_REL_ VCM SG_ 719 XARActiveControlMode 300;
BA_REL_ "GenSigFirstTimeoutTime" BU_SG_REL_ VCM SG_ 719 WarmUpCycle 3000;
BA_REL_ "GenSigTimeoutTime" BU_SG_REL_ VCM SG_ 719 WarmUpCycle 300;
BA_REL_ "GenSigFirstTimeoutTime" BU_SG_REL_ VCM SG_ 719 DeterminedGear 3000;
BA_REL_ "GenSigTimeoutTime" BU_SG_REL_ VCM SG_ 719 DeterminedGear 300;
BA_REL_ "GenSigFirstTimeoutTime" BU_SG_REL_ VCM SG_ 719 DPF_LimitedSpeedDuetoInhibit_ISi 3000;
BA_REL_ "GenSigTimeoutTime" BU_SG_REL_ VCM SG_ 719 DPF_LimitedSpeedDuetoInhibit_ISi 300;
BA_REL_ "GenSigFirstTimeoutTime" BU_SG_REL_ VCM SG_ 719 AirFilter_Pressure 3000;
BA_REL_ "GenSigTimeoutTime" BU_SG_REL_ VCM SG_ 719 AirFilter_Pressure 300;
BA_REL_ "GenSigFirstTimeoutTime" BU_SG_REL_ VCM SG_ 719 CCControllerMode 3000;
BA_REL_ "GenSigTimeoutTime" BU_SG_REL_ VCM SG_ 719 CCControllerMode 300;
BA_REL_ "GenSigFirstTimeoutTime" BU_SG_REL_ VCM SG_ 719 ExhManif_AirInjActive 3000;
BA_REL_ "GenSigTimeoutTime" BU_SG_REL_ VCM SG_ 719 ExhManif_AirInjActive 300;
BA_REL_ "GenSigFirstTimeoutTime" BU_SG_REL_ VCM SG_ 719 AirFilter_AirMassFlowValidated 3000;
BA_REL_ "GenSigTimeoutTime" BU_SG_REL_ VCM SG_ 719 AirFilter_AirMassFlowValidated 300;
BA_REL_ "GenSigFirstTimeoutTime" BU_SG_REL_ VCM SG_ 719 CCBControllerMode 3000;
BA_REL_ "GenSigTimeoutTime" BU_SG_REL_ VCM SG_ 719 CCBControllerMode 300;
BA_REL_ "GenSigFirstTimeoutTime" BU_SG_REL_ VCM SG_ 719 CCSetSpeedApplied 3000;
BA_REL_ "GenSigTimeoutTime" BU_SG_REL_ VCM SG_ 719 CCSetSpeedApplied 300;
BA_REL_ "GenSigFirstTimeoutTime" BU_SG_REL_ VCM SG_ 719 EngineSystemPowerDownAck 3000;
BA_REL_ "GenSigTimeoutTime" BU_SG_REL_ VCM SG_ 719 EngineSystemPowerDownAck 300;
BA_REL_ "GenSigFirstTimeoutTime" BU_SG_REL_ VCM SG_ 719 RegenInhibDueHeight_ISig_2 3000;
BA_REL_ "GenSigTimeoutTime" BU_SG_REL_ VCM SG_ 719 RegenInhibDueHeight_ISig_2 300;
BA_REL_ "GenSigFirstTimeoutTime" BU_SG_REL_ VCM SG_ 719 XARSystemState 3000;
BA_REL_ "GenSigTimeoutTime" BU_SG_REL_ VCM SG_ 719 XARSystemState 300;
BA_REL_ "GenSigFirstTimeoutTime" BU_SG_REL_ VCM SG_ 719 EngineStartAuth_rqst 3000;
BA_REL_ "GenSigTimeoutTime" BU_SG_REL_ VCM SG_ 719 EngineStartAuth_rqst 300;
BA_REL_ "GenSigFirstTimeoutTime" BU_SG_REL_ VCM SG_ 719 EngCompartmentStopSwitchStat 3000;
BA_REL_ "GenSigTimeoutTime" BU_SG_REL_ VCM SG_ 719 EngCompartmentStopSwitchStat 300;
BA_REL_ "GenSigFirstTimeoutTime" BU_SG_REL_ VCM SG_ 719 PwtEngineTmpryStopAllowed 3000;
BA_REL_ "GenSigTimeoutTime" BU_SG_REL_ VCM SG_ 719 PwtEngineTmpryStopAllowed 300;
BA_REL_ "GenSigFirstTimeoutTime" BU_SG_REL_ VCM SG_ 719 IntakeAirTemperatureAlert 3000;
BA_REL_ "GenSigTimeoutTime" BU_SG_REL_ VCM SG_ 719 IntakeAirTemperatureAlert 300;
BA_REL_ "GenSigFirstTimeoutTime" BU_SG_REL_ VCM SG_ 719 EngineOilTempHigh_ISig_2 3000;
BA_REL_ "GenSigTimeoutTime" BU_SG_REL_ VCM SG_ 719 EngineOilTempHigh_ISig_2 300;
BA_REL_ "GenSigFirstTimeoutTime" BU_SG_REL_ VCM SG_ 719 XRSLControllerMode_ISig_2 3000;
BA_REL_ "GenSigTimeoutTime" BU_SG_REL_ VCM SG_ 719 XRSLControllerMode_ISig_2 300;
BA_REL_ "GenSigFirstTimeoutTime" BU_SG_REL_ VCM SG_ 719 InhibitIdleShutdownStatus 3000;
BA_REL_ "GenSigTimeoutTime" BU_SG_REL_ VCM SG_ 719 InhibitIdleShutdownStatus 300;
BA_REL_ "GenSigFirstTimeoutTime" BU_SG_REL_ VCM SG_ 719 CrankcasePressureHigh 3000;
BA_REL_ "GenSigTimeoutTime" BU_SG_REL_ VCM SG_ 719 CrankcasePressureHigh 300;
BA_REL_ "GenSigFirstTimeoutTime" BU_SG_REL_ VCM SG_ 719 CCBSetSpeedApplied 3000;
BA_REL_ "GenSigTimeoutTime" BU_SG_REL_ VCM SG_ 719 CCBSetSpeedApplied 300;
BA_REL_ "GenSigFirstTimeoutTime" BU_SG_REL_ VCM SG_ 719 EngineAirInletPressure 3000;
BA_REL_ "GenSigTimeoutTime" BU_SG_REL_ VCM SG_ 719 EngineAirInletPressure 300;
BA_REL_ "GenSigFirstTimeoutTime" BU_SG_REL_ VCM SG_ 1519 DiagFaultStat_TECU_DtcIdB 24000;
BA_REL_ "GenSigTimeoutTime" BU_SG_REL_ VCM SG_ 1519 DiagFaultStat_TECU_DtcIdB 6000;
BA_REL_ "GenSigFirstTimeoutTime" BU_SG_REL_ VCM SG_ 1519 DiagFaultStat_TECU_EcuAdr 24000;
BA_REL_ "GenSigTimeoutTime" BU_SG_REL_ VCM SG_ 1519 DiagFaultStat_TECU_EcuAdr 6000;
BA_REL_ "GenSigFirstTimeoutTime" BU_SG_REL_ VCM SG_ 1519 DiagFaultStat_TECU_DtcIdA 24000;
BA_REL_ "GenSigTimeoutTime" BU_SG_REL_ VCM SG_ 1519 DiagFaultStat_TECU_DtcIdA 6000;
BA_REL_ "GenSigFirstTimeoutTime" BU_SG_REL_ VCM SG_ 1519 DiagFaultStat_TECU_FailTB 24000;
BA_REL_ "GenSigTimeoutTime" BU_SG_REL_ VCM SG_ 1519 DiagFaultStat_TECU_FailTB 6000;
BA_REL_ "GenSigFirstTimeoutTime" BU_SG_REL_ VCM SG_ 1519 DiagFaultStat_TECU_FailTA 24000;
BA_REL_ "GenSigTimeoutTime" BU_SG_REL_ VCM SG_ 1519 DiagFaultStat_TECU_FailTA 6000;
BA_REL_ "GenSigFirstTimeoutTime" BU_SG_REL_ VCM SG_ 1511 DiagFaultStat_EMS_DtcIdB 24000;
BA_REL_ "GenSigTimeoutTime" BU_SG_REL_ VCM SG_ 1511 DiagFaultStat_EMS_DtcIdB 6000;
BA_REL_ "GenSigFirstTimeoutTime" BU_SG_REL_ VCM SG_ 1511 DiagFaultStat_EMS_EcuAdr 24000;
BA_REL_ "GenSigTimeoutTime" BU_SG_REL_ VCM SG_ 1511 DiagFaultStat_EMS_EcuAdr 6000;
BA_REL_ "GenSigFirstTimeoutTime" BU_SG_REL_ VCM SG_ 1511 DiagFaultStat_EMS_DtcIdA 24000;
BA_REL_ "GenSigTimeoutTime" BU_SG_REL_ VCM SG_ 1511 DiagFaultStat_EMS_DtcIdA 6000;
BA_REL_ "GenSigFirstTimeoutTime" BU_SG_REL_ VCM SG_ 1511 DiagFaultStat_EMS_FailTA 24000;
BA_REL_ "GenSigTimeoutTime" BU_SG_REL_ VCM SG_ 1511 DiagFaultStat_EMS_FailTA 6000;
BA_REL_ "GenSigFirstTimeoutTime" BU_SG_REL_ VCM SG_ 1511 DiagFaultStat_EMS_FailTB 24000;
BA_REL_ "GenSigTimeoutTime" BU_SG_REL_ VCM SG_ 1511 DiagFaultStat_EMS_FailTB 6000;
VAL_ 1414 GPSData_AntennaStat 7 "GPS_Antenna_status_NA" 6 "GPS_Antenna_status_ErrorIndicator" 5 "GPS_Antenna_status_SpareValue_01" 4 "GPS_Antenna_status_SpareValue" 3 "GPS_Antenna_status_AntennaStatusUnknown" 2 "GPS_Antenna_status_AntennaInit" 1 "GPS_Antenna_status_AntennaDisconnected" 0 "GPS_Antenna_status_AntennaStatusOK" ;
VAL_ 1249 OilLevelDrvInstr_StopVehicle_ISi 3 "DisplayText_NotAvailable" 2 "DisplayText_Error" 1 "DisplayText_DisplayText" 0 "DisplayText_DoNotDisplayText" ;
VAL_ 1249 ClutchCalibration_stat_ISig_2 3 "InactiveActive_NotAvailable" 2 "InactiveActive_Error" 1 "InactiveActive_Active" 0 "InactiveActive_Inactive" ;
VAL_ 1249 OilLevelDrvInstr_OilTempTxt_ISig 3 "DisplayText_NotAvailable" 2 "DisplayText_Error" 1 "DisplayText_DisplayText" 0 "DisplayText_DoNotDisplayText" ;
VAL_ 1249 OilLevelDrvInstr_Wait60SecTxt_IS 3 "DisplayText_NotAvailable" 2 "DisplayText_Error" 1 "DisplayText_DisplayText" 0 "DisplayText_DoNotDisplayText" ;
VAL_ 1249 EcoRollEnabledStatus_ISig_2 3 "DisableEnable_NotAvailable" 2 "DisableEnable_Error" 1 "DisableEnable_Enable" 0 "DisableEnable_Disable" ;
VAL_ 1249 ClutchAbuseStatus_ISig_2 3 "ClutchAbuseStatus_NotAvailable" 2 "ClutchAbuseStatus_Error" 1 "ClutchAbuseStatus_ClutchAbused" 0 "ClutchAbuseStatus_ClutchNotAbused" ;
VAL_ 1249 SchwungStatus 3 "InactiveActive_NotAvailable" 2 "InactiveActive_Error" 1 "InactiveActive_Active" 0 "InactiveActive_Inactive" ;
VAL_ 1249 OilLevelDrvInstr_ChangeGearTxt_I 3 "DisplayText_NotAvailable" 2 "DisplayText_Error" 1 "DisplayText_DisplayText" 0 "DisplayText_DoNotDisplayText" ;
VAL_ 1249 OilLevelDrvInstr_IncorrEngSpe_IS 3 "DisplayText_NotAvailable" 2 "DisplayText_Error" 1 "DisplayText_DisplayText" 0 "DisplayText_DoNotDisplayText" ;
VAL_ 1249 CACCSuitability 3 "Suitable_NotAvailable" 2 "Suitable_Error" 1 "Suitable_Suitable" 0 "Suitable_NotSuitable" ;
VAL_ 1249 HillDataCtrlTECU_State 7 "HillDataState_NotAvailable" 6 "HillDataState_Error" 5 "HillDataState_Spare_03" 4 "HillDataState_Spare_02" 3 "HillDataState_Spare_01" 2 "HillDataState_Receive" 1 "HillDataState_Request" 0 "HillDataState_Idle" ;
VAL_ 1249 TransmissionSplitboxPTOMode_ISig 7 "TransmissionSplitboxPTOMode_NotAvailable" 6 "TransmissionSplitboxPTOMode_Error" 5 "TransmissionSplitboxPTOMode_Spare3" 4 "TransmissionSplitboxPTOMode_Spare2" 3 "TransmissionSplitboxPTOMode_Spare1" 2 "TransmissionSplitboxPTOMode_Running" 1 "TransmissionSplitboxPTOMode_Standby" 0 "TransmissionSplitboxPTOMode_Inactive" ;
VAL_ 1249 OilLevelDrvInstr_NotHorizonTxt_I 3 "DisplayText_NotAvailable" 2 "DisplayText_Error" 1 "DisplayText_DisplayText" 0 "DisplayText_DoNotDisplayText" ;
VAL_ 1249 ISeeStatus_ISig_2 7 "ISeeStatus_NotAvailable" 6 "ISeeStatus_Error" 5 "ISeeStatus_Spare2" 4 "ISeeStatus_Spare1" 3 "ISeeStatus_EnabledAndActive" 2 "ISeeStatus_EnabledButInactive" 1 "ISeeStatus_Disabled" 0 "ISeeStatus_Off" ;
VAL_ 1041 BrakeInterlockStatus_ISig_2 3 "OffOn_NotAvailable" 2 "OffOn_Error" 1 "OffOn_On" 0 "OffOn_Off" ;
VAL_ 1041 AutGearSplitPosition_ISig_2 7 "GearSplitPosition_NotAvailable" 6 "GearSplitPosition_Error" 5 "GearSplitPosition_Spare2" 4 "GearSplitPosition_Spare1" 3 "GearSplitPosition_Crawler" 2 "GearSplitPosition_NoSplit" 1 "GearSplitPosition_HighSplit" 0 "GearSplitPosition_LowSplit" ;
VAL_ 1041 AutoWheelBrakesDownshiftSugges_I 3 "DownshiftSuggest_NotAvailable" 2 "DownshiftSuggest_Error" 1 "DownshiftSuggest_SuggestDownshift" 0 "DownshiftSuggest_NoSuggestion" ;
VAL_ 1041 GearShiftingRec_Direction_ISig_2 7 "GearShiftingDirection_NotAvailable" 6 "GearShiftingDirection_Error" 5 "GearShiftingDirection_Spare3" 4 "GearShiftingDirection_Spare2" 3 "GearShiftingDirection_Spare1" 2 "GearShiftingDirection_Down" 1 "GearShiftingDirection_Up" 0 "GearShiftingDirection_NoShiftRecommendation" ;
VAL_ 1041 DriveModeSwitchUserOverride_ISig 7 "DriveModeSwitchUserOverride_NotAvailable" 6 "DriveModeSwitchUserOverride_Error" 5 "DriveModeSwitchUserOverride_Spare" 4 "DriveModeSwitchUserOverride_OverrideStandard" 3 "DriveModeSwitchUserOverride_RequestRange" 2 "DriveModeSwitchUserOverride_OverridePerformance" 1 "DriveModeSwitchUserOverride_AutoSwitch" 0 "DriveModeSwitchUserOverride_None" ;
VAL_ 1041 TransmissionBrakeMode_ISig_2 3 "InactiveActive_NotAvailable" 2 "InactiveActive_Error" 1 "InactiveActive_Active" 0 "InactiveActive_Inactive" ;
VAL_ 1041 KickDownModeActive 3 "InactiveActive_NotAvailable" 2 "InactiveActive_Error" 1 "InactiveActive_Active" 0 "InactiveActive_Inactive" ;
VAL_ 1041 AutoWheelBrakeInhibited 3 "InhibitedStatus_NotAvailable" 2 "InhibitedStatus_Error" 1 "InhibitedStatus_Inhibited" 0 "InhibitedStatus_NotInhibited" ;
VAL_ 1041 TransmissionDrivingMode_ISig_2 7 "TransmissionDrivingMode_NotAvailable" 6 "TransmissionDrivingMode_KickDown" 5 "TransmissionDrivingMode_Dynamometer" 4 "TransmissionDrivingMode_HeavyDuty" 3 "TransmissionDrivingMode_OffRoad" 2 "TransmissionDrivingMode_Performance" 1 "TransmissionDrivingMode_Balanced_Standard" 0 "TransmissionDrivingMode_EconomyExtra_Range" ;
VAL_ 1041 FuelEcoDrvStatus 3 "InactiveActive_NotAvailable" 2 "InactiveActive_Error" 1 "InactiveActive_Active" 0 "InactiveActive_Inactive" ;
VAL_ 1041 TransmissionOilTempHigh_ISig_2 7 "TransmissionOilTempHigh_NotAvailable" 6 "TransmissionOilTempHigh_ErrorIndicator" 5 "TransmissionOilTempHigh_SpareValue_02" 4 "TransmissionOilTempHigh_SpareValue_01" 3 "TransmissionOilTempHigh_SpareValue" 2 "TransmissionOilTempHigh_ActiveVeryHighTemp" 1 "TransmissionOilTempHigh_ActiveHighTemp" 0 "TransmissionOilTempHigh_Inactive" ;
VAL_ 1041 TrafficSitPathExecSta_Type 255 "TrafficSitEventType_NotAvailable" 254 "TrafficSitEventType_Error" 253 "TrafficSitEventType_NotUsed3" 252 "TrafficSitEventType_NotUsed2" 251 "TrafficSitEventType_NotUsed1" 250 "TrafficSitEventType_GeneralEvent" 249 "TrafficSitEventType_spare242" 248 "TrafficSitEventType_spare241" 247 "TrafficSitEventType_spare240" 246 "TrafficSitEventType_spare239" 245 "TrafficSitEventType_spare238" 244 "TrafficSitEventType_spare237" 243 "TrafficSitEventType_spare236" 242 "TrafficSitEventType_spare235" 241 "TrafficSitEventType_spare234" 240 "TrafficSitEventType_spare233" 239 "TrafficSitEventType_spare232" 238 "TrafficSitEventType_spare231" 237 "TrafficSitEventType_spare230" 236 "TrafficSitEventType_spare229" 235 "TrafficSitEventType_spare228" 234 "TrafficSitEventType_spare227" 233 "TrafficSitEventType_spare226" 232 "TrafficSitEventType_spare225" 231 "TrafficSitEventType_spare224" 230 "TrafficSitEventType_spare223" 229 "TrafficSitEventType_spare222" 228 "TrafficSitEventType_spare221" 227 "TrafficSitEventType_spare220" 226 "TrafficSitEventType_spare219" 225 "TrafficSitEventType_spare218" 224 "TrafficSitEventType_spare217" 223 "TrafficSitEventType_spare216" 222 "TrafficSitEventType_spare215" 221 "TrafficSitEventType_spare214" 220 "TrafficSitEventType_spare213" 219 "TrafficSitEventType_spare212" 218 "TrafficSitEventType_spare211" 217 "TrafficSitEventType_spare210" 216 "TrafficSitEventType_spare209" 215 "TrafficSitEventType_spare208" 214 "TrafficSitEventType_spare207" 213 "TrafficSitEventType_spare206" 212 "TrafficSitEventType_spare205" 211 "TrafficSitEventType_spare204" 210 "TrafficSitEventType_spare203" 209 "TrafficSitEventType_spare202" 208 "TrafficSitEventType_spare201" 207 "TrafficSitEventType_spare200" 206 "TrafficSitEventType_spare199" 205 "TrafficSitEventType_spare198" 204 "TrafficSitEventType_spare197" 203 "TrafficSitEventType_spare196" 202 "TrafficSitEventType_spare195" 201 "TrafficSitEventType_spare194" 200 "TrafficSitEventType_spare193" 199 "TrafficSitEventType_spare192" 198 "TrafficSitEventType_spare191" 197 "TrafficSitEventType_spare190" 196 "TrafficSitEventType_spare189" 195 "TrafficSitEventType_spare188" 194 "TrafficSitEventType_spare187" 193 "TrafficSitEventType_spare186" 192 "TrafficSitEventType_spare185" 191 "TrafficSitEventType_spare184" 190 "TrafficSitEventType_spare183" 189 "TrafficSitEventType_spare182" 188 "TrafficSitEventType_spare181" 187 "TrafficSitEventType_spare180" 186 "TrafficSitEventType_spare179" 185 "TrafficSitEventType_spare178" 184 "TrafficSitEventType_spare177" 183 "TrafficSitEventType_spare176" 182 "TrafficSitEventType_spare175" 181 "TrafficSitEventType_spare174" 180 "TrafficSitEventType_spare173" 179 "TrafficSitEventType_spare172" 178 "TrafficSitEventType_spare171" 177 "TrafficSitEventType_spare170" 176 "TrafficSitEventType_spare169" 175 "TrafficSitEventType_spare168" 174 "TrafficSitEventType_spare167" 173 "TrafficSitEventType_spare166" 172 "TrafficSitEventType_spare165" 171 "TrafficSitEventType_spare164" 170 "TrafficSitEventType_spare163" 169 "TrafficSitEventType_spare162" 168 "TrafficSitEventType_spare161" 167 "TrafficSitEventType_spare160" 166 "TrafficSitEventType_spare159" 165 "TrafficSitEventType_spare158" 164 "TrafficSitEventType_spare157" 163 "TrafficSitEventType_spare156" 162 "TrafficSitEventType_spare155" 161 "TrafficSitEventType_spare154" 160 "TrafficSitEventType_spare153" 159 "TrafficSitEventType_spare152" 158 "TrafficSitEventType_spare151" 157 "TrafficSitEventType_spare150" 156 "TrafficSitEventType_spare149" 155 "TrafficSitEventType_spare148" 154 "TrafficSitEventType_spare147" 153 "TrafficSitEventType_spare146" 152 "TrafficSitEventType_spare145" 151 "TrafficSitEventType_spare144" 150 "TrafficSitEventType_spare143" 149 "TrafficSitEventType_spare142" 148 "TrafficSitEventType_spare141" 147 "TrafficSitEventType_spare140" 146 "TrafficSitEventType_spare139" 145 "TrafficSitEventType_spare138" 144 "TrafficSitEventType_spare137" 143 "TrafficSitEventType_spare136" 142 "TrafficSitEventType_spare135" 141 "TrafficSitEventType_spare134" 140 "TrafficSitEventType_spare133" 139 "TrafficSitEventType_spare132" 138 "TrafficSitEventType_spare131" 137 "TrafficSitEventType_spare130" 136 "TrafficSitEventType_spare129" 135 "TrafficSitEventType_spare128" 134 "TrafficSitEventType_spare127" 133 "TrafficSitEventType_spare126" 132 "TrafficSitEventType_spare125" 131 "TrafficSitEventType_spare124" 130 "TrafficSitEventType_spare123" 129 "TrafficSitEventType_spare122" 128 "TrafficSitEventType_spare121" 127 "TrafficSitEventType_spare120" 126 "TrafficSitEventType_spare119" 125 "TrafficSitEventType_spare118" 124 "TrafficSitEventType_spare117" 123 "TrafficSitEventType_spare116" 122 "TrafficSitEventType_spare115" 121 "TrafficSitEventType_spare114" 120 "TrafficSitEventType_spare113" 119 "TrafficSitEventType_spare112" 118 "TrafficSitEventType_spare111" 117 "TrafficSitEventType_spare110" 116 "TrafficSitEventType_spare109" 115 "TrafficSitEventType_spare108" 114 "TrafficSitEventType_spare107" 113 "TrafficSitEventType_spare106" 112 "TrafficSitEventType_spare105" 111 "TrafficSitEventType_spare104" 110 "TrafficSitEventType_spare103" 109 "TrafficSitEventType_spare102" 108 "TrafficSitEventType_spare101" 107 "TrafficSitEventType_spare100" 106 "TrafficSitEventType_spare99" 105 "TrafficSitEventType_spare98" 104 "TrafficSitEventType_spare97" 103 "TrafficSitEventType_spare96" 102 "TrafficSitEventType_spare95" 101 "TrafficSitEventType_spare94" 100 "TrafficSitEventType_spare93" 99 "TrafficSitEventType_spare92" 98 "TrafficSitEventType_spare91" 97 "TrafficSitEventType_spare90" 96 "TrafficSitEventType_spare89" 95 "TrafficSitEventType_spare88" 94 "TrafficSitEventType_spare87" 93 "TrafficSitEventType_spare86" 92 "TrafficSitEventType_spare85" 91 "TrafficSitEventType_spare84" 90 "TrafficSitEventType_spare83" 89 "TrafficSitEventType_spare82" 88 "TrafficSitEventType_spare81" 87 "TrafficSitEventType_spare80" 86 "TrafficSitEventType_spare79" 85 "TrafficSitEventType_spare78" 84 "TrafficSitEventType_spare77" 83 "TrafficSitEventType_spare76" 82 "TrafficSitEventType_spare75" 81 "TrafficSitEventType_spare74" 80 "TrafficSitEventType_spare73" 79 "TrafficSitEventType_spare72" 78 "TrafficSitEventType_spare71" 77 "TrafficSitEventType_spare70" 76 "TrafficSitEventType_spare69" 75 "TrafficSitEventType_spare68" 74 "TrafficSitEventType_spare67" 73 "TrafficSitEventType_spare66" 72 "TrafficSitEventType_spare65" 71 "TrafficSitEventType_spare64" 70 "TrafficSitEventType_spare63" 69 "TrafficSitEventType_spare62" 68 "TrafficSitEventType_spare61" 67 "TrafficSitEventType_spare60" 66 "TrafficSitEventType_spare59" 65 "TrafficSitEventType_spare58" 64 "TrafficSitEventType_spare57" 63 "TrafficSitEventType_spare56" 62 "TrafficSitEventType_spare55" 61 "TrafficSitEventType_spare54" 60 "TrafficSitEventType_spare53" 59 "TrafficSitEventType_spare52" 58 "TrafficSitEventType_spare51" 57 "TrafficSitEventType_spare50" 56 "TrafficSitEventType_spare49" 55 "TrafficSitEventType_spare48" 54 "TrafficSitEventType_spare47" 53 "TrafficSitEventType_spare46" 52 "TrafficSitEventType_spare45" 51 "TrafficSitEventType_spare44" 50 "TrafficSitEventType_spare43" 49 "TrafficSitEventType_spare42" 48 "TrafficSitEventType_spare41" 47 "TrafficSitEventType_spare40" 46 "TrafficSitEventType_spare39" 45 "TrafficSitEventType_spare38" 44 "TrafficSitEventType_spare37" 43 "TrafficSitEventType_spare36" 42 "TrafficSitEventType_spare35" 41 "TrafficSitEventType_spare34" 40 "TrafficSitEventType_spare33" 39 "TrafficSitEventType_spare32" 38 "TrafficSitEventType_spare31" 37 "TrafficSitEventType_spare30" 36 "TrafficSitEventType_spare29" 35 "TrafficSitEventType_spare28" 34 "TrafficSitEventType_spare27" 33 "TrafficSitEventType_spare26" 32 "TrafficSitEventType_spare25" 31 "TrafficSitEventType_spare24" 30 "TrafficSitEventType_spare23" 29 "TrafficSitEventType_spare22" 28 "TrafficSitEventType_spare21" 27 "TrafficSitEventType_spare20" 26 "TrafficSitEventType_spare19" 25 "TrafficSitEventType_spare18" 24 "TrafficSitEventType_spare17" 23 "TrafficSitEventType_spare16" 22 "TrafficSitEventType_spare15" 21 "TrafficSitEventType_spare14" 20 "TrafficSitEventType_spare13" 19 "TrafficSitEventType_spare12" 18 "TrafficSitEventType_spare11" 17 "TrafficSitEventType_spare10" 16 "TrafficSitEventType_spare9" 15 "TrafficSitEventType_spare8" 14 "TrafficSitEventType_spare7" 13 "TrafficSitEventType_spare6" 12 "TrafficSitEventType_spare5" 11 "TrafficSitEventType_spare4" 10 "TrafficSitEventType_spare3" 9 "TrafficSitEventType_spare2" 8 "TrafficSitEventType_spare1" 7 "TrafficSitEventType_NarrowRoad" 6 "TrafficSitEventType_TrafficJam_OR_SlowTraffic" 5 "TrafficSitEventType_Crossing" 4 "TrafficSitEventType_Roundabout" 3 "TrafficSitEventType_CurveRight" 2 "TrafficSitEventType_CurveLeft" 1 "TrafficSitEventType_SpeedLimit" 0 "TrafficSitEventType_NoEvent" ;
VAL_ 1041 EcoCruiseStatus 7 "EcoCruiseStatus_NotAvailable" 6 "EcoCruiseStatus_Error" 5 "EcoCruiseStatus_Spare02" 4 "EcoCruiseStatus_Spare01" 3 "EcoCruiseStatus_Active_HillTorqueDecidesTorqueReduction" 2 "EcoCruiseStatus_TemporarilyInactive" 1 "EcoCruiseStatus_Active" 0 "EcoCruiseStatus_Inactive" ;
VAL_ 1041 GearShiftingRec_Steps_ISig_2 7 "GearShiftingSteps_NotAvailable" 6 "GearShiftingSteps_Error" 5 "GearShiftingSteps_6step" 4 "GearShiftingSteps_5step" 3 "GearShiftingSteps_4step" 2 "GearShiftingSteps_3step" 1 "GearShiftingSteps_2step" 0 "GearShiftingSteps_1step" ;
VAL_ 516 ClutchOverloadStatus_ISig_2 3 "ClutchOverloadStatus_NotAvailable" 2 "ClutchOverloadStatus_Error" 1 "ClutchOverloadStatus_Overloaded" 0 "ClutchOverloadStatus_NotOverloaded" ;
VAL_ 516 TransmissionAirPressureLow_ISig_ 3 "TransmissionAirPressureLow_NotAvailable" 2 "TransmissionAirPressureLow_Error" 1 "TransmissionAirPressureLow_AirPressureLow" 0 "TransmissionAirPressureLow_AirPressureOk" ;
VAL_ 516 ACC_SGO_TransmissionStatus 7 "ACC_SGO_TransmissionStatus_NotAvailable" 6 "ACC_SGO_TransmissionStatus_Error" 5 "ACC_SGO_TransmissionStatus_Spare2" 4 "ACC_SGO_TransmissionStatus_ReadyForTakeOff" 3 "ACC_SGO_TransmissionStatus_LowestPossibleSpeedReached" 2 "ACC_SGO_TransmissionStatus_Normal" 1 "ACC_SGO_TransmissionStatus_Take_off_InProgress" 0 "ACC_SGO_TransmissionStatus_ACC_SGO_CanNotBeSupported" ;
VAL_ 516 SGoTransmissionSt 7 "SGoTransmissionSt_NotAvailable" 6 "SGoTransmissionSt_Error" 5 "SGoTransmissionSt_SpeedControl" 4 "SGoTransmissionSt_ReadyForTakeOff" 3 "SGoTransmissionSt_LowestPossibleSpeedReached" 2 "SGoTransmissionSt_Normal" 1 "SGoTransmissionSt_TakeOffInProgress" 0 "SGoTransmissionSt_SGOCanNotBeSupported" ;
VAL_ 516 TransmissionSystemPowerDownAck 3 "TransmissionSystemPowerDownAck_DontCare" 2 "TransmissionSystemPowerDownAck_NotDefined" 1 "TransmissionSystemPowerDownAck_OKToPowerDownTECU" 0 "TransmissionSystemPowerDownAck_NotOKToPowerDownTECU" ;
VAL_ 516 DirectionGearAllowed 7 "DirectionGearAllowed_NotAvailable" 6 "DirectionGearAllowed_Error" 5 "DirectionGearAllowed_NotUsed_01" 4 "DirectionGearAllowed_NotUsed" 3 "DirectionGearAllowed_ForwardOrReverseGearAllowed" 2 "DirectionGearAllowed_ReverseGearAllowed" 1 "DirectionGearAllowed_ForwardGearAllowed" 0 "DirectionGearAllowed_NoChangePossible" ;
VAL_ 516 TransmEngineStop_req 3 "InactiveActive_NotAvailable" 2 "InactiveActive_Error" 1 "InactiveActive_Active" 0 "InactiveActive_Inactive" ;
VAL_ 516 Pto2Consent 3 "PtoConsent_NotAvailable" 2 "PtoConsent_Error" 1 "PtoConsent_ConsentGivenPTODriveMayBeEngaged" 0 "PtoConsent_ConsentNotGivenPTODriveShouldNotBeEngaged" ;
VAL_ 516 EcoRollActiveStatus_ISig_2 3 "InactiveActive_NotAvailable" 2 "InactiveActive_Error" 1 "InactiveActive_Active" 0 "InactiveActive_Inactive" ;
VAL_ 516 GearBoxUnlockAuth_rqst 3 "GearBoxUnlockAuth_rqst_NotAvaiable" 2 "GearBoxUnlockAuth_rqst_Error" 1 "GearBoxUnlockAuth_rqst_GearEngagementRequested" 0 "GearBoxUnlockAuth_rqst_GearEngagementNotRequested" ;
VAL_ 516 Pto1Consent 3 "PtoConsent_NotAvailable" 2 "PtoConsent_Error" 1 "PtoConsent_ConsentGivenPTODriveMayBeEngaged" 0 "PtoConsent_ConsentNotGivenPTODriveShouldNotBeEngaged" ;
VAL_ 516 HorizonRetransmissionReq 3 "OffOn_NotAvailable" 2 "OffOn_Error" 1 "OffOn_On" 0 "OffOn_Off" ;
VAL_ 519 PS_SevereEngAndBrkOverspdWarn_IS 3 "InactiveActiveSpare_NotAvailable" 2 "InactiveActiveSpare_Spare" 1 "InactiveActiveSpare_Active" 0 "InactiveActiveSpare_Inactive" ;
VAL_ 519 PS_EngineBrakeOverSpeedWarning_I 3 "InactiveActiveSpare_NotAvailable" 2 "InactiveActiveSpare_Spare" 1 "InactiveActiveSpare_Active" 0 "InactiveActiveSpare_Inactive" ;
VAL_ 519 PS_EngOverSpeedSevereWarning_ISi 3 "InactiveActiveSpare_NotAvailable" 2 "InactiveActiveSpare_Spare" 1 "InactiveActiveSpare_Active" 0 "InactiveActiveSpare_Inactive" ;
VAL_ 1098 AltFlagDiffIndication 3 "FalseTrue_NotAvaiable" 2 "FalseTrue_Error" 1 "FalseTrue_True" 0 "FalseTrue_False" ;
VAL_ 1098 AltFlagElectricalError 3 "FalseTrue_NotAvaiable" 2 "FalseTrue_Error" 1 "FalseTrue_True" 0 "FalseTrue_False" ;
VAL_ 1098 WheelSlipControllerMode_ISig_2 7 "WheelSlipCntrlMode_NotAvailable" 6 "WheelSlipCntrlMode_Error" 5 "WheelSlipCntrlMode_Spare2" 4 "WheelSlipCntrlMode_Spare1" 3 "WheelSlipCntrlMode_Disabled" 2 "WheelSlipCntrlMode_EnabledActiveBrakingSlipCntrl" 1 "WheelSlipCntrlMode_EnabledActiveTractionSlipCntrl" 0 "WheelSlipCntrlMode_EnabledPassive" ;
VAL_ 1098 AltFlagDeexcitation 3 "FalseTrue_NotAvaiable" 2 "FalseTrue_Error" 1 "FalseTrue_True" 0 "FalseTrue_False" ;
VAL_ 1098 AltFlagHT 3 "FalseTrue_NotAvaiable" 2 "FalseTrue_Error" 1 "FalseTrue_True" 0 "FalseTrue_False" ;
VAL_ 1098 AltMultiplexInfoTx_SelectedInfo 15 "AltMultiplexSelectedInfo_NotAvailable" 14 "AltMultiplexSelectedInfo_Error" 13 "AltMultiplexSelectedInfo_Spare6" 12 "AltMultiplexSelectedInfo_Spare5" 11 "AltMultiplexSelectedInfo_Spare4" 10 "AltMultiplexSelectedInfo_Spare3" 9 "AltMultiplexSelectedInfo_Spare2" 8 "AltMultiplexSelectedInfo_Spare1" 7 "AltMultiplexSelectedInfo_0x00_3" 6 "AltMultiplexSelectedInfo_ReservedForManufacturer" 5 "AltMultiplexSelectedInfo_0x00_2" 4 "AltMultiplexSelectedInfo_NGen" 3 "AltMultiplexSelectedInfo_IC_temperature" 2 "AltMultiplexSelectedInfo_VoltageMeasured" 1 "AltMultiplexSelectedInfo_VoltageSet" 0 "AltMultiplexSelectedInfo_0x00_1" ;
VAL_ 1098 DeCompActive_ISig_2 3 "NotActiveActive_NotAvailable" 2 "NotActiveActive_Error" 1 "NotActiveActive_Active" 0 "NotActiveActive_NotActive" ;
VAL_ 1098 AltCommunicationError 3 "FalseTrue_NotAvaiable" 2 "FalseTrue_Error" 1 "FalseTrue_True" 0 "FalseTrue_False" ;
VAL_ 1098 AltFlagMechanicalStatus 3 "FalseTrue_NotAvaiable" 2 "FalseTrue_Error" 1 "FalseTrue_True" 0 "FalseTrue_False" ;
VAL_ 1098 AltFlagTimeout 3 "FalseTrue_NotAvaiable" 2 "FalseTrue_Error" 1 "FalseTrue_True" 0 "FalseTrue_False" ;
VAL_ 1288 MIDistinctWarningExtEMS_ISig_2 15 "MIDistinctWarningExt_NotAvailable" 14 "MIDistinctWarningExt_Error" 3 "MIDistinctWarningExt_ContinuousMISteady" 2 "MIDistinctWarningExt_ShortMI3Flash" 1 "MIDistinctWarningExt_OnDemandMI2Flash" 0 "MIDistinctWarningExt_Off1Flash" ;
VAL_ 1288 TorqueReductionStatus_OBD_ISig_2 7 "TorqueReductionStatus_OBD_NotAvailable" 6 "TorqueReductionStatus_OBD_Error" 5 "TorqueReductionStatus_OBD_Spare_01" 4 "TorqueReductionStatus_OBD_Spare" 3 "TorqueReductionStatus_OBD_TorqueReductionActive" 2 "TorqueReductionStatus_OBD_TorqueReductionActiveNextStandstill" 1 "TorqueReductionStatus_OBD_Pending" 0 "TorqueReductionStatus_OBD_NotActive" ;
VAL_ 1288 MIStatus 3 "OffOn_NotAvailable" 2 "OffOn_Error" 1 "OffOn_On" 0 "OffOn_Off" ;
VAL_ 1288 SCROperatorInducementSeverity_IS 7 "SCROperatorInducementSeverity_NotAvailable" 6 "SCROperatorInducementSeverity_Reserved" 5 "SCROperatorInducementSeverity_SevereInducementActive" 4 "SCROperatorInducementSeverity_SevereIndEnabledWaitActCondition" 3 "SCROperatorInducementSeverity_IndLevel3LowLevelInducementActive" 2 "SCROperatorInducementSeverity_IndLevel2IntensiveWarning" 1 "SCROperatorInducementSeverity_IndLevel1InitialWarning" 0 "SCROperatorInducementSeverity_NoInducementActive" ;
VAL_ 1288 FuelOperatorDeratingSeverity_ISi 7 "FuelOperatorDeratingSeverity_NotAvailable" 6 "FuelOperatorDeratingSeverity_TemporaryOverrideOfDerating" 5 "FuelOperatorDeratingSeverity_SevereDerate" 4 "FuelOperatorDeratingSeverity_SevereDeratePending" 3 "FuelOperatorDeratingSeverity_EngineDerate" 2 "FuelOperatorDeratingSeverity_EngineDeratePending" 1 "FuelOperatorDeratingSeverity_Warning" 0 "FuelOperatorDeratingSeverity_NoDeratingActive" ;
VAL_ 1288 MIDistinctWarning_ISig_2 3 "OffOn_NotAvailable" 2 "OffOn_Error" 1 "OffOn_On" 0 "OffOn_Off" ;
VAL_ 1288 SCROperatorInducementReason_ISig 7 "SCROperatorInducementReason_NotAvailable" 6 "SCROperatorInducementReason_Error" 5 "SCROperatorInducementReason_Spare" 4 "SCROperatorInducementReason_Tampering" 3 "SCROperatorInducementReason_IncorrectConsumption" 2 "SCROperatorInducementReason_IncorrectQuality" 1 "SCROperatorInducementReason_ReagentLevelLow" 0 "SCROperatorInducementReason_OK" ;
VAL_ 1288 MIStatusExtEMS_ISig_2 3 "MIStatusExt_NotAvailable" 2 "MIStatusExt_Error" 1 "MIStatusExt_Ready" 0 "MIStatusExt_NotReady5Flash" ;
VAL_ 1288 FuelOperatorDeratingReason_ISig_ 3 "FuelOperatorDeratingReason_NotAvailable" 2 "FuelOperatorDeratingReason_IncorrectQuality" 1 "FuelOperatorDeratingReason_IncorrectFuelBlend" 0 "FuelOperatorDeratingReason_FuelBlendOK" ;
VAL_ 1282 LNGOperatorInducementReason_ISig 7 "LNGOperatorInducementReason_NotAvailable" 6 "LNGOperatorInducementReason_Error" 5 "LNGOperatorInducementReason_Spare2" 4 "LNGOperatorInducementReason_Spare1" 3 "LNGOperatorInducementReason_IncorrectConsumption" 2 "LNGOperatorInducementReason_GasSupplyMalfunction" 1 "LNGOperatorInducementReason_LNGLevelLow" 0 "LNGOperatorInducementReason_OK" ;
VAL_ 1282 EngineFuelMode 3 "FuelMode_NotAvailable" 2 "FuelMode_Error" 1 "FuelMode_RunOnDiesel" 0 "FuelMode_RunOnGas" ;
VAL_ 1391 OilPrediction_Status 7 "OilStatus_NotAvailable" 6 "OilStatus_Error" 5 "OilStatus_Spare" 4 "OilStatus_Ok" 3 "OilStatus_ServiceNearDue" 2 "OilStatus_ServiceDue" 1 "OilStatus_ServiceOverDue" 0 "OilStatus_NotActive" ;
VAL_ 1391 OilPrediction_Quality 7 "OilQuality_NotAvailable" 6 "OilQuality_Error" 5 "OilQuality_NoSelectionMade" 4 "OilQuality_VDS4" 3 "OilQuality_VDS3" 2 "OilQuality_VDS5" 1 "OilQuality_VDSVDS3WithFixedInterval" 0 "OilQuality_NonVDS_VDS4WithFixedInterval" ;
VAL_ 1279 AirFilterPressureDrop 7 "AirFilterPressureDrop_NotAvailable" 6 "AirFilterPressureDrop_Error" 5 "AirFilterPressureDrop_AirFilterPressureDropLevel5" 4 "AirFilterPressureDrop_AirFilterPressureDropLevel4" 3 "AirFilterPressureDrop_AirFilterPressureDropLevel3" 2 "AirFilterPressureDrop_AirFilterPressureDropLevel2" 1 "AirFilterPressureDrop_AirFilterPressureDropLevel1" 0 "AirFilterPressureDrop_OK" ;
VAL_ 1279 FuelFilterClogged_ISig_2 7 "LevelLow3bit_NotAvailable" 6 "LevelLow3bit_Error" 5 "LevelLow3bit_LowLevel5" 4 "LevelLow3bit_LowLevel4" 3 "LevelLow3bit_LowLevel3" 2 "LevelLow3bit_LowLevel2" 1 "LevelLow3bit_LowLevel1" 0 "LevelLow3bit_OK" ;
VAL_ 1279 DrainPrimingStatus_ISig_2 7 "DrainPrimingStatus_NotAvailable" 6 "DrainPrimingStatus_Error" 5 "DrainPrimingStatus_SpareValue_01" 4 "DrainPrimingStatus_SpareValue" 3 "DrainPrimingStatus_DrainingActive" 2 "DrainPrimingStatus_PrimingActive" 1 "DrainPrimingStatus_DrainingPrimingNotAllowed" 0 "DrainPrimingStatus_DrainingPrimingInactive" ;
VAL_ 1279 CoolantLevelLow 7 "LevelLow3bit_NotAvailable" 6 "LevelLow3bit_Error" 5 "LevelLow3bit_LowLevel5" 4 "LevelLow3bit_LowLevel4" 3 "LevelLow3bit_LowLevel3" 2 "LevelLow3bit_LowLevel2" 1 "LevelLow3bit_LowLevel1" 0 "LevelLow3bit_OK" ;
VAL_ 1279 EngineProtDerateStat 3 "InactiveActive_NotAvailable" 2 "InactiveActive_Error" 1 "InactiveActive_Active" 0 "InactiveActive_Inactive" ;
VAL_ 1279 FuelEcoEngStatus 3 "InactiveActive_NotAvailable" 2 "InactiveActive_Error" 1 "InactiveActive_Active" 0 "InactiveActive_Inactive" ;
VAL_ 1279 OilLevelLow_ISig_2 7 "LevelLow3bit_NotAvailable" 6 "LevelLow3bit_Error" 5 "LevelLow3bit_LowLevel5" 4 "LevelLow3bit_LowLevel4" 3 "LevelLow3bit_LowLevel3" 2 "LevelLow3bit_LowLevel2" 1 "LevelLow3bit_LowLevel1" 0 "LevelLow3bit_OK" ;
VAL_ 1279 AutoWheelBrakesStatus_ISig_2 7 "AutoWheelBrakesStatus_NotAvailable" 6 "AutoWheelBrakesStatus_Error" 5 "AutoWheelBrakesStatus_Spare3" 4 "AutoWheelBrakesStatus_Spare2" 3 "AutoWheelBrakesStatus_AWBActive" 2 "AutoWheelBrakesStatus_ReducedAutoBraking_WithoutSerBrkDemand" 1 "AutoWheelBrakesStatus_FullAutoBraking_withSerBrksDemand" 0 "AutoWheelBrakesStatus_NoAutoBrakingActive" ;
VAL_ 1279 EngineFanOverspeed_ISig_2 3 "NoYes_NotAvailable" 2 "NoYes_Error" 1 "NoYes_Yes" 0 "NoYes_No" ;
VAL_ 1279 InletAirHeaterStatus1_ISig_2 3 "OffOn_NotAvailable" 2 "OffOn_Error" 1 "OffOn_On" 0 "OffOn_Off" ;
VAL_ 1279 TopGearMode 3 "TopGearMode_NotAvailable" 2 "TopGearMode_Error" 1 "TopGearMode_Active" 0 "TopGearMode_NotActive" ;
VAL_ 1279 CoolantTempHigh_ISig_2 7 "TempHigh3bit_NotAvailable" 6 "TempHigh3bit_Error" 5 "TempHigh3bit_HighLevel5" 4 "TempHigh3bit_HighLevel4" 3 "TempHigh3bit_HighLevel3" 2 "TempHigh3bit_HighLevel2" 1 "TempHigh3bit_HighLevel1" 0 "TempHigh3bit_OK" ;
VAL_ 1279 OilPressureLow_ISig_2 7 "LevelLow3bit_NotAvailable" 6 "LevelLow3bit_Error" 5 "LevelLow3bit_LowLevel5" 4 "LevelLow3bit_LowLevel4" 3 "LevelLow3bit_LowLevel3" 2 "LevelLow3bit_LowLevel2" 1 "LevelLow3bit_LowLevel1" 0 "LevelLow3bit_OK" ;
VAL_ 1279 DPF_ParkedRegenStatus_ISig_2 7 "ParkedRegenStatus_NotAvailable" 6 "ParkedRegenStatus_Error" 5 "ParkedRegenStatus_Spare2" 4 "ParkedRegenStatus_HCRegenOngoing" 3 "ParkedRegenStatus_ParkedRegenOngoing" 2 "ParkedRegenStatus_Aborted" 1 "ParkedRegenStatus_Completed" 0 "ParkedRegenStatus_NoInformation" ;
VAL_ 1279 StarterMotorReset_ack 3 "NokOk_NotAvailable" 2 "NokOk_Error" 1 "NokOk_OK" 0 "NokOk_NOK" ;
VAL_ 1279 DMSDriverFollow 3 "DMSDriverFollow_NotAvailable" 2 "DMSDriverFollow_Error" 1 "DMSDriverFollow_AdviseFollowed" 0 "DMSDriverFollow_AdviseNotFollowed" ;
VAL_ 719 XARActiveControlMode 7 "XARActiveControlMode_NotAvailable" 6 "XARActiveControlMode_Error" 5 "XARActiveControlMode_Spare_2" 4 "XARActiveControlMode_Spare_1" 3 "XARActiveControlMode_CoastingActive" 2 "XARActiveControlMode_DriversAccelerationDemandExecuted" 1 "XARActiveControlMode_AccelerationControlMaximumMode" 0 "XARActiveControlMode_OverrideDisabled" ;
VAL_ 719 WarmUpCycle 3 "WarmUpCycle_NotAvailable" 2 "WarmUpCycle_Error" 1 "WarmUpCycle_TransitionTo1MeansWarmUpCycleOccur" 0 "WarmUpCycle_TransitionTo0MeansWarmUpCycleOccur" ;
VAL_ 719 DPF_LimitedSpeedDuetoInhibit_ISi 7 "LimitedSpeedInhibit_NotAvailable" 6 "LimitedSpeedInhibit_Error" 5 "LimitedSpeedInhibit_Spare2" 4 "LimitedSpeedInhibit_Spare1" 3 "LimitedSpeedInhibit_SpeedNotLimited_InhibitActive" 2 "LimitedSpeedInhibit_SpeedNotLimited_InhibitDenied" 1 "LimitedSpeedInhibit_SpeedLimited_InhibitionActive" 0 "LimitedSpeedInhibit_SpeedNotLimited_NoInhibitRequest" ;
VAL_ 719 CCControllerMode 7 "ControllerMode_Not_availbale" 6 "ControllerMode_Error" 5 "ControllerMode_Spare_01" 4 "ControllerMode_Spare" 3 "ControllerMode_Inhibited" 2 "ControllerMode_Active_no_torque" 1 "ControllerMode_Active_torque" 0 "ControllerMode_Inactive" ;
VAL_ 719 ExhManif_AirInjActive 3 "InhibitedStatus_NotAvailable" 2 "InhibitedStatus_Error" 1 "InhibitedStatus_Inhibited" 0 "InhibitedStatus_NotInhibited" ;
VAL_ 719 CCBControllerMode 7 "ControllerMode_Not_availbale" 6 "ControllerMode_Error" 5 "ControllerMode_Spare_01" 4 "ControllerMode_Spare" 3 "ControllerMode_Inhibited" 2 "ControllerMode_Active_no_torque" 1 "ControllerMode_Active_torque" 0 "ControllerMode_Inactive" ;
VAL_ 719 EngineSystemPowerDownAck 3 "EngineSystemPowerDownAck_NotAvailable" 2 "EngineSystemPowerDownAck_Error" 1 "EngineSystemPowerDownAck_NotOkToPowerDownEMS" 0 "EngineSystemPowerDownAck_OkToPowerDownEMS" ;
VAL_ 719 RegenInhibDueHeight_ISig_2 3 "Inhibit_NotAvailable" 2 "Inhibit_Error" 1 "Inhibit_InhibitActive" 0 "Inhibit_NoInhibit" ;
VAL_ 719 XARSystemState 3 "XARSystemState_NotAvailable" 2 "XARSystemState_Error" 1 "XARSystemState_NoExternalAccelerationDemandWillBeAccepted" 0 "XARSystemState_AnyExternalAccelerationDemandWillBeAccepted" ;
VAL_ 719 EngineStartAuth_rqst 7 "EngineStartAuth_rqst_NotAvailable" 6 "EngineStartAuth_rqst_Error" 5 "EngineStartAuth_rqst_Spare_03" 4 "EngineStartAuth_rqst_Spare_02" 3 "EngineStartAuth_rqst_Spare_01" 2 "EngineStartAuth_rqst_Spare" 1 "EngineStartAuth_rqst_StartingOfTheTruckRequested" 0 "EngineStartAuth_rqst_StartingOfTheTruckNotRequested" ;
VAL_ 719 EngCompartmentStopSwitchStat 3 "EngCompartmentStopSwitchStat_NotAvailable" 2 "EngCompartmentStopSwitchStat_Error" 1 "EngCompartmentStopSwitchStat_ShutdownRequested" 0 "EngCompartmentStopSwitchStat_NoAction" ;
VAL_ 719 PwtEngineTmpryStopAllowed 3 "NotAllowedAllowed_NotAvailable" 2 "NotAllowedAllowed_Error" 1 "NotAllowedAllowed_Allowed" 0 "NotAllowedAllowed_NotAllowed" ;
VAL_ 719 IntakeAirTemperatureAlert 3 "InactiveActive_NotAvailable" 2 "InactiveActive_Error" 1 "InactiveActive_Active" 0 "InactiveActive_Inactive" ;
VAL_ 719 EngineOilTempHigh_ISig_2 7 "TempHigh3bit_NotAvailable" 6 "TempHigh3bit_Error" 5 "TempHigh3bit_HighLevel5" 4 "TempHigh3bit_HighLevel4" 3 "TempHigh3bit_HighLevel3" 2 "TempHigh3bit_HighLevel2" 1 "TempHigh3bit_HighLevel1" 0 "TempHigh3bit_OK" ;
VAL_ 719 XRSLControllerMode_ISig_2 3 "InactiveActive_NotAvailable" 2 "InactiveActive_Error" 1 "InactiveActive_Active" 0 "InactiveActive_Inactive" ;
VAL_ 719 InhibitIdleShutdownStatus 7 "InhibitIdleShutdownStatus_NotAvailableNoInhibit" 6 "InhibitIdleShutdownStatus_ErrorIndicator" 5 "InhibitIdleShutdownStatus_InhibitReasonUndefined" 4 "InhibitIdleShutdownStatus_InhibitReasonReserved_02" 3 "InhibitIdleShutdownStatus_InhibitReasonReserved_01" 2 "InhibitIdleShutdownStatus_InhibitReasonReserved" 1 "InhibitIdleShutdownStatus_InhibitDPFRegeneration" 0 "InhibitIdleShutdownStatus_NoInhibit" ;
VAL_ 719 CrankcasePressureHigh 3 "Warning_NotAvailable" 2 "Warning_Error" 1 "Warning_Warning" 0 "Warning_NoWarning" ;
SIG_GROUP_ 1414 GPSData_sg 1 : GPSData_Altitude GPSData_Time GPSData_AntennaStat GPSData_HDOP GPSData_Longitude GPSData_Latitude GPSData_Direction GPSData_VehSpeed;
SIG_GROUP_ 1249 HillDataCtrlTECU_sg 1 : HillDataCtrlTECU_AckCnt HillDataCtrlTECU_State;
SIG_GROUP_ 1249 OilLevelDrvInstr_sg_ISig_2 1 : OilLevelDrvInstr_StopVehicle_ISi OilLevelDrvInstr_OilTempTxt_ISig OilLevelDrvInstr_Wait60SecTxt_IS OilLevelDrvInstr_ChangeGearTxt_I OilLevelDrvInstr_IncorrEngSpe_IS OilLevelDrvInstr_NotHorizonTxt_I;
SIG_GROUP_ 1041 TrafficSitPathExecSta_sg 1 : TrafficSitPathExecSta_Distance TrafficSitPathExecSta_Type TrafficSitPathExecSta_Speed;
SIG_GROUP_ 1041 GearShiftingRec_sg_ISig_2 1 : GearShiftingRec_Direction_ISig_2 GearShiftingRec_Steps_ISig_2;
SIG_GROUP_ 1098 AltMultiplexInfoTx_sg 1 : AltMultiplexInfoTx_SelectedInfo AltMultiplexInfoTx_Data;
SIG_GROUP_ 1391 OilPrediction_sg 1 : OilPrediction_RemainDist OilPrediction_RemainTime OilPrediction_Status OilPrediction_Quality;
SIG_GROUP_ 719 AirFilter_sg 1 : AirFilter_Pressure AirFilter_AirMassFlowValidated;
SIG_GROUP_ 1519 DiagFaultStat_TECU_sg 1 : DiagFaultStat_TECU_DtcIdB DiagFaultStat_TECU_EcuAdr DiagFaultStat_TECU_DtcIdA DiagFaultStat_TECU_FailTB DiagFaultStat_TECU_FailTA;
SIG_GROUP_ 1511 DiagFaultStat_EMS_sg 1 : DiagFaultStat_EMS_DtcIdB DiagFaultStat_EMS_EcuAdr DiagFaultStat_EMS_DtcIdA DiagFaultStat_EMS_FailTA DiagFaultStat_EMS_FailTB;
